VERSION "ZCU_CANFD1"

NS_ :

BS_ :

BU_ :  ASDM BBM ETC IHU ZCUD ZCUP

BO_ 1384 BcmZCUCANFD1VFCVectFr : 8 BBM
 SG_ VFCVectorBCMBlockID : 1|2@0+ (1.0,0.0) [0.0|3.0] "Unitless" IHU
 SG_ VFCVectorBCMVFCid0 : 2|1@0+ (1,0) [0|1] "" IHU
 SG_ VFCVectorBCMVFCid1 : 3|1@0+ (1,0) [0|1] "" IHU
 SG_ VFCVectorBCMVFCid10 : 12|1@0+ (1,0) [0|1] "" IHU
 SG_ VFCVectorBCMVFCid11 : 13|1@0+ (1,0) [0|1] "" IHU
 SG_ VFCVectorBCMVFCid12 : 14|1@0+ (1,0) [0|1] "" IHU
 SG_ VFCVectorBCMVFCid13 : 15|1@0+ (1,0) [0|1] "" IHU
 SG_ VFCVectorBCMVFCid14 : 16|1@0+ (1,0) [0|1] "" IHU
 SG_ VFCVectorBCMVFCid15 : 17|1@0+ (1,0) [0|1] "" IHU
 SG_ VFCVectorBCMVFCid16 : 18|1@0+ (1,0) [0|1] "" IHU
 SG_ VFCVectorBCMVFCid17 : 19|1@0+ (1,0) [0|1] "" IHU
 SG_ VFCVectorBCMVFCid18 : 20|1@0+ (1,0) [0|1] "" IHU
 SG_ VFCVectorBCMVFCid19 : 21|1@0+ (1,0) [0|1] "" IHU
 SG_ VFCVectorBCMVFCid2 : 4|1@0+ (1,0) [0|1] "" IHU
 SG_ VFCVectorBCMVFCid20 : 22|1@0+ (1,0) [0|1] "" IHU
 SG_ VFCVectorBCMVFCid21 : 23|1@0+ (1,0) [0|1] "" IHU
 SG_ VFCVectorBCMVFCid22 : 24|1@0+ (1,0) [0|1] "" IHU
 SG_ VFCVectorBCMVFCid23 : 25|1@0+ (1,0) [0|1] "" IHU
 SG_ VFCVectorBCMVFCid24 : 26|1@0+ (1,0) [0|1] "" IHU
 SG_ VFCVectorBCMVFCid25 : 27|1@0+ (1,0) [0|1] "" IHU
 SG_ VFCVectorBCMVFCid26 : 28|1@0+ (1,0) [0|1] "" IHU
 SG_ VFCVectorBCMVFCid27 : 29|1@0+ (1,0) [0|1] "" IHU
 SG_ VFCVectorBCMVFCid28 : 30|1@0+ (1,0) [0|1] "" IHU
 SG_ VFCVectorBCMVFCid29 : 31|1@0+ (1,0) [0|1] "" IHU
 SG_ VFCVectorBCMVFCid3 : 5|1@0+ (1,0) [0|1] "" IHU
 SG_ VFCVectorBCMVFCid30 : 32|1@0+ (1,0) [0|1] "" IHU
 SG_ VFCVectorBCMVFCid31 : 33|1@0+ (1,0) [0|1] "" IHU
 SG_ VFCVectorBCMVFCid32 : 34|1@0+ (1,0) [0|1] "" IHU
 SG_ VFCVectorBCMVFCid33 : 35|1@0+ (1,0) [0|1] "" IHU
 SG_ VFCVectorBCMVFCid34 : 36|1@0+ (1,0) [0|1] "" IHU
 SG_ VFCVectorBCMVFCid35 : 37|1@0+ (1,0) [0|1] "" IHU
 SG_ VFCVectorBCMVFCid36 : 38|1@0+ (1,0) [0|1] "" IHU
 SG_ VFCVectorBCMVFCid37 : 39|1@0+ (1,0) [0|1] "" IHU
 SG_ VFCVectorBCMVFCid38 : 40|1@0+ (1,0) [0|1] "" IHU
 SG_ VFCVectorBCMVFCid39 : 41|1@0+ (1,0) [0|1] "" IHU
 SG_ VFCVectorBCMVFCid4 : 6|1@0+ (1,0) [0|1] "" IHU
 SG_ VFCVectorBCMVFCid40 : 42|1@0+ (1,0) [0|1] "" IHU
 SG_ VFCVectorBCMVFCid41 : 43|1@0+ (1,0) [0|1] "" IHU
 SG_ VFCVectorBCMVFCid42 : 44|1@0+ (1,0) [0|1] "" IHU
 SG_ VFCVectorBCMVFCid43 : 45|1@0+ (1,0) [0|1] "" IHU
 SG_ VFCVectorBCMVFCid44 : 46|1@0+ (1,0) [0|1] "" IHU
 SG_ VFCVectorBCMVFCid45 : 47|1@0+ (1,0) [0|1] "" IHU
 SG_ VFCVectorBCMVFCid46 : 48|1@0+ (1,0) [0|1] "" IHU
 SG_ VFCVectorBCMVFCid47 : 49|1@0+ (1,0) [0|1] "" IHU
 SG_ VFCVectorBCMVFCid48 : 50|1@0+ (1,0) [0|1] "" IHU
 SG_ VFCVectorBCMVFCid49 : 51|1@0+ (1,0) [0|1] "" IHU
 SG_ VFCVectorBCMVFCid5 : 7|1@0+ (1,0) [0|1] "" IHU
 SG_ VFCVectorBCMVFCid50 : 52|1@0+ (1,0) [0|1] "" IHU
 SG_ VFCVectorBCMVFCid51 : 53|1@0+ (1,0) [0|1] "" IHU
 SG_ VFCVectorBCMVFCid52 : 54|1@0+ (1,0) [0|1] "" IHU
 SG_ VFCVectorBCMVFCid53 : 55|1@0+ (1,0) [0|1] "" IHU
 SG_ VFCVectorBCMVFCid54 : 56|1@0+ (1,0) [0|1] "" IHU
 SG_ VFCVectorBCMVFCid55 : 57|1@0+ (1,0) [0|1] "" IHU
 SG_ VFCVectorBCMVFCid56 : 58|1@0+ (1,0) [0|1] "" IHU
 SG_ VFCVectorBCMVFCid57 : 59|1@0+ (1,0) [0|1] "" IHU
 SG_ VFCVectorBCMVFCid58 : 60|1@0+ (1,0) [0|1] "" IHU
 SG_ VFCVectorBCMVFCid59 : 61|1@0+ (1,0) [0|1] "" IHU
 SG_ VFCVectorBCMVFCid6 : 8|1@0+ (1,0) [0|1] "" IHU
 SG_ VFCVectorBCMVFCid60 : 62|1@0+ (1,0) [0|1] "" IHU
 SG_ VFCVectorBCMVFCid61 : 63|1@0+ (1,0) [0|1] "" IHU
 SG_ VFCVectorBCMVFCid7 : 9|1@0+ (1,0) [0|1] "" IHU
 SG_ VFCVectorBCMVFCid8 : 10|1@0+ (1,0) [0|1] "" IHU
 SG_ VFCVectorBCMVFCid9 : 11|1@0+ (1,0) [0|1] "" IHU

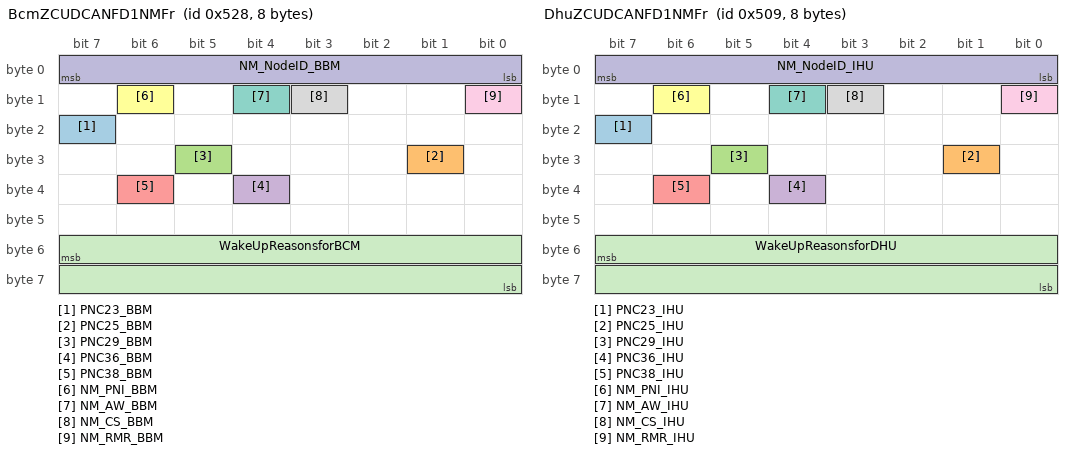
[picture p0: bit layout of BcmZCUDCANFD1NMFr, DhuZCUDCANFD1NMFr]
BO_ 1320 BcmZCUDCANFD1NMFr : 8 BBM
 SG_ PNC23_BBM : 23|1@0+ (1,0) [0|0] "" Vector__XXX
 SG_ PNC25_BBM : 25|1@0+ (1,0) [0|0] "" Vector__XXX
 SG_ PNC29_BBM : 29|1@0+ (1,0) [0|0] "" Vector__XXX
 SG_ PNC36_BBM : 36|1@0+ (1,0) [0|0] "" Vector__XXX
 SG_ PNC38_BBM : 38|1@0+ (1,0) [0|0] "" Vector__XXX
 SG_ NM_PNI_BBM : 14|1@0+ (1,0) [0|0] "" Vector__XXX
 SG_ NM_AW_BBM : 12|1@0+ (1,0) [0|0] "" Vector__XXX
 SG_ NM_CS_BBM : 11|1@0+ (1,0) [0|0] "" Vector__XXX
 SG_ NM_RMR_BBM : 8|1@0+ (1,0) [0|0] "" Vector__XXX
 SG_ NM_NodeID_BBM : 7|8@0+ (1,0) [0|0] "" Vector__XXX

 SG_ WakeUpReasonsforBCM : 55|16@0+ (1,0) [0|65535] "" Vector__XXX

BO_ 87 DhuToAdcuSecOCFr01 : 64 IHU
 SG_ DrvrACCrsSetSpdReq_UB : 28|1@0+ (1,0) [0|1] "" ASDM
 SG_ DrvrACCrsSetSpdReqDrvrACCrsCtrlSetInSpdReq : 7|12@0+ (0.03125,0.0) [0.0|125.0] "m/s" ASDM
 SG_ DrvrACCrsSetSpdReqDrvrCrsSetSpdReq : 31|3@0+ (1,0) [0|7] "" ASDM
 SG_ DrvrACCrsSetSpdReqSetSpdForCrsCtrlFctActive : 11|12@0+ (0.03125,0.0) [0.0|125.0] "m/s" ASDM

BO_ 2015 DhuToAllFuncJ1979OBDZCUCanFD1ReqFr : 8 IHU

BO_ 2047 DhuToAllFuncZCUCANFD1DiagReqFr : 8 IHU

BO_ 1860 DhuToAsdmFlrZCUCANFD1DiagReqFr : 64 IHU

BO_ 1841 DhuToAsdmFsrlZCUCANFD1DiagReqFr : 64 IHU

BO_ 1840 DhuToAsdmFsrrZCUCANFD1DiagReqFr : 64 IHU

BO_ 1872 DhuToAsdmSodlZCUCANFD1DiagReqFr : 64 IHU

BO_ 1873 DhuToAsdmSodrZCUCANFD1DiagReqFr : 64 IHU

BO_ 1793 DhuToAsdmZCUCANFD1DiagReqFr : 64 IHU

BO_ 2023 DhuToBcmJ1979OBDZCUCanFD1ReqFr : 8 IHU

BO_ 1921 DhuToBcmZCUCANFD1DiagReqFr : 64 IHU

BO_ 1925 DhuToPasZCUCANFD1DiagReqFr : 64 IHU

BO_ 1889 DhuToZcudBmsZCUCANFD1DiagReqFr : 64 IHU

BO_ 1808 DhuToZcudEcmZCUCANFD1DiagReqFr : 64 IHU

BO_ 1891 DhuToZcudGcmZCUCANFD1DiagReqFr : 64 IHU

BO_ 1904 DhuToZcudPscmZCUCANFD1DiagReqFr : 64 IHU

BO_ 1811 DhuToZcudRbcmZCUCANFD1DiagReqFr : 64 IHU

BO_ 1906 DhuToZcudSasZCUCANFD1DiagReqFr : 64 IHU

BO_ 1813 DhuToZcudSclZCUCANFD1DiagReqFr : 64 IHU

BO_ 1812 DhuToZcudSumZCUCANFD1DiagReqFr : 64 IHU

BO_ 1826 DhuToZcudWpcZCUCANFD1DiagReqFr : 64 IHU

BO_ 1810 DhuToZcudXcuZCUCANFD1DiagReqFr : 64 IHU

BO_ 488 DhuZCUCANFD1Fr01 : 64 IHU
 SG_ AsyEmgyManoeuvreAidActvSts : 491|1@0+ (1,0) [0|1] "" ASDM
 SG_ AsyEmgyManoeuvreAidActvSts_UB : 490|1@0+ (1,0) [0|1] "" ASDM
 SG_ AsyNoaUpgradeswitch : 489|1@0+ (1,0) [0|1] "" ASDM
 SG_ AsyNoaUpgradeswitch_UB : 488|1@0+ (1,0) [0|1] "" ASDM
 SG_ BSDSwOnOffandWarnType : 35|2@0+ (1,0) [0|3] "" ASDM
 SG_ BSDSwOnOffandWarnType_UB : 24|1@0+ (1,0) [0|1] "" ASDM
 SG_ CamFltsStsFromDHU : 487|2@0+ (1,0) [0|3] "" ASDM
 SG_ CamFltsStsFromDHU_UB : 485|1@0+ (1,0) [0|1] "" ASDM
 SG_ CllsnAidSnvtySeldSts : 482|3@0+ (1,0) [0|7] "" ASDM
 SG_ CllsnAidSnvtySeldSts_UB : 483|1@0+ (1,0) [0|1] "" ASDM
 SG_ CllsnMtgtnActvSeldSts : 495|1@0+ (1,0) [0|1] "" ASDM
 SG_ CllsnMtgtnActvSeldSts_UB : 484|1@0+ (1,0) [0|1] "" ASDM
 SG_ CmftBrkStopSwtSts : 494|1@0+ (1,0) [0|1] "" BBM
 SG_ CmftBrkStopSwtSts_UB : 312|1@0+ (1,0) [0|1] "" BBM
 SG_ CrsCtrlTiGapAdjReq : 499|3@0+ (1,0) [0|7] "" ASDM
 SG_ CrsCtrlTiGapAdjReq_UB : 496|1@0+ (1,0) [0|1] "" ASDM
 SG_ CurrentRoadLvl : 39|4@0+ (1,0) [0|15] "" ASDM,ZCUD
 SG_ CurrentRoadLvl_UB : 25|1@0+ (1,0) [0|1] "" ASDM,ZCUD
 SG_ DrvOffReq : 27|1@0+ (1,0) [0|1] "" ASDM
 SG_ DrvOffReq_UB : 26|1@0+ (1,0) [0|1] "" ASDM
 SG_ DrvrCrsCtrlFctActvReq : 493|2@0+ (1,0) [0|3] "" ASDM
 SG_ DrvrCrsCtrlFctActvReq_UB : 508|1@0+ (1,0) [0|1] "" ASDM
 SG_ DrvrDecStsFromDHU : 511|3@0+ (1,0) [0|7] "" ASDM
 SG_ DrvrDecStsFromDHU_UB : 507|1@0+ (1,0) [0|1] "" ASDM
 SG_ DrvrPfmncAlrmReqFromDHU : 59|3@0+ (1,0) [0|7] "" ASDM,ZCUD,ZCUP
 SG_ DrvrPfmncAlrmReqFromDHU_UB : 506|1@0+ (1,0) [0|1] "" ASDM,ZCUD,ZCUP
 SG_ DrvrPfmncSwitchStsFromDHU : 71|3@0+ (1,0) [0|7] "" ASDM
 SG_ DrvrPfmncSwitchStsFromDHU_UB : 505|1@0+ (1,0) [0|1] "" ASDM
 SG_ EmgyLaneKeepAidActvSts : 56|1@0+ (1,0) [0|1] "" ASDM
 SG_ EmgyLaneKeepAidActvSts_UB : 504|1@0+ (1,0) [0|1] "" ASDM
 SG_ EyeGazeDirVecFromDHU_UB : 68|1@0+ (1,0) [0|1] "" ASDM
 SG_ EyeGazeDirVecFromDHUX : 79|16@0+ (1.0,-32767.0) [-32767.0|32768.0] "Unitless" ASDM
 SG_ EyeGazeDirVecFromDHUY : 95|16@0+ (1.0,-32767.0) [-32767.0|32768.0] "Unitless" ASDM
 SG_ EyeGazeDirVecFromDHUZ : 111|16@0+ (1.0,-32767.0) [-32767.0|32768.0] "Unitless" ASDM
 SG_ EyeGazeFromDHU_UB : 67|1@0+ (1,0) [0|1] "" ASDM
 SG_ EyeGazeFromDHUEyeGazeZone : 143|5@0+ (1,0) [0|31] "" ASDM
 SG_ EyeGazeFromDHUEyeGazeZoneTime : 127|16@0+ (1.0,0.0) [0.0|65535.0] "Milliseconds" ASDM
 SG_ EyeGzaeDirOriFromDHU_UB : 66|1@0+ (1,0) [0|1] "" ASDM
 SG_ EyeGzaeDirOriFromDHUX : 151|16@0+ (1.0,-32767.0) [-32767.0|32768.0] "mm" ASDM
 SG_ EyeGzaeDirOriFromDHUY : 167|16@0+ (1.0,-32767.0) [-32767.0|32768.0] "mm" ASDM
 SG_ EyeGzaeDirOriFromDHUZ : 183|16@0+ (1.0,-32767.0) [-32767.0|32768.0] "mm" ASDM
 SG_ EyeOnRoadFromDHU_UB : 65|1@0+ (1,0) [0|1] "" ASDM
 SG_ EyeOnRoadFromDHUChks : 199|8@0+ (1.0,0.0) [0.0|255.0] "Unitless" ASDM
 SG_ EyeOnRoadFromDHUCntr : 207|4@0+ (1.0,0.0) [0.0|15.0] "Unitless" ASDM
 SG_ EyeOnRoadFromDHUEyesOnRoad : 203|2@0+ (1,0) [0|3] "" ASDM
 SG_ EyeOpenFromDHU_UB : 64|1@0+ (1,0) [0|1] "" ASDM
 SG_ EyeOpenFromDHUEyeOpenDegLe : 215|8@0+ (0.1,0.0) [0.0|25.5] "mm" ASDM
 SG_ EyeOpenFromDHUEyeOpenDegRi : 223|8@0+ (0.1,0.0) [0.0|25.5] "mm" ASDM
 SG_ EyeOpenFromDHUEyeOpenLe : 231|1@0+ (1,0) [0|1] "" ASDM
 SG_ EyeOpenFromDHUEyeOpenRi : 230|1@0+ (1,0) [0|1] "" ASDM
 SG_ EyeOpenFromDHUEyeVisibleLe : 229|1@0+ (1,0) [0|1] "" ASDM
 SG_ EyeOpenFromDHUEyeVisibleRi : 228|1@0+ (1,0) [0|1] "" ASDM
 SG_ EyeOpenFromDHUFaceVisible : 227|1@0+ (1,0) [0|1] "" ASDM
 SG_ HdPosnValidSigFromDHU_UB : 201|1@0+ (1,0) [0|1] "" ASDM
 SG_ HdPosnValidSigFromDHUX : 239|16@0+ (1.0,-32767.0) [-32767.0|32768.0] "mm" ASDM
 SG_ HdPosnValidSigFromDHUY : 255|16@0+ (1.0,-32767.0) [-32767.0|32768.0] "mm" ASDM
 SG_ HdPosnValidSigFromDHUZ : 271|16@0+ (1.0,-32767.0) [-32767.0|32768.0] "mm" ASDM
 SG_ HdRotateAgFromDHU_UB : 200|1@0+ (1,0) [0|1] "" ASDM
 SG_ HdRotateAgFromDHUHdPitchAg : 287|11@0+ (0.1,-90.0) [-90.0|90.0] "Deg" ASDM
 SG_ HdRotateAgFromDHUHdRollAg : 292|11@0+ (0.1,-90.0) [-90.0|90.0] "Deg" ASDM
 SG_ HdRotateAgFromDHUHdYawAg : 311|11@0+ (0.1,-90.0) [-90.0|90.0] "Deg" ASDM
 SG_ HeadGazeDirOriFromDHU_UB : 138|1@0+ (1,0) [0|1] "" ASDM
 SG_ HeadGazeDirOriFromDHUX : 327|16@0+ (1.0,-32767.0) [-32767.0|32768.0] "mm" ASDM
 SG_ HeadGazeDirOriFromDHUY : 343|16@0+ (1.0,-32767.0) [-32767.0|32768.0] "mm" ASDM
 SG_ HeadGazeDirOriFromDHUZ : 359|16@0+ (1.0,-32767.0) [-32767.0|32768.0] "mm" ASDM
 SG_ HeadGazeDirVecFromDHU_UB : 137|1@0+ (1,0) [0|1] "" ASDM
 SG_ HeadGazeDirVecFromDHUX : 375|16@0+ (1.0,-32767.0) [-32767.0|32768.0] "Unitless" ASDM
 SG_ HeadGazeDirVecFromDHUY : 391|16@0+ (1.0,-32767.0) [-32767.0|32768.0] "Unitless" ASDM
 SG_ HeadGazeDirVecFromDHUZ : 407|16@0+ (1.0,-32767.0) [-32767.0|32768.0] "Unitless" ASDM
 SG_ HmiDrvrSodReqPilot : 316|1@0+ (1,0) [0|1] "" ASDM
 SG_ HmiDrvrSodReqPilot_UB : 315|1@0+ (1,0) [0|1] "" ASDM
 SG_ HznPosn_UB : 136|1@0+ (1,0) [0|1] "" ASDM
 SG_ HznPosnCurrentLane : 423|3@0+ (1.0,0.0) [0.0|7.0] "Unitless" ASDM
 SG_ HznPosnCyclicCounter : 420|2@0+ (1.0,0.0) [0.0|3.0] "Unitless" ASDM
 SG_ HznPosnMessageType : 418|3@0+ (1,0) [0|7] "" ASDM
 SG_ HznPosnOffset : 431|13@0+ (1.0,0.0) [0.0|8191.0] "m" ASDM
 SG_ HznPosnPathIndex : 447|6@0+ (1.0,0.0) [0.0|63.0] "Unitless" ASDM
 SG_ HznPosnPositionAge : 455|9@0+ (1.0,0.0) [0.0|511.0] "Milliseconds" ASDM
 SG_ HznPosnPositionConfidence : 434|3@0+ (1.0,0.0) [0.0|7.0] "Unitless" ASDM
 SG_ HznPosnPositionIndex : 441|2@0+ (1.0,0.0) [0.0|3.0] "Unitless" ASDM
 SG_ HznPosnPositionProbability : 462|5@0+ (1.0,0.0) [0.0|31.0] "%" ASDM
 SG_ HznPosnRelativeHeading : 479|8@0+ (1.0,0.0) [0.0|255.0] "Unitless" ASDM
 SG_ HznPosnSpeed : 456|9@0+ (1.0,0.0) [0.0|511.0] "m/s" ASDM
 SG_ NavForDrvrPfmncStsFromDHU : 226|3@0+ (1,0) [0|7] "" ASDM
 SG_ NavForDrvrPfmncStsFromDHU_UB : 500|1@0+ (1,0) [0|1] "" ASDM
 SG_ RemCtrlVehSts : 54|4@0+ (1,0) [0|15] "" ASDM,ZCUD
 SG_ RemCtrlVehSts_UB : 50|1@0+ (1,0) [0|1] "" ASDM,ZCUD

BO_ 775 DhuZCUCANFD1Fr02 : 64 IHU
 SG_ FogSetReReq : 2|2@0+ (1,0) [0|3] "" ASDM,ZCUD
 SG_ FogSetReReq_UB : 3|1@0+ (1,0) [0|1] "" ASDM,ZCUD
 SG_ GNSSSolution_UB : 168|1@0+ (1,0) [0|1] "" ASDM,BBM
 SG_ GNSSSolution1_UB : 274|1@0+ (1,0) [0|1] "" ASDM
 SG_ GNSSSolution1Cntr : 287|3@0+ (1.0,0.0) [0.0|7.0] "Unitless" ASDM
 SG_ GNSSSolution1NoOfSatItForSysNo1 : 284|5@0+ (1.0,0.0) [0.0|31.0] "Unitless" ASDM
 SG_ GNSSSolution1NoOfSatItForSysNo2 : 295|5@0+ (1.0,0.0) [0.0|31.0] "Unitless" ASDM
 SG_ GNSSSolution1NoOfSatItForSysNo3 : 303|5@0+ (1.0,0.0) [0.0|31.0] "Unitless" ASDM
 SG_ GNSSSolution1NoOfSatItForSysNo4 : 311|5@0+ (1.0,0.0) [0.0|31.0] "Unitless" ASDM
 SG_ GNSSSolution1NoOfSatItForSysNo5 : 319|5@0+ (1.0,0.0) [0.0|31.0] "Unitless" ASDM
 SG_ GNSSSolution1NoOfSatItForSysNo6 : 327|5@0+ (1.0,0.0) [0.0|31.0] "Unitless" ASDM
 SG_ GNSSSolution1NoOfSatItForSysNo7 : 335|5@0+ (1.0,0.0) [0.0|31.0] "Unitless" ASDM
 SG_ GNSSSolution1SatItSysNo1InUse : 290|1@0+ (1,0) [0|1] "" ASDM
 SG_ GNSSSolution1SatItSysNo2InUse : 289|1@0+ (1,0) [0|1] "" ASDM
 SG_ GNSSSolution1SatItSysNo3InUse : 288|1@0+ (1,0) [0|1] "" ASDM
 SG_ GNSSSolution1SatItSysNo4InUse : 298|1@0+ (1,0) [0|1] "" ASDM
 SG_ GNSSSolution1SatItSysNo5InUse : 297|1@0+ (1,0) [0|1] "" ASDM
 SG_ GNSSSolution1SatItSysNo6InUse : 296|1@0+ (1,0) [0|1] "" ASDM
 SG_ GNSSSolution1SatItSysNo7InUse : 306|1@0+ (1,0) [0|1] "" ASDM
 SG_ GNSSSolution1SatltPosnStsPrm1 : 305|2@0+ (1,0) [0|3] "" ASDM
 SG_ GNSSSolution1SatltPosnStsPrm2 : 314|1@0+ (1,0) [0|1] "" ASDM
 SG_ GNSSSolution2_UB : 273|1@0+ (1,0) [0|1] "" ASDM
 SG_ GNSSSolution2Cntr : 330|3@0+ (1.0,0.0) [0.0|7.0] "Unitless" ASDM
 SG_ GNSSSolution2PreHozlDil : 343|8@0+ (0.1,0.0) [0.0|25.5] "Unitless" ASDM
 SG_ GNSSSolution2PrePosnDil : 351|8@0+ (0.1,0.0) [0.0|25.5] "Unitless" ASDM
 SG_ GNSSSolution2PreVertDil : 359|8@0+ (0.1,0.0) [0.0|25.5] "Unitless" ASDM
 SG_ GNSSSolutionCntr : 183|3@0+ (1.0,0.0) [0.0|7.0] "Unitless" ASDM,BBM
 SG_ GNSSSolutionNoOfSatltForSysNo1 : 180|5@0+ (1.0,0.0) [0.0|31.0] "Unitless" ASDM,BBM
 SG_ GNSSSolutionNoOfSatltForSysNo2 : 191|5@0+ (1.0,0.0) [0.0|31.0] "Unitless" ASDM,BBM
 SG_ GNSSSolutionNoOfSatltForSysNo3 : 199|5@0+ (1.0,0.0) [0.0|31.0] "Unitless" ASDM,BBM
 SG_ GNSSSolutionNoOfSatltForSysNo4 : 207|5@0+ (1.0,0.0) [0.0|31.0] "Unitless" ASDM,BBM
 SG_ GNSSSolutionNoOfSatltForSysNo5 : 215|5@0+ (1.0,0.0) [0.0|31.0] "Unitless" ASDM,BBM
 SG_ GNSSSolutionNoOfSatltForSysNo6 : 271|5@0+ (1.0,0.0) [0.0|31.0] "Unitless" ASDM,BBM
 SG_ GNSSSolutionNoOfSatltForSysNo7 : 279|5@0+ (1.0,0.0) [0.0|31.0] "Unitless" ASDM,BBM
 SG_ GNSSSolutionPreHozlDil : 231|8@0+ (0.1,0.0) [0.0|25.5] "Unitless" ASDM,BBM
 SG_ GNSSSolutionPrePosnDil : 239|8@0+ (0.1,0.0) [0.0|25.5] "Unitless" ASDM,BBM
 SG_ GNSSSolutionPreVertDil : 247|8@0+ (0.1,0.0) [0.0|25.5] "Unitless" ASDM,BBM
 SG_ GNSSSolutionSatltPosnStsPrm1 : 186|2@0+ (1,0) [0|3] "" ASDM,BBM
 SG_ GNSSSolutionSatltPosnStsPrm2 : 184|1@0+ (1,0) [0|1] "" ASDM,BBM
 SG_ GNSSSolutionSatltSysNo1InUse : 194|1@0+ (1,0) [0|1] "" ASDM,BBM
 SG_ GNSSSolutionSatltSysNo2InUse : 193|1@0+ (1,0) [0|1] "" ASDM,BBM
 SG_ GNSSSolutionSatltSysNo3InUse : 192|1@0+ (1,0) [0|1] "" ASDM,BBM
 SG_ GNSSSolutionSatltSysNo4InUse : 202|1@0+ (1,0) [0|1] "" ASDM,BBM
 SG_ GNSSSolutionSatltSysNo5InUse : 201|1@0+ (1,0) [0|1] "" ASDM,BBM
 SG_ GNSSSolutionSatltSysNo6InUse : 200|1@0+ (1,0) [0|1] "" ASDM,BBM
 SG_ GNSSSolutionSatltSysNo7InUse : 210|1@0+ (1,0) [0|1] "" ASDM,BBM
 SG_ GNSSSolutionTiForMins : 255|6@0+ (1.0,0.0) [0.0|59.0] "Mins" ASDM,BBM
 SG_ GNSSSolutionTiForMsec : 209|10@0+ (1.0,0.0) [0.0|1023.0] "Unitless" ASDM,BBM
 SG_ GNSSSolutionTiForSec : 263|6@0+ (1.0,0.0) [0.0|59.0] "s" ASDM,BBM
 SG_ PosnFromSatlt1_UB : 484|1@0+ (1,0) [0|1] "" ASDM
 SG_ PosnFromSatlt1Cntr : 487|3@0+ (1.0,0.0) [0.0|7.0] "Unitless" ASDM
 SG_ PosnFromSatlt1PosnLat : 455|30@0- (0.000000277778,0.0) [-90.000072|90.000072] "Deg" ASDM
 SG_ PosnFromSatlt1PosnLgt : 422|31@0- (0.000000277778,0.0) [-180.000144|180.000144] "Deg" ASDM
 SG_ ScenarioMod : 59|4@0+ (1,0) [0|15] "" ZCUD
 SG_ ScenarioMod_UB : 60|1@0+ (1,0) [0|1] "" ZCUD
 SG_ SpplTrfcSgnInfoFromNavMap : 399|5@0+ (1,0) [0|31] "" ASDM
 SG_ SpplTrfcSgnInfoFromNavMap_UB : 386|1@0+ (1,0) [0|1] "" ASDM
 SG_ VstdModeSts : 74|3@0+ (1,0) [0|7] "" ZCUD
 SG_ VstdModeSts_UB : 8|1@0+ (1,0) [0|1] "" ZCUD

BO_ 86 DhuZCUCANFD1Fr03 : 64 IHU
 SG_ AsyAutDrvCtrlTypDIMReq : 7|3@0+ (1,0) [0|7] "" ASDM
 SG_ AsyAutDrvCtrlTypDIMReq_UB : 4|1@0+ (1,0) [0|1] "" ASDM
 SG_ BiasedPosnFromSatlt_UB : 62|1@0+ (1,0) [0|1] "" ASDM
 SG_ BiasedPosnFromSatltCntr : 191|3@0+ (1.0,0.0) [0.0|7.0] "Unitless" ASDM
 SG_ BiasedPosnFromSatltPosnLat : 103|30@0- (0.000000277778,0.0) [-90.000072|90.000072] "Deg" ASDM
 SG_ BiasedPosnFromSatltPosnLgt : 143|31@0- (0.000000277778,0.0) [-180.000144|180.000144] "Deg" ASDM
 SG_ BiasedPosnFromSatltTiForMins : 175|6@0+ (1.0,0.0) [0.0|59.0] "Mins" ASDM
 SG_ BiasedPosnFromSatltTiForMsec : 121|10@0+ (1.0,0.0) [0.0|1023.0] "Unitless" ASDM
 SG_ BiasedPosnFromSatltTiForSec : 183|6@0+ (1.0,0.0) [0.0|59.0] "s" ASDM
 SG_ DrvModReq : 3|4@0+ (1,0) [0|15] "" ASDM,BBM,ZCUD,ZCUP
 SG_ DrvModReq_UB : 15|1@0+ (1,0) [0|1] "" ASDM,BBM,ZCUD,ZCUP
 SG_ EpbSoftSwtCtrlSt : 47|3@0+ (1,0) [0|7] "" ZCUD
 SG_ EpbSoftSwtCtrlSt_UB : 12|1@0+ (1,0) [0|1] "" ZCUD
 SG_ FuLvlIndcd_UB : 188|1@0+ (1,0) [0|1] "" BBM,ZCUD
 SG_ FuLvlIndcdFuLvlValFromFuTbl : 185|10@0+ (0.2,0.0) [0.0|204.60000000000002] "Litre" BBM,ZCUD
 SG_ FuLvlIndcdGenQF : 187|2@0+ (1,0) [0|3] "" BBM,ZCUD
 SG_ GpsStatus : 14|1@0+ (1,0) [0|1] "" ZCUP
 SG_ GpsStatus_UB : 13|1@0+ (1,0) [0|1] "" ZCUP
 SG_ IntvAndWarnModForLaneKeepAidSts : 207|2@0+ (1,0) [0|3] "" ASDM
 SG_ IntvAndWarnModForLaneKeepAidSts_UB : 205|1@0+ (1,0) [0|1] "" ASDM
 SG_ SetLimReq : 204|2@0+ (1,0) [0|3] "" BBM,ZCUD
 SG_ SetLimReq_UB : 202|1@0+ (1,0) [0|1] "" BBM,ZCUD
 SG_ SpdLimdSts : 201|1@0+ (1,0) [0|1] "" BBM
 SG_ SpdLimdSts_UB : 200|1@0+ (1,0) [0|1] "" BBM
 SG_ VBFsetg : 215|2@0+ (1,0) [0|3] "" BBM
 SG_ VBFsetg_UB : 213|1@0+ (1,0) [0|1] "" BBM

BO_ 373 DhuZCUCANFD1Fr04 : 64 IHU
 SG_ AutoHldSoftSwtCtrlSt : 7|1@0+ (1,0) [0|1] "" BBM
 SG_ AutoHldSoftSwtCtrlSt_UB : 6|1@0+ (1,0) [0|1] "" BBM
 SG_ CrossInfo_UB : 91|1@0+ (1,0) [0|1] "" ASDM
 SG_ CrossInfoDirOfNavRut : 359|4@0+ (1,0) [0|15] "" ASDM
 SG_ CrossInfoDstToCros : 336|9@0+ (1.0,0.0) [0.0|511.0] "m" ASDM
 SG_ CrossInfoTrfcLi : 355|1@0+ (1,0) [0|1] "" ASDM
 SG_ CtraSwOnOff : 88|1@0+ (1,0) [0|1] "" ASDM
 SG_ CtraSwOnOff_UB : 90|1@0+ (1,0) [0|1] "" ASDM
 SG_ DIMStsDistbn : 103|3@0+ (1,0) [0|7] "" ASDM
 SG_ DIMStsDistbn_UB : 89|1@0+ (1,0) [0|1] "" ASDM
 SG_ DOWSwOnOff : 100|1@0+ (1,0) [0|1] "" ASDM
 SG_ DOWSwOnOff_UB : 99|1@0+ (1,0) [0|1] "" ASDM
 SG_ DrvrACCFctDeactvnReq_UB : 98|1@0+ (1,0) [0|1] "" ASDM
 SG_ DrvrACCFctDeactvnReqChks : 111|8@0+ (1.0,0.0) [0.0|255.0] "Unitless" ASDM
 SG_ DrvrACCFctDeactvnReqCntr : 119|4@0+ (1.0,0.0) [0.0|15.0] "Unitless" ASDM
 SG_ DrvrACCFctDeactvnReqSts : 96|1@0+ (1,0) [0|1] "" ASDM
 SG_ DrvrLaneChgAutActvSts : 115|1@0+ (1,0) [0|1] "" ASDM
 SG_ DrvrLaneChgAutActvSts_UB : 114|1@0+ (1,0) [0|1] "" ASDM
 SG_ HmiDrvrSodReqChg : 133|2@0+ (1,0) [0|3] "" ASDM
 SG_ HmiDrvrSodReqChg_UB : 131|1@0+ (1,0) [0|1] "" ASDM
 SG_ HmiSodLanChgSwitch : 130|1@0+ (1,0) [0|1] "" ASDM
 SG_ HmiSodLanChgSwitch_UB : 129|1@0+ (1,0) [0|1] "" ASDM
 SG_ HmiStrangerModMenuSet_UB : 128|1@0+ (1,0) [0|1] "" BBM
 SG_ HmiStrangerModMenuSetActvInActv : 151|1@0+ (1,0) [0|1] "" BBM
 SG_ HmiStrangerModMenuSetPasswordSt : 150|1@0+ (1,0) [0|1] "" BBM
 SG_ HmiStrangerModMenuSetPrivateLockSt : 149|1@0+ (1,0) [0|1] "" BBM
 SG_ HmiStrangerModMenuSetSpdLim : 143|8@0+ (1.0,0.0) [0.0|255.0] "Unitless" BBM
 SG_ MobDevRPAReq1_UB : 144|1@0+ (1,0) [0|1] "" ZCUD
 SG_ MobDevRPAReq1Chks : 191|8@0+ (1.0,0.0) [0.0|255.0] "Unitless" ZCUD
 SG_ MobDevRPAReq1Cntr : 199|4@0+ (1.0,0.0) [0.0|15.0] "Unitless" ZCUD
 SG_ MobDevRPAReq1MobDevSts : 207|8@0+ (1.0,0.0) [0.0|255.0] "Unitless" ZCUD
 SG_ MobDevRPAReq1RPAOutModeSubT : 195|4@0+ (1,0) [0|15] "" ZCUD
 SG_ MobDevRPAReq1RPAReq : 215|4@0+ (1,0) [0|15] "" ZCUD
 SG_ MobDevRPAReq1RSPACtrl : 211|3@0+ (1,0) [0|7] "" ZCUD
 SG_ PlannedPahDe : 339|2@0+ (1,0) [0|3] "" ASDM,ZCUD
 SG_ PlannedPahDe_UB : 337|1@0+ (1,0) [0|1] "" ASDM,ZCUD
 SG_ SetSpdForCrsCtrlFct : 335|12@0+ (0.03125,0.0) [0.0|125.0] "m/s" BBM,ZCUD
 SG_ SetSpdForCrsCtrlFct_UB : 354|1@0+ (1,0) [0|1] "" BBM,ZCUD
 SG_ SpdCamFromNavMap : 327|8@0+ (1.0,-1.0) [-1.0|254.0] "Km/h" ASDM
 SG_ SpdCamFromNavMap_UB : 353|1@0+ (1,0) [0|1] "" ASDM
 SG_ SpdLimOfRoad : 319|8@0+ (1.0,-1.0) [-1.0|254.0] "Km/h" ASDM,ZCUD
 SG_ SpdLimOfRoad_UB : 352|1@0+ (1,0) [0|1] "" ASDM,ZCUD
 SG_ VehCfgPrm_UB : 244|1@0+ (1,0) [0|1] "" ASDM,BBM,ZCUD,ZCUP
 SG_ VehCfgPrmBlkIDBytePosn1 : 255|8@0+ (1.0,0.0) [0.0|255.0] "Unitless" ASDM,BBM,ZCUD,ZCUP
 SG_ VehCfgPrmCCPBytePosn2 : 263|8@0+ (1.0,0.0) [0.0|255.0] "Unitless" ASDM,BBM,ZCUD,ZCUP
 SG_ VehCfgPrmCCPBytePosn3 : 271|8@0+ (1.0,0.0) [0.0|255.0] "Unitless" ASDM,BBM,ZCUD,ZCUP
 SG_ VehCfgPrmCCPBytePosn4 : 279|8@0+ (1.0,0.0) [0.0|255.0] "Unitless" ASDM,BBM,ZCUD,ZCUP
 SG_ VehCfgPrmCCPBytePosn5 : 287|8@0+ (1.0,0.0) [0.0|255.0] "Unitless" ASDM,BBM,ZCUD,ZCUP
 SG_ VehCfgPrmCCPBytePosn6 : 295|8@0+ (1.0,0.0) [0.0|255.0] "Unitless" ASDM,BBM,ZCUD,ZCUP
 SG_ VehCfgPrmCCPBytePosn7 : 303|8@0+ (1.0,0.0) [0.0|255.0] "Unitless" ASDM,BBM,ZCUD,ZCUP
 SG_ VehCfgPrmCCPBytePosn8 : 311|8@0+ (1.0,0.0) [0.0|255.0] "Unitless" ASDM,BBM,ZCUD,ZCUP
 SG_ VoiceBrstMod : 243|3@0+ (1,0) [0|7] "" ASDM
 SG_ VoiceBrstMod_UB : 240|1@0+ (1,0) [0|1] "" ASDM
 SG_ WhlCircum : 223|12@0+ (1.0,0.0) [0.0|4095.0] "Unitless" BBM,ZCUD
 SG_ WhlCircum_UB : 227|1@0+ (1,0) [0|1] "" BBM,ZCUD

BO_ 832 DhuZCUCANFD1Fr06 : 64 IHU
 SG_ BiasedPosnFromSatlt1_UB : 76|1@0+ (1,0) [0|1] "" ASDM
 SG_ BiasedPosnFromSatlt1Cntr : 79|3@0+ (1.0,0.0) [0.0|7.0] "Unitless" ASDM
 SG_ BiasedPosnFromSatlt1PosnLat : 47|30@0- (0.000000277778,0.0) [-90.000072|90.000072] "Deg" ASDM
 SG_ BiasedPosnFromSatlt1PosnLgt : 15|31@0- (0.000000277778,0.0) [-180.000144|180.000144] "Deg" ASDM
 SG_ NetDHUActvt : 359|8@0+ (1.0,0.0) [0.0|255.0] "Unitless" Vector__XXX
 SG_ NetDHUActvt_UB : 347|1@0+ (1,0) [0|1] "" Vector__XXX
 SG_ PosnFromSatlt2_UB : 85|1@0+ (1,0) [0|1] "" ASDM
 SG_ PosnFromSatlt2Cntr : 84|3@0+ (1.0,0.0) [0.0|7.0] "Unitless" ASDM
 SG_ PosnFromSatlt2PosnSpdosn : 81|17@0+ (0.001,0.0) [0.0|100.0] "m/s" ASDM
 SG_ PosnFromSatlt3_UB : 96|1@0+ (1,0) [0|1] "" ASDM
 SG_ PosnFromSatlt3Cntr : 167|3@0+ (1.0,0.0) [0.0|7.0] "Unitless" ASDM
 SG_ PosnFromSatlt3PosnAlti : 111|16@0+ (0.1,-100.0) [-100.0|6000.0] "m" ASDM
 SG_ PosnFromSatlt3PosnDir : 127|16@0+ (0.01,0.0) [0.0|359.99] "Deg" ASDM
 SG_ PosnFromSatlt3TiForMins : 149|6@0+ (1.0,0.0) [0.0|59.0] "Mins" ASDM
 SG_ PosnFromSatlt3TiForMsec : 143|10@0+ (1.0,0.0) [0.0|1023.0] "Unitless" ASDM
 SG_ PosnFromSatlt3TiForSec : 159|6@0+ (1.0,0.0) [0.0|59.0] "s" ASDM

BO_ 889 DhuZCUCANFD1Fr07 : 64 IHU
 SG_ DrvrFatiLvlFromDHU : 4|3@0+ (1,0) [0|7] "" ASDM
 SG_ DrvrFatiLvlFromDHU_UB : 5|1@0+ (1,0) [0|1] "" ASDM
 SG_ EscSptModReqdByDrvr : 12|1@0+ (1,0) [0|1] "" BBM
 SG_ EscSptModReqdByDrvr_UB : 11|1@0+ (1,0) [0|1] "" BBM
 SG_ ListOfNodAv_UB : 15|1@0+ (1,0) [0|1] "" BBM,ZCUD,ZCUP
 SG_ ListOfNodAv1 : 23|32@0+ (1.0,0.0) [0.0|4294967295.0] "Unitless" BBM,ZCUD,ZCUP
 SG_ ListOfNodAv2 : 55|32@0+ (1.0,0.0) [0.0|4294967295.0] "Unitless" BBM,ZCUD,ZCUP
 SG_ ListOfNodAv3 : 87|32@0+ (1.0,0.0) [0.0|4294967295.0] "Unitless" BBM,ZCUD,ZCUP
 SG_ ListOfNodAv4 : 119|32@0+ (1.0,0.0) [0.0|4294967295.0] "Unitless" BBM,ZCUD,ZCUP
 SG_ ListOfNodAv5 : 151|32@0+ (1.0,0.0) [0.0|4294967295.0] "Unitless" BBM,ZCUD,ZCUP
 SG_ ListOfNodAv6 : 183|32@0+ (1.0,0.0) [0.0|4294967295.0] "Unitless" BBM,ZCUD,ZCUP
 SG_ ListOfNodAv7 : 215|32@0+ (1.0,0.0) [0.0|4294967295.0] "Unitless" BBM,ZCUD,ZCUP
 SG_ ListOfNodAv8 : 247|32@0+ (1.0,0.0) [0.0|4294967295.0] "Unitless" BBM,ZCUD,ZCUP

BO_ 751 DhuZCUCANFD1Fr08 : 64 IHU
 SG_ CpmswOnOff : 15|1@0+ (1,0) [0|1] "" ASDM
 SG_ CpmswOnOff_UB : 0|1@0+ (1,0) [0|1] "" ASDM
 SG_ CtryCodInfo : 9|10@0+ (1.0,0.0) [0.0|1023.0] "Unitless" ASDM
 SG_ CtryCodInfo_UB : 14|1@0+ (1,0) [0|1] "" ASDM
 SG_ HillDwnCtrlSt : 91|1@0+ (1,0) [0|1] "" BBM
 SG_ HillDwnCtrlSt_UB : 90|1@0+ (1,0) [0|1] "" BBM
 SG_ HMIAutoShowModSet : 89|1@0+ (1,0) [0|1] "" BBM,ZCUD
 SG_ HMIAutoShowModSet_UB : 88|1@0+ (1,0) [0|1] "" BBM,ZCUD
 SG_ HznData_UB : 13|1@0+ (1,0) [0|1] "" ASDM
 SG_ HznDataCountryCode : 31|10@0+ (1.0,0.0) [0.0|1023.0] "Unitless" ASDM
 SG_ HznDataCyclicCounter : 37|2@0+ (1.0,0.0) [0.0|3.0] "Unitless" ASDM
 SG_ HznDataDrivingSide : 35|1@0+ (1,0) [0|1] "" ASDM
 SG_ HznDataHardwareVersion : 47|9@0+ (1.0,0.0) [0.0|511.0] "Unitless" ASDM
 SG_ HznDataMajorProtocolVersion : 34|2@0+ (1.0,0.0) [0.0|3.0] "Unitless" ASDM
 SG_ HznDataMapProvider : 54|3@0+ (1,0) [0|7] "" ASDM
 SG_ HznDataMapVersionYear : 63|6@0+ (1.0,0.0) [0.0|63.0] "Unitless" ASDM
 SG_ HznDataMapVersionYearQuarter : 57|2@0+ (1.0,0.0) [0.0|3.0] "Unitless" ASDM
 SG_ HznDataMessageType : 71|3@0+ (1,0) [0|7] "" ASDM
 SG_ HznDataMinorProtocolSubVersion : 68|3@0+ (1.0,0.0) [0.0|7.0] "Unitless" ASDM
 SG_ HznDataMinorProtocolVersion : 51|4@0+ (1.0,0.0) [0.0|15.0] "Unitless" ASDM
 SG_ HznDataRegionCode : 79|15@0+ (1.0,0.0) [0.0|32767.0] "Unitless" ASDM
 SG_ HznDataSpeedUnits : 32|1@0+ (1,0) [0|1] "" ASDM
 SG_ IndcnUnit_UB : 80|1@0+ (1,0) [0|1] "" Vector__XXX
 SG_ IndcnUnitClkFmt : 105|2@0+ (1,0) [0|3] "" Vector__XXX
 SG_ IndcnUnitDateFmt : 119|2@0+ (1,0) [0|3] "" Vector__XXX
 SG_ IndcnUnitDstLong : 117|2@0+ (1,0) [0|3] "" Vector__XXX
 SG_ IndcnUnitDstSho : 115|2@0+ (1,0) [0|3] "" Vector__XXX
 SG_ IndcnUnitFuCnsUnit : 111|3@0+ (1,0) [0|7] "" Vector__XXX
 SG_ IndcnUnitPUnit : 108|3@0+ (1,0) [0|7] "" Vector__XXX
 SG_ IndcnUnitSpdUnit : 113|2@0+ (1,0) [0|3] "" Vector__XXX
 SG_ IndcnUnitTUnit : 127|2@0+ (1,0) [0|3] "" Vector__XXX
 SG_ IndcnUnitVolUnit : 125|2@0+ (1,0) [0|3] "" Vector__XXX
 SG_ MiscTrfcSgnInfoFromNavMap : 95|4@0+ (1,0) [0|15] "" ASDM
 SG_ MiscTrfcSgnInfoFromNavMap_UB : 12|1@0+ (1,0) [0|1] "" ASDM

BO_ 824 DhuZCUCANFD1Fr10 : 64 IHU
 SG_ HznEdge_UB : 66|1@0+ (1,0) [0|1] "" ASDM,ZCUD
 SG_ HznEdgeComplexIntersection : 7|2@0+ (1,0) [0|3] "" ASDM,ZCUD
 SG_ HznEdgeCyclicCounter : 5|2@0+ (1.0,0.0) [0.0|3.0] "Unitless" ASDM,ZCUD
 SG_ HznEdgeFormOfWay : 3|4@0+ (1.0,0.0) [0.0|15.0] "Unitless" ASDM,ZCUD
 SG_ HznEdgeFunctionalRoadClass : 15|3@0+ (1.0,0.0) [0.0|7.0] "Unitless" ASDM,ZCUD
 SG_ HznEdgeLastStubAtOffset : 12|1@0+ (1,0) [0|1] "" ASDM,ZCUD
 SG_ HznEdgeMessageType : 11|3@0+ (1,0) [0|7] "" ASDM,ZCUD
 SG_ HznEdgeNumberOfLanesInDrivingDirection : 23|3@0+ (1.0,0.0) [0.0|7.0] "Unitless" ASDM,ZCUD
 SG_ HznEdgeNumberOfLanesInOppositeDirection : 39|2@0+ (1.0,0.0) [0.0|3.0] "Unitless" ASDM,ZCUD
 SG_ HznEdgeOffset : 20|13@0+ (1.0,0.0) [0.0|8191.0] "m" ASDM,ZCUD
 SG_ HznEdgePartOfCalculatedRoute : 37|2@0+ (1,0) [0|3] "" ASDM,ZCUD
 SG_ HznEdgePathIndex : 47|6@0+ (1.0,0.0) [0.0|63.0] "Unitless" ASDM,ZCUD
 SG_ HznEdgeRelativeProbability : 71|5@0+ (1.0,0.0) [0.0|31.0] "%" ASDM,ZCUD
 SG_ HznEdgeRetransmission : 8|1@0+ (1,0) [0|1] "" ASDM,ZCUD
 SG_ HznEdgeRightofWay : 35|2@0+ (1,0) [0|3] "" ASDM,ZCUD
 SG_ HznEdgeSubPathIndex : 63|6@0+ (1.0,0.0) [5.0|63.0] "Unitless" ASDM,ZCUD
 SG_ HznEdgeTurnAngle : 55|8@0+ (1.0,0.0) [0.0|255.0] "Unitless" ASDM,ZCUD
 SG_ HznEdgeUpdate : 33|1@0+ (1,0) [0|1] "" ASDM,ZCUD
 SG_ HznProfLong_UB : 65|1@0+ (1,0) [0|1] "" ASDM
 SG_ HznProfLongControlPoint : 64|1@0+ (1,0) [0|1] "" ASDM
 SG_ HznProfLongCyclicCounter : 121|2@0+ (1.0,0.0) [0.0|3.0] "Unitless" ASDM
 SG_ HznProfLongMessageType : 82|3@0+ (1,0) [0|7] "" ASDM
 SG_ HznProfLongOffset : 79|13@0+ (1.0,0.0) [0.0|8191.0] "m" ASDM
 SG_ HznProfLongPathIndex : 127|6@0+ (1.0,0.0) [0.0|63.0] "Unitless" ASDM
 SG_ HznProfLongProfileType : 135|5@0+ (1.0,0.0) [0.0|31.0] "Unitless" ASDM
 SG_ HznProfLongRetransmission : 130|1@0+ (1,0) [0|1] "" ASDM
 SG_ HznProfLongUpdate : 129|1@0+ (1,0) [0|1] "" ASDM
 SG_ HznProfLongValue : 95|32@0+ (1.0,0.0) [0.0|4294967295.0] "Unitless" ASDM
 SG_ HznProfSho_UB : 128|1@0+ (1,0) [0|1] "" ASDM,ZCUD
 SG_ HznProfShoAccuracy : 143|2@0+ (1,0) [0|3] "" ASDM,ZCUD
 SG_ HznProfShoControlPoint : 141|1@0+ (1,0) [0|1] "" ASDM,ZCUD
 SG_ HznProfShoCyclicCounter : 140|2@0+ (1.0,0.0) [0.0|3.0] "Unitless" ASDM,ZCUD
 SG_ HznProfShoDistance1 : 137|10@0+ (1.0,0.0) [0.0|1023.0] "m" ASDM,ZCUD
 SG_ HznProfShoMessageType : 159|3@0+ (1,0) [0|7] "" ASDM,ZCUD
 SG_ HznProfShoOffset : 156|13@0+ (1.0,0.0) [0.0|8191.0] "m" ASDM,ZCUD
 SG_ HznProfShoPathIndex : 175|6@0+ (1.0,0.0) [0.0|63.0] "Unitless" ASDM,ZCUD
 SG_ HznProfShoProfileType : 191|5@0+ (1.0,0.0) [0.0|31.0] "Unitless" ASDM,ZCUD
 SG_ HznProfShoRetransmission : 138|1@0+ (1,0) [0|1] "" ASDM,ZCUD
 SG_ HznProfShoUpdate : 186|1@0+ (1,0) [0|1] "" ASDM,ZCUD
 SG_ HznProfShoValue0 : 169|10@0+ (1.0,0.0) [0.0|1023.0] "Unitless" ASDM,ZCUD
 SG_ HznProfShoValue1 : 185|10@0+ (1.0,0.0) [0.0|1023.0] "Unitless" ASDM,ZCUD
 SG_ HznSeg_UB : 256|1@0+ (1,0) [0|1] "" ASDM
 SG_ HznSegBridge : 207|2@0+ (1,0) [0|3] "" ASDM
 SG_ HznSegBuiltupArea : 205|2@0+ (1,0) [0|3] "" ASDM
 SG_ HznSegComplexIntersection : 203|2@0+ (1,0) [0|3] "" ASDM
 SG_ HznSegCyclicCounter : 201|2@0+ (1.0,0.0) [0.0|3.0] "Unitless" ASDM
 SG_ HznSegDividedRoad : 223|2@0+ (1,0) [0|3] "" ASDM
 SG_ HznSegEffectiveSpdLimit : 215|5@0+ (1.0,0.0) [0.0|31.0] "Km/h" ASDM
 SG_ HznSegEffectiveSpeedLimitType : 210|3@0+ (1.0,0.0) [0.0|7.0] "Unitless" ASDM
 SG_ HznSegFormofWay : 221|4@0+ (1.0,0.0) [0.0|15.0] "Unitless" ASDM
 SG_ HznSegFunctionalRoadClass : 231|3@0+ (1.0,0.0) [0.0|7.0] "Unitless" ASDM
 SG_ HznSegMessageType : 228|3@0+ (1,0) [0|7] "" ASDM
 SG_ HznSegNumberoflanesindrivingdirection : 239|3@0+ (1.0,0.0) [0.0|7.0] "Unitless" ASDM
 SG_ HznSegNumberoflanesinoppositedirection : 217|2@0+ (1.0,0.0) [0.0|3.0] "Unitless" ASDM
 SG_ HznSegOffset : 247|13@0+ (1.0,0.0) [0.0|8191.0] "m" ASDM
 SG_ HznSegPartOfCalculatedRoute : 225|2@0+ (1,0) [0|3] "" ASDM
 SG_ HznSegPathIndex : 263|6@0+ (1.0,0.0) [0.0|63.0] "Unitless" ASDM
 SG_ HznSegRelativeProbability : 236|5@0+ (1.0,0.0) [0.0|31.0] "%" ASDM
 SG_ HznSegRetransmission : 250|1@0+ (1,0) [0|1] "" ASDM
 SG_ HznSegTunnel : 249|2@0+ (1,0) [0|3] "" ASDM
 SG_ HznSegUpdate : 257|1@0+ (1,0) [0|1] "" ASDM

BO_ 501 DhuZCUCANFD1Fr12 : 64 IHU
 SG_ VehCfgPrmExt_UB : 71|1@0+ (1,0) [0|1] "" ASDM,BBM,ZCUD,ZCUP
 SG_ VehCfgPrmExtBlkIDBytePosn1 : 7|8@0+ (1.0,0.0) [0.0|255.0] "Unitless" ASDM,BBM,ZCUD,ZCUP
 SG_ VehCfgPrmExtCCPBytePosn2 : 15|8@0+ (1.0,0.0) [0.0|255.0] "Unitless" ASDM,BBM,ZCUD,ZCUP
 SG_ VehCfgPrmExtCCPBytePosn3 : 23|8@0+ (1.0,0.0) [0.0|255.0] "Unitless" ASDM,BBM,ZCUD,ZCUP
 SG_ VehCfgPrmExtCCPBytePosn4 : 31|8@0+ (1.0,0.0) [0.0|255.0] "Unitless" ASDM,BBM,ZCUD,ZCUP
 SG_ VehCfgPrmExtCCPBytePosn5 : 39|8@0+ (1.0,0.0) [0.0|255.0] "Unitless" ASDM,BBM,ZCUD,ZCUP
 SG_ VehCfgPrmExtCCPBytePosn6 : 47|8@0+ (1.0,0.0) [0.0|255.0] "Unitless" ASDM,BBM,ZCUD,ZCUP
 SG_ VehCfgPrmExtCCPBytePosn7 : 55|8@0+ (1.0,0.0) [0.0|255.0] "Unitless" ASDM,BBM,ZCUD,ZCUP
 SG_ VehCfgPrmExtCCPBytePosn8 : 63|8@0+ (1.0,0.0) [0.0|255.0] "Unitless" ASDM,BBM,ZCUD,ZCUP
 SG_ Vin_UB : 70|1@0+ (1,0) [0|1] "" ASDM,BBM,ZCUD,ZCUP
 SG_ VinBlockNr : 79|8@0+ (1.0,0.0) [0.0|255.0] "Unitless" ASDM,BBM,ZCUD,ZCUP
 SG_ VinVINSignalPos1 : 87|8@0+ (1.0,0.0) [0.0|255.0] "Unitless" ASDM,BBM,ZCUD,ZCUP
 SG_ VinVINSignalPos2 : 95|8@0+ (1.0,0.0) [0.0|255.0] "Unitless" ASDM,BBM,ZCUD,ZCUP
 SG_ VinVINSignalPos3 : 103|8@0+ (1.0,0.0) [0.0|255.0] "Unitless" ASDM,BBM,ZCUD,ZCUP
 SG_ VinVINSignalPos4 : 111|8@0+ (1.0,0.0) [0.0|255.0] "Unitless" ASDM,BBM,ZCUD,ZCUP
 SG_ VinVINSignalPos5 : 119|8@0+ (1.0,0.0) [0.0|255.0] "Unitless" ASDM,BBM,ZCUD,ZCUP
 SG_ VinVINSignalPos6 : 127|8@0+ (1.0,0.0) [0.0|255.0] "Unitless" ASDM,BBM,ZCUD,ZCUP
 SG_ VinVINSignalPos7 : 135|8@0+ (1.0,0.0) [0.0|255.0] "Unitless" ASDM,BBM,ZCUD,ZCUP

BO_ 504 DhuZCUCANFD1Fr14 : 64 IHU
 SG_ ProfPenSts1 : 55|4@0+ (1,0) [0|15] "" ASDM,BBM,ZCUD
 SG_ ProfPenSts1_UB : 36|1@0+ (1,0) [0|1] "" ASDM,BBM,ZCUD
 SG_ PtDrvrSetg : 51|4@0+ (1,0) [0|15] "" ASDM,ZCUD
 SG_ PtDrvrSetg_UB : 33|1@0+ (1,0) [0|1] "" ASDM,ZCUD
 SG_ SftySigGroupFromHmiSafe1_UB : 77|1@0+ (1,0) [0|1] "" ASDM
 SG_ SftySigGroupFromHmiSafe1SftyHmiDend : 63|2@0+ (1,0) [0|3] "" ASDM
 SG_ SftySigGroupFromHmiSafe1SftyHmiEna : 61|2@0+ (1,0) [0|3] "" ASDM
 SG_ SftySigGroupFromHmiSafe1SftySigFaildDetdByHmi : 79|2@0+ (1,0) [0|3] "" ASDM
 SG_ SftySigGroupFromHmiSafe1SftySigGroupFromHmiSafeChks : 71|8@0+ (1.0,0.0) [0.0|255.0] "Unitless" ASDM
 SG_ SftySigGroupFromHmiSafe1SftySigGroupFromHmiSafeCntr : 59|4@0+ (1.0,0.0) [0.0|15.0] "Unitless" ASDM
 SG_ SnsrDrvrPfmncStsFromDHU : 12|3@0+ (1,0) [0|7] "" ASDM
 SG_ SnsrDrvrPfmncStsFromDHU_UB : 9|1@0+ (1,0) [0|1] "" ASDM
 SG_ VehDecelCtrlSetg : 35|1@0+ (1,0) [0|1] "" BBM
 SG_ VehDecelCtrlSetg_UB : 34|1@0+ (1,0) [0|1] "" BBM

BO_ 352 DhuZCUCANFD1Fr16 : 64 IHU
 SG_ AccFusnTrfcReq : 233|1@0+ (1,0) [0|1] "" ASDM
 SG_ AccFusnTrfcReq_UB : 232|1@0+ (1,0) [0|1] "" ASDM
 SG_ BkpOfDstTrvld : 223|21@0+ (1.0,0.0) [0.0|2000000.0] "km" ASDM,BBM,ZCUD,ZCUP
 SG_ BkpOfDstTrvld_UB : 234|1@0+ (1,0) [0|1] "" ASDM,BBM,ZCUD,ZCUP
 SG_ BSDaudioOnOff : 253|1@0+ (1,0) [0|1] "" ASDM
 SG_ BSDaudioOnOff_UB : 252|1@0+ (1,0) [0|1] "" ASDM
 SG_ BSDSwOnOff : 251|1@0+ (1,0) [0|1] "" ASDM
 SG_ BSDSwOnOff_UB : 250|1@0+ (1,0) [0|1] "" ASDM
 SG_ EpbApplyAutSetg : 319|1@0+ (1,0) [0|1] "" ZCUD
 SG_ EpbApplyAutSetg_UB : 318|1@0+ (1,0) [0|1] "" ZCUD
 SG_ HznSplyElectcSts : 210|2@0+ (1,0) [0|3] "" ASDM
 SG_ HznSplyElectcSts_UB : 208|1@0+ (1,0) [0|1] "" ASDM
 SG_ LaneKeepAidActvSts : 249|1@0+ (1,0) [0|1] "" ASDM
 SG_ LaneKeepAidActvSts_UB : 248|1@0+ (1,0) [0|1] "" ASDM
 SG_ NavInfoSts : 263|1@0+ (1,0) [0|1] "" ASDM
 SG_ NavInfoSts_UB : 269|1@0+ (1,0) [0|1] "" ASDM
 SG_ OffsForSpdWarnSetgReq : 262|3@0+ (1,0) [0|7] "" ASDM
 SG_ OffsForSpdWarnSetgReq_UB : 268|1@0+ (1,0) [0|1] "" ASDM
 SG_ OffsForSpdWarnSetgReqSts : 259|4@0+ (1,0) [0|15] "" ASDM
 SG_ OffsForSpdWarnSetgReqSts_UB : 267|1@0+ (1,0) [0|1] "" ASDM
 SG_ PosnFromSatlt_UB : 211|1@0+ (1,0) [0|1] "" ASDM,BBM
 SG_ PosnFromSatltCntr : 170|3@0+ (1.0,0.0) [0.0|7.0] "Unitless" ASDM,BBM
 SG_ PosnFromSatltPosnAlti : 7|16@0+ (0.1,-100.0) [-100.0|6000.0] "m" ASDM,BBM
 SG_ PosnFromSatltPosnDir : 23|16@0+ (0.01,0.0) [0.0|359.99] "Deg" ASDM,BBM
 SG_ PosnFromSatltPosnLat : 39|30@0- (0.000000277778,0.0) [-90.000072|90.000072] "Deg" ASDM,BBM
 SG_ PosnFromSatltPosnLgt : 71|31@0- (0.000000277778,0.0) [-180.000144|180.000144] "Deg" ASDM,BBM
 SG_ PosnFromSatltPosnSpd : 88|17@0+ (0.001,0.0) [0.0|100.0] "m/s" ASDM,BBM
 SG_ PosnFromSatltPosnVHozl : 119|17@0+ (0.001,0.0) [0.0|100.0] "m/s" ASDM,BBM
 SG_ PosnFromSatltPosnVVert : 134|18@0- (0.001,0.0) [-100.0|100.0] "m/s" ASDM,BBM
 SG_ PosnFromSatltTiForMins : 165|6@0+ (1.0,0.0) [0.0|59.0] "Mins" ASDM,BBM
 SG_ PosnFromSatltTiForMsec : 159|10@0+ (1.0,0.0) [0.0|1023.0] "Unitless" ASDM,BBM
 SG_ PosnFromSatltTiForSec : 191|6@0+ (1.0,0.0) [0.0|59.0] "s" ASDM,BBM
 SG_ PosnFromSatltUTCForDay : 148|5@0+ (1.0,0.0) [1.0|31.0] "Days" ASDM,BBM
 SG_ PosnFromSatltUTCForHr : 175|5@0+ (1.0,0.0) [0.0|23.0] "hours" ASDM,BBM
 SG_ PosnFromSatltUTCForMins : 199|6@0+ (1.0,0.0) [0.0|59.0] "Mins" ASDM,BBM
 SG_ PosnFromSatltUTCForMth : 215|4@0+ (1.0,0.0) [1.0|12.0] "Month" ASDM,BBM
 SG_ PosnFromSatltUTCForSec : 207|6@0+ (1.0,0.0) [0.0|59.0] "s" ASDM,BBM
 SG_ PosnFromSatltUTCForYr : 183|7@0+ (1.0,0.0) [0.0|99.0] "Year" ASDM,BBM
 SG_ RampInfo_UB : 264|1@0+ (1,0) [0|1] "" ASDM
 SG_ RampInfoDstToRamp : 279|10@0+ (1.0,0.0) [0.0|1000.0] "m" ASDM
 SG_ RampInfoEnterRamp : 285|1@0+ (1,0) [0|1] "" ASDM
 SG_ RCWSwOnOff : 284|1@0+ (1,0) [0|1] "" ASDM
 SG_ RCWSwOnOff_UB : 311|1@0+ (1,0) [0|1] "" ASDM
 SG_ RoadMiscSgnInfoForRoadSgnInfoSts : 283|1@0+ (1,0) [0|1] "" ASDM
 SG_ RoadMiscSgnInfoForRoadSgnInfoSts_UB : 310|1@0+ (1,0) [0|1] "" ASDM
 SG_ RoadSgnInfoActvSts : 282|1@0+ (1,0) [0|1] "" ASDM
 SG_ RoadSgnInfoActvSts_UB : 309|1@0+ (1,0) [0|1] "" ASDM
 SG_ SmtSteerAssidSwtReq : 281|1@0+ (1,0) [0|1] "" BBM
 SG_ SmtSteerAssidSwtReq_UB : 308|1@0+ (1,0) [0|1] "" BBM
 SG_ SpdAlrmActvForRoadSgnInfoSts : 280|2@0+ (1,0) [0|3] "" ASDM
 SG_ SpdAlrmActvForRoadSgnInfoSts_UB : 307|1@0+ (1,0) [0|1] "" ASDM
 SG_ TrlrModSwtReq : 317|1@0+ (1,0) [0|1] "" BBM,ZCUD
 SG_ TrlrModSwtReq_UB : 316|1@0+ (1,0) [0|1] "" BBM,ZCUD
 SG_ VehSpdIndcd_UB : 306|1@0+ (1,0) [0|1] "" ASDM,BBM,ZCUD
 SG_ VehSpdIndcdQly : 294|2@0+ (1,0) [0|3] "" ASDM
 SG_ VehSpdIndcdQly_UB : 305|1@0+ (1,0) [0|1] "" ASDM
 SG_ VehSpdIndcdVehSpdIndcd : 288|9@0+ (1.0,0.0) [0.0|511.0] "Unitless" ASDM,BBM,ZCUD
 SG_ VehSpdIndcdVeSpdIndcdUnit : 290|2@0+ (1,0) [0|3] "" ASDM,BBM,ZCUD
 SG_ WarnTypForLaneKeepAidSts : 292|2@0+ (1,0) [0|3] "" ASDM
 SG_ WarnTypForLaneKeepAidSts_UB : 304|1@0+ (1,0) [0|1] "" ASDM

BO_ 1289 DhuZCUDCANFD1NMFr : 8 IHU
 SG_ PNC23_IHU : 23|1@0+ (1,0) [0|0] "" Vector__XXX
 SG_ PNC25_IHU : 25|1@0+ (1,0) [0|0] "" Vector__XXX
 SG_ PNC29_IHU : 29|1@0+ (1,0) [0|0] "" Vector__XXX
 SG_ PNC36_IHU : 36|1@0+ (1,0) [0|0] "" Vector__XXX
 SG_ PNC38_IHU : 38|1@0+ (1,0) [0|0] "" Vector__XXX
 SG_ NM_PNI_IHU : 14|1@0+ (1,0) [0|0] "" Vector__XXX
 SG_ NM_AW_IHU : 12|1@0+ (1,0) [0|0] "" Vector__XXX
 SG_ NM_CS_IHU : 11|1@0+ (1,0) [0|0] "" Vector__XXX
 SG_ NM_RMR_IHU : 8|1@0+ (1,0) [0|0] "" Vector__XXX
 SG_ NM_NodeID_IHU : 7|8@0+ (1,0) [0|0] "" Vector__XXX

 SG_ WakeUpReasonsforDHU : 55|16@0+ (1,0) [0|65535] "" Vector__XXX

BO_ 337 DHUZCUDCANFD1SecOCSyncFr : 64 IHU
 SG_ TripResetSyncMsgAuthenticator : 47|88@0+ (1.0,0.0) [0.0|309485009821345070000000000.0] "Unitless" ASDM
 SG_ TripResetSyncMsgResetcounter : 31|16@0+ (1.0,0.0) [0.0|65535.0] "Unitless" ASDM
 SG_ TripResetSyncMsgTripcounter : 7|24@0+ (1.0,0.0) [0.0|16777215.0] "Unitless" ASDM

BO_ 821 PASZCUCANFD1Fr05 : 64 IHU
 SG_ MirrOpenClsReq : 17|2@0+ (1,0) [0|3] "" ZCUD
 SG_ MirrOpenClsReq_UB : 18|1@0+ (1,0) [0|1] "" ZCUD

BO_ 528 PASZCUCANFD1Fr06 : 64 IHU
 SG_ PrkgStsToEDR_UB : 24|1@0+ (1,0) [0|1] "" ZCUD
 SG_ PrkgStsToEDRAPATo : 111|3@0+ (1,0) [0|7] "" ZCUD
 SG_ PrkgStsToEDRHPATo : 108|3@0+ (1,0) [0|7] "" ZCUD
 SG_ PrkgStsToEDRLSDAandTBATo : 119|3@0+ (1,0) [0|7] "" ZCUD
 SG_ PrkgStsToEDRreserved1 : 116|3@0+ (1,0) [0|7] "" ZCUD
 SG_ PrkgStsToEDRreserved2 : 127|3@0+ (1,0) [0|7] "" ZCUD
 SG_ PrkgStsToEDRreserved3 : 124|3@0+ (1,0) [0|7] "" ZCUD
 SG_ PrkgStsToEDRRPATo : 135|3@0+ (1,0) [0|7] "" ZCUD
 SG_ VehPrkgLockTheftReq : 191|2@0+ (1,0) [0|3] "" ZCUD
 SG_ VehPrkgLockTheftReq_UB : 189|1@0+ (1,0) [0|1] "" ZCUD
 SG_ VehWinSunRoofClsReq : 188|2@0+ (1,0) [0|3] "" ZCUD,ZCUP
 SG_ VehWinSunRoofClsReq_UB : 186|1@0+ (1,0) [0|1] "" ZCUD,ZCUP

BO_ 96 PASZCUCANFD1Fr07 : 64 IHU
 SG_ GearPrkgAssiReqGroup_UB : 25|1@0+ (1,0) [0|1] "" ZCUD
 SG_ GearPrkgAssiReqGroupChks : 23|8@0+ (1.0,0.0) [0.0|255.0] "Unitless" ZCUD
 SG_ GearPrkgAssiReqGroupCntr : 31|4@0+ (1.0,0.0) [0.0|15.0] "Unitless" ZCUD
 SG_ GearPrkgAssiReqGroupGearPrkgAssiReq1 : 27|2@0+ (1,0) [0|3] "" ZCUD
 SG_ PrkgAsscSysEcuTyp : 103|2@0+ (1,0) [0|3] "" ASDM
 SG_ PrkgAsscSysEcuTyp_UB : 101|1@0+ (1,0) [0|1] "" ASDM
 SG_ PrkgAssiElectcStabyProgCtrlModReqGroup_UB : 47|1@0+ (1,0) [0|1] "" ASDM,BBM
 SG_ PrkgAssiElectcStabyProgCtrlModReqGroupChks : 55|8@0+ (1.0,0.0) [0.0|255.0] "Unitless" ASDM,BBM
 SG_ PrkgAssiElectcStabyProgCtrlModReqGroupCntr : 43|4@0+ (1.0,0.0) [0.0|15.0] "Unitless" ASDM,BBM
 SG_ PrkgAssiElectcStabyProgCtrlModReqGroupPASElectcStabyProgCtrlModReq : 46|3@0+ (1,0) [0|7] "" ASDM,BBM
 SG_ PrkgAssiSysRemPrkgSts : 227|4@0+ (1,0) [0|15] "" ASDM,ZCUD
 SG_ PrkgAssiSysRemPrkgSts_UB : 96|1@0+ (1,0) [0|1] "" ASDM,ZCUD
 SG_ PrkgEmgyBrkEmgyBrkReq : 32|1@0+ (1,0) [0|1] "" ASDM
 SG_ PrkgEmgyBrkEmgyBrkReq_UB : 33|1@0+ (1,0) [0|1] "" ASDM
 SG_ PrkgEmgyBrkEpbApplyReq : 162|1@0+ (1,0) [0|1] "" BBM
 SG_ PrkgEmgyBrkEpbApplyReq_UB : 163|1@0+ (1,0) [0|1] "" BBM
 SG_ PrkgEmgyBrkStandStillReq : 98|1@0+ (1,0) [0|1] "" BBM
 SG_ PrkgEmgyBrkStandStillReq_UB : 97|1@0+ (1,0) [0|1] "" BBM
 SG_ PrkgSpdCtrlSafeGroup_UB : 152|1@0+ (1,0) [0|1] "" BBM
 SG_ PrkgSpdCtrlSafeGroupChks : 111|8@0+ (1.0,0.0) [0.0|255.0] "Unitless" BBM
 SG_ PrkgSpdCtrlSafeGroupCntr : 119|4@0+ (1.0,0.0) [0.0|15.0] "Unitless" BBM
 SG_ PrkgSpdCtrlSafeGroupDrvrAsscSysBrkFctMod : 115|2@0+ (1,0) [0|3] "" BBM
 SG_ PrkgSpdCtrlSafeGroupPrkgAssiALowrLim : 127|8@0+ (0.01,-1.28) [-1.28|1.2700000000000002] "m/s^2" BBM
 SG_ PrkgSpdCtrlSafeGroupPrkgAssiALowrSlop : 151|7@0+ (0.1,-12.7) [-12.7|0.000000000000001776] "m/s^3" BBM
 SG_ PrkgSpdCtrlSafeGroupPrkgAssiAReq1 : 135|8@0+ (0.01,-1.28) [-1.28|1.2700000000000002] "m/s^2" BBM
 SG_ PrkgSpdCtrlSafeGroupPrkgAssiAUpprLim : 143|8@0+ (0.01,-1.28) [-1.28|1.2700000000000002] "m/s^2" BBM
 SG_ PrkgSpdCtrlSafeGroupPrkgAssiAUpprSlop : 159|7@0+ (0.1,0.0) [0.0|12.700000000000001] "m/s^3" BBM
 SG_ PrkgUsgDrvModTranReq : 80|1@0+ (1,0) [0|1] "" ZCUD
 SG_ PrkgUsgDrvModTranReq_UB : 81|1@0+ (1,0) [0|1] "" ZCUD
 SG_ VehBeamLoModReq : 95|2@0+ (1,0) [0|3] "" ZCUD
 SG_ VehBeamLoModReq_UB : 93|1@0+ (1,0) [0|1] "" ZCUD
 SG_ VehPrkgToHorn : 246|1@0+ (1,0) [0|1] "" ZCUD
 SG_ VehPrkgToHorn_UB : 245|1@0+ (1,0) [0|1] "" ZCUD

BO_ 587 PASZCUCANFD1Fr15 : 64 IHU
 SG_ PrkgImgDispReq : 7|5@0+ (1.0,0.0) [0.0|31.0] "Unitless" ASDM
 SG_ PrkgImgDispReq_UB : 2|1@0+ (1,0) [0|1] "" ASDM

BO_ 784 PASZCUCANFD1Fr18 : 64 IHU
 SG_ PrkgFctVMMModReq : 4|1@0+ (1,0) [0|1] "" ZCUD
 SG_ PrkgFctVMMModReq_UB : 0|1@0+ (1,0) [0|1] "" ZCUD

BO_ 274 PASZCUCANFD1Fr20 : 64 IHU
 SG_ DrvrAsscSysIndcrReq : 231|2@0+ (1,0) [0|3] "" ZCUD
 SG_ DrvrAsscSysIndcrReq_UB : 229|1@0+ (1,0) [0|1] "" ZCUD
 SG_ DrvrAsscSysIndcrReq1 : 259|3@0+ (1,0) [0|7] "" ZCUD
 SG_ DrvrAsscSysIndcrReq1_UB : 256|1@0+ (1,0) [0|1] "" ZCUD
 SG_ DrvrAsscSysSts : 223|4@0+ (1,0) [0|15] "" ASDM
 SG_ DrvrAsscSysSts_UB : 217|1@0+ (1,0) [0|1] "" ASDM
 SG_ PrkgAccrOvrdnCtrlReqgrp_UB : 330|1@0+ (1,0) [0|1] "" BBM
 SG_ PrkgAccrOvrdnCtrlReqgrpChks : 327|8@0+ (1.0,0.0) [0.0|255.0] "Unitless" BBM
 SG_ PrkgAccrOvrdnCtrlReqgrpCntr : 335|4@0+ (1.0,0.0) [0.0|15.0] "Unitless" BBM
 SG_ PrkgAccrOvrdnCtrlReqgrpPrkgAccrOvrdnCtrlReq : 331|1@0+ (1,0) [0|1] "" BBM
 SG_ PrkgBrkElectcCtrlReq_UB : 345|1@0+ (1,0) [0|1] "" BBM
 SG_ PrkgBrkElectcCtrlReqChks : 343|8@0+ (1.0,0.0) [0.0|255.0] "Unitless" BBM
 SG_ PrkgBrkElectcCtrlReqCntr : 351|4@0+ (1.0,0.0) [0.0|15.0] "Unitless" BBM
 SG_ PrkgBrkElectcCtrlReqReq : 347|2@0+ (1,0) [0|3] "" BBM
 SG_ PrkgEmgyBrkSysSts : 239|4@0+ (1,0) [0|15] "" ASDM
 SG_ PrkgEmgyBrkSysSts_UB : 235|1@0+ (1,0) [0|1] "" ASDM
 SG_ PrkgLockReq : 234|2@0+ (1,0) [0|3] "" ZCUD
 SG_ PrkgLockReq_UB : 232|1@0+ (1,0) [0|1] "" ZCUD
 SG_ PrkgStandstillReq_UB : 344|1@0+ (1,0) [0|1] "" BBM
 SG_ PrkgStandstillReqChks : 359|8@0+ (1.0,0.0) [0.0|255.0] "Unitless" BBM
 SG_ PrkgStandstillReqCntr : 367|4@0+ (1.0,0.0) [0.0|15.0] "Unitless" BBM
 SG_ PrkgStandstillReqReqSts1 : 363|1@0+ (1,0) [0|1] "" BBM
 SG_ VehBeamLoModReq1 : 319|3@0+ (1,0) [0|7] "" ZCUD
 SG_ VehBeamLoModReq1_UB : 316|1@0+ (1,0) [0|1] "" ZCUD
 SG_ VoiceKeyPrkgSts : 329|1@0+ (1,0) [0|1] "" ZCUD
 SG_ VoiceKeyPrkgSts_UB : 328|1@0+ (1,0) [0|1] "" ZCUD

BO_ 1073 ZCUCANFD1RoutingVFCVectFr : 64 ASDM
 SG_ VFCVectorSODL_UB : 71|1@0+ (1,0) [0|1] "" IHU
 SG_ VFCVectorSODLBlockID : 1|2@0+ (1.0,0.0) [0.0|3.0] "Unitless" IHU
 SG_ VFCVectorSODLVFCid0 : 2|1@0+ (1,0) [0|1] "" IHU
 SG_ VFCVectorSODLVFCid1 : 3|1@0+ (1,0) [0|1] "" IHU
 SG_ VFCVectorSODLVFCid10 : 12|1@0+ (1,0) [0|1] "" IHU
 SG_ VFCVectorSODLVFCid11 : 13|1@0+ (1,0) [0|1] "" IHU
 SG_ VFCVectorSODLVFCid12 : 14|1@0+ (1,0) [0|1] "" IHU
 SG_ VFCVectorSODLVFCid13 : 15|1@0+ (1,0) [0|1] "" IHU
 SG_ VFCVectorSODLVFCid14 : 16|1@0+ (1,0) [0|1] "" IHU
 SG_ VFCVectorSODLVFCid15 : 17|1@0+ (1,0) [0|1] "" IHU
 SG_ VFCVectorSODLVFCid16 : 18|1@0+ (1,0) [0|1] "" IHU
 SG_ VFCVectorSODLVFCid17 : 19|1@0+ (1,0) [0|1] "" IHU
 SG_ VFCVectorSODLVFCid18 : 20|1@0+ (1,0) [0|1] "" IHU
 SG_ VFCVectorSODLVFCid19 : 21|1@0+ (1,0) [0|1] "" IHU
 SG_ VFCVectorSODLVFCid2 : 4|1@0+ (1,0) [0|1] "" IHU
 SG_ VFCVectorSODLVFCid20 : 22|1@0+ (1,0) [0|1] "" IHU
 SG_ VFCVectorSODLVFCid21 : 23|1@0+ (1,0) [0|1] "" IHU
 SG_ VFCVectorSODLVFCid22 : 24|1@0+ (1,0) [0|1] "" IHU
 SG_ VFCVectorSODLVFCid23 : 25|1@0+ (1,0) [0|1] "" IHU
 SG_ VFCVectorSODLVFCid24 : 26|1@0+ (1,0) [0|1] "" IHU
 SG_ VFCVectorSODLVFCid25 : 27|1@0+ (1,0) [0|1] "" IHU
 SG_ VFCVectorSODLVFCid26 : 28|1@0+ (1,0) [0|1] "" IHU
 SG_ VFCVectorSODLVFCid27 : 29|1@0+ (1,0) [0|1] "" IHU
 SG_ VFCVectorSODLVFCid28 : 30|1@0+ (1,0) [0|1] "" IHU
 SG_ VFCVectorSODLVFCid29 : 31|1@0+ (1,0) [0|1] "" IHU
 SG_ VFCVectorSODLVFCid3 : 5|1@0+ (1,0) [0|1] "" IHU
 SG_ VFCVectorSODLVFCid30 : 32|1@0+ (1,0) [0|1] "" IHU
 SG_ VFCVectorSODLVFCid31 : 33|1@0+ (1,0) [0|1] "" IHU
 SG_ VFCVectorSODLVFCid32 : 34|1@0+ (1,0) [0|1] "" IHU
 SG_ VFCVectorSODLVFCid33 : 35|1@0+ (1,0) [0|1] "" IHU
 SG_ VFCVectorSODLVFCid34 : 36|1@0+ (1,0) [0|1] "" IHU
 SG_ VFCVectorSODLVFCid35 : 37|1@0+ (1,0) [0|1] "" IHU
 SG_ VFCVectorSODLVFCid36 : 38|1@0+ (1,0) [0|1] "" IHU
 SG_ VFCVectorSODLVFCid37 : 39|1@0+ (1,0) [0|1] "" IHU
 SG_ VFCVectorSODLVFCid38 : 40|1@0+ (1,0) [0|1] "" IHU
 SG_ VFCVectorSODLVFCid39 : 41|1@0+ (1,0) [0|1] "" IHU
 SG_ VFCVectorSODLVFCid4 : 6|1@0+ (1,0) [0|1] "" IHU
 SG_ VFCVectorSODLVFCid40 : 42|1@0+ (1,0) [0|1] "" IHU
 SG_ VFCVectorSODLVFCid41 : 43|1@0+ (1,0) [0|1] "" IHU
 SG_ VFCVectorSODLVFCid42 : 44|1@0+ (1,0) [0|1] "" IHU
 SG_ VFCVectorSODLVFCid43 : 45|1@0+ (1,0) [0|1] "" IHU
 SG_ VFCVectorSODLVFCid44 : 46|1@0+ (1,0) [0|1] "" IHU
 SG_ VFCVectorSODLVFCid45 : 47|1@0+ (1,0) [0|1] "" IHU
 SG_ VFCVectorSODLVFCid46 : 48|1@0+ (1,0) [0|1] "" IHU
 SG_ VFCVectorSODLVFCid47 : 49|1@0+ (1,0) [0|1] "" IHU
 SG_ VFCVectorSODLVFCid48 : 50|1@0+ (1,0) [0|1] "" IHU
 SG_ VFCVectorSODLVFCid49 : 51|1@0+ (1,0) [0|1] "" IHU
 SG_ VFCVectorSODLVFCid5 : 7|1@0+ (1,0) [0|1] "" IHU
 SG_ VFCVectorSODLVFCid50 : 52|1@0+ (1,0) [0|1] "" IHU
 SG_ VFCVectorSODLVFCid51 : 53|1@0+ (1,0) [0|1] "" IHU
 SG_ VFCVectorSODLVFCid52 : 54|1@0+ (1,0) [0|1] "" IHU
 SG_ VFCVectorSODLVFCid53 : 55|1@0+ (1,0) [0|1] "" IHU
 SG_ VFCVectorSODLVFCid54 : 56|1@0+ (1,0) [0|1] "" IHU
 SG_ VFCVectorSODLVFCid55 : 57|1@0+ (1,0) [0|1] "" IHU
 SG_ VFCVectorSODLVFCid56 : 58|1@0+ (1,0) [0|1] "" IHU
 SG_ VFCVectorSODLVFCid57 : 59|1@0+ (1,0) [0|1] "" IHU
 SG_ VFCVectorSODLVFCid58 : 60|1@0+ (1,0) [0|1] "" IHU
 SG_ VFCVectorSODLVFCid59 : 61|1@0+ (1,0) [0|1] "" IHU
 SG_ VFCVectorSODLVFCid6 : 8|1@0+ (1,0) [0|1] "" IHU
 SG_ VFCVectorSODLVFCid60 : 62|1@0+ (1,0) [0|1] "" IHU
 SG_ VFCVectorSODLVFCid61 : 63|1@0+ (1,0) [0|1] "" IHU
 SG_ VFCVectorSODLVFCid7 : 9|1@0+ (1,0) [0|1] "" IHU
 SG_ VFCVectorSODLVFCid8 : 10|1@0+ (1,0) [0|1] "" IHU
 SG_ VFCVectorSODLVFCid9 : 11|1@0+ (1,0) [0|1] "" IHU

BO_ 1633 ZcudBmsToDhuZCUCANFD1DiagResFr : 64 ZCUD

BO_ 1552 ZcudEcmToDhuZCUCANFD1DiagResFr : 64 ZCUD

BO_ 1635 ZcudGcmToDhuZCUCANFD1DiagResFr : 64 ZCUD

BO_ 1648 ZcudPscmToDhuZCUCANFD1DiagResFr : 64 ZCUD

BO_ 1555 ZcudRbcmToDhuZCUCANFD1DiagResFr : 64 ZCUD

BO_ 1650 ZcudSasToDhuZCUCANFD1DiagResFr : 64 ZCUD

BO_ 1557 ZcudSclToDhuZCUCANFD1DiagResFr : 64 ZCUD

BO_ 1556 ZcudSumToDhuZCUCANFD1DiagResFr : 64 ZCUD

CM_ SG_ 1384 VFCVectorBCMBlockID "BlockID";
CM_ SG_ 1384 VFCVectorBCMVFCid0 "SettingsComfort";
CM_ SG_ 1384 VFCVectorBCMVFCid1 "ParkingDrivingClimatization";
CM_ SG_ 1384 VFCVectorBCMVFCid10 "ExteriorLighting";
CM_ SG_ 1384 VFCVectorBCMVFCid11 "VFCid11";
CM_ SG_ 1384 VFCVectorBCMVFCid12 "Alarm";
CM_ SG_ 1384 VFCVectorBCMVFCid13 "VFCid13";
CM_ SG_ 1384 VFCVectorBCMVFCid14 "InteriorLighting";
CM_ SG_ 1384 VFCVectorBCMVFCid15 "VFCid15";
CM_ SG_ 1384 VFCVectorBCMVFCid16 "Locking";
CM_ SG_ 1384 VFCVectorBCMVFCid17 "RemoteKeyFunctionality";
CM_ SG_ 1384 VFCVectorBCMVFCid18 "PropulsionStart";
CM_ SG_ 1384 VFCVectorBCMVFCid19 "VFCid19";
CM_ SG_ 1384 VFCVectorBCMVFCid2 "PostClimatisation";
CM_ SG_ 1384 VFCVectorBCMVFCid20 "VFCid20";
CM_ SG_ 1384 VFCVectorBCMVFCid21 "PowerClosures";
CM_ SG_ 1384 VFCVectorBCMVFCid22 "VehicleDriving";
CM_ SG_ 1384 VFCVectorBCMVFCid23 "VFCid23";
CM_ SG_ 1384 VFCVectorBCMVFCid24 "SettingsProfile";
CM_ SG_ 1384 VFCVectorBCMVFCid25 "SeatComfortFunctions";
CM_ SG_ 1384 VFCVectorBCMVFCid26 "Brake";
CM_ SG_ 1384 VFCVectorBCMVFCid27 "InfotainmentPoll";
CM_ SG_ 1384 VFCVectorBCMVFCid28 "HVEnergyStorage";
CM_ SG_ 1384 VFCVectorBCMVFCid29 "VFCid29";
CM_ SG_ 1384 VFCVectorBCMVFCid3 "PowertrainParkingClimatization";
CM_ SG_ 1384 VFCVectorBCMVFCid30 "TelematicsConnectivity";
CM_ SG_ 1384 VFCVectorBCMVFCid31 "VFCid31";
CM_ SG_ 1384 VFCVectorBCMVFCid32 "VFCid32";
CM_ SG_ 1384 VFCVectorBCMVFCid33 "Diagnostics";
CM_ SG_ 1384 VFCVectorBCMVFCid34 "VehicleModeManagement";
CM_ SG_ 1384 VFCVectorBCMVFCid35 "TrailerCaravanFunctions";
CM_ SG_ 1384 VFCVectorBCMVFCid36 "Immobilizer";
CM_ SG_ 1384 VFCVectorBCMVFCid37 "Windows";
CM_ SG_ 1384 VFCVectorBCMVFCid38 "Visibility";
CM_ SG_ 1384 VFCVectorBCMVFCid39 "VFCid39";
CM_ SG_ 1384 VFCVectorBCMVFCid4 "VFCid4";
CM_ SG_ 1384 VFCVectorBCMVFCid40 "VFCid40";
CM_ SG_ 1384 VFCVectorBCMVFCid41 "InfotainmentPush";
CM_ SG_ 1384 VFCVectorBCMVFCid42 "ChargingHV";
CM_ SG_ 1384 VFCVectorBCMVFCid43 "BodyPreClimatisation";
CM_ SG_ 1384 VFCVectorBCMVFCid44 "Crash";
CM_ SG_ 1384 VFCVectorBCMVFCid45 "GlobalShortDuration";
CM_ SG_ 1384 VFCVectorBCMVFCid46 "ExteriorLightsHazard";
CM_ SG_ 1384 VFCVectorBCMVFCid47 "VFCid47";
CM_ SG_ 1384 VFCVectorBCMVFCid48 "DoorOpenWarning";
CM_ SG_ 1384 VFCVectorBCMVFCid49 "ChargingLVInit";
CM_ SG_ 1384 VFCVectorBCMVFCid5 "VFCid5";
CM_ SG_ 1384 VFCVectorBCMVFCid50 "VFCid50";
CM_ SG_ 1384 VFCVectorBCMVFCid51 "VFCid51";
CM_ SG_ 1384 VFCVectorBCMVFCid52 "HVBatteryThermalEventWarning";
CM_ SG_ 1384 VFCVectorBCMVFCid53 "VisualAssist";
CM_ SG_ 1384 VFCVectorBCMVFCid54 "PassiveSafety";
CM_ SG_ 1384 VFCVectorBCMVFCid55 "LifeDetection";
CM_ SG_ 1384 VFCVectorBCMVFCid56 "BackboneFlexray";
CM_ SG_ 1384 VFCVectorBCMVFCid57 "Functionmarket";
CM_ SG_ 1384 VFCVectorBCMVFCid58 "VFCid58";
CM_ SG_ 1384 VFCVectorBCMVFCid59 "VFCid59";
CM_ SG_ 1384 VFCVectorBCMVFCid6 "SettingsVehicle";
CM_ SG_ 1384 VFCVectorBCMVFCid60 "VFCid60";
CM_ SG_ 1384 VFCVectorBCMVFCid61 "VFCid61";
CM_ SG_ 1384 VFCVectorBCMVFCid7 "VFCid7";
CM_ SG_ 1384 VFCVectorBCMVFCid8 "VFCid8";
CM_ SG_ 1384 VFCVectorBCMVFCid9 "IPWakeup";
CM_ SG_ 1320 WakeUpReasonsforBCM "WakeUpReasons";
CM_ SG_ 87 DrvrACCrsSetSpdReqDrvrACCrsCtrlSetInSpdReq "this group port is used  to  inform the safty subsystem to the ADAS fouction target speed set information. this port is the speed with offset";
CM_ SG_ 87 DrvrACCrsSetSpdReqDrvrCrsSetSpdReq "this group port is used  to  inform the safty subsystem to the ADAS fouction target speed set information. this port is used to inform safty the user want to add 1or add 5or minus1 or minus5";
CM_ SG_ 87 DrvrACCrsSetSpdReqSetSpdForCrsCtrlFctActive "this group port is used  to  inform the safty subsystem to the ADAS fouction target speed set information. this port is the speed without offset";
CM_ SG_ 488 AsyEmgyManoeuvreAidActvSts "EMA function on/off ";
CM_ SG_ 488 AsyNoaUpgradeswitch "active NOA request";
CM_ SG_ 488 BSDSwOnOffandWarnType "BSDSwOnOffandWarnType";
CM_ SG_ 488 CamFltsStsFromDHU "camera fault status signal";
CM_ SG_ 488 CllsnAidSnvtySeldSts "sensitive select.";
CM_ SG_ 488 CllsnMtgtnActvSeldSts "AEB function on/off";
CM_ SG_ 488 CmftBrkStopSwtSts "HMI request comfortable brake stop fuction on/off ";
CM_ SG_ 488 CrsCtrlTiGapAdjReq "ACC Time Gap Adjust Requirement ";
CM_ SG_ 488 CurrentRoadLvl "Current road level";
CM_ SG_ 488 DrvOffReq "FCDA function setting";
CM_ SG_ 488 DrvrCrsCtrlFctActvReq "this port is used to indicate ACC requirest founction";
CM_ SG_ 488 DrvrDecStsFromDHU " the signal of the detection state of driver";
CM_ SG_ 488 DrvrPfmncAlrmReqFromDHU "this singal indicate the level of fatigue alarm.";
CM_ SG_ 488 DrvrPfmncSwitchStsFromDHU "DPS function switch";
CM_ SG_ 488 EmgyLaneKeepAidActvSts "the request to enable/disable ELKA function by SW switch in IHU.";
CM_ SG_ 488 EyeGazeDirVecFromDHUX "Eye gaze direction  X vector ";
CM_ SG_ 488 EyeGazeDirVecFromDHUY "Eye gaze direction Y vector ";
CM_ SG_ 488 EyeGazeDirVecFromDHUZ "Eye gaze direction Z vector ";
CM_ SG_ 488 EyeGazeFromDHUEyeGazeZone "eye  gaze zones";
CM_ SG_ 488 EyeGazeFromDHUEyeGazeZoneTime "eye gaze zone time";
CM_ SG_ 488 EyeGzaeDirOriFromDHUX "Eye gaze original X position";
CM_ SG_ 488 EyeGzaeDirOriFromDHUY "Eye gaze original Y position";
CM_ SG_ 488 EyeGzaeDirOriFromDHUZ "Eye gaze original Z position";
CM_ SG_ 488 EyeOnRoadFromDHUChks "Counter";
CM_ SG_ 488 EyeOnRoadFromDHUCntr "CRC";
CM_ SG_ 488 EyeOnRoadFromDHUEyesOnRoad "This signal indicate eyegaze in on road";
CM_ SG_ 488 EyeOpenFromDHUEyeOpenDegLe " the open angle of left eye";
CM_ SG_ 488 EyeOpenFromDHUEyeOpenDegRi "the open angle of right eye";
CM_ SG_ 488 EyeOpenFromDHUEyeOpenLe "Eye open of left";
CM_ SG_ 488 EyeOpenFromDHUEyeOpenRi "Eye open of right";
CM_ SG_ 488 EyeOpenFromDHUEyeVisibleLe "the visible state of left eye";
CM_ SG_ 488 EyeOpenFromDHUEyeVisibleRi "the visible state of right eye";
CM_ SG_ 488 EyeOpenFromDHUFaceVisible "face visible";
CM_ SG_ 488 HdPosnValidSigFromDHUX "X value of driver is head";
CM_ SG_ 488 HdPosnValidSigFromDHUY "Y value of driver is head";
CM_ SG_ 488 HdPosnValidSigFromDHUZ "Z value of driver is head";
CM_ SG_ 488 HdRotateAgFromDHUHdPitchAg "pitch angle of driver is head";
CM_ SG_ 488 HdRotateAgFromDHUHdRollAg "roll angle of driver is head";
CM_ SG_ 488 HdRotateAgFromDHUHdYawAg "yaw angle of driver is head";
CM_ SG_ 488 HeadGazeDirOriFromDHUX "Head gaze original X position";
CM_ SG_ 488 HeadGazeDirOriFromDHUY "Head gaze original Y position";
CM_ SG_ 488 HeadGazeDirOriFromDHUZ "Head gaze original Z position";
CM_ SG_ 488 HeadGazeDirVecFromDHUX "Head gaze direction X vector ";
CM_ SG_ 488 HeadGazeDirVecFromDHUY "Head gaze direction Y vector ";
CM_ SG_ 488 HeadGazeDirVecFromDHUZ "Head gaze direction Z vector ";
CM_ SG_ 488 HmiDrvrSodReqPilot "Driver voice activated G-Pilot request";
CM_ SG_ 488 HznPosnCurrentLane "0x0 Unknown 0x1 Emergency lane 0x2 Single-lane road 0x3 Left-most lane 0x4 Right-most lane 0x5 One of middle lanes on road with three or more lanes 0x6 Reserved0x7 N/A";
CM_ SG_ 488 HznPosnCyclicCounter "Cyclic counter of this message type: Reconstructor can use this value to detect missing messages";
CM_ SG_ 488 HznPosnMessageType "Type of a CAN message in the scope of the ADASISv2 protocol. ";
CM_ SG_ 488 HznPosnOffset "Offset of current position from the current path start point modulo 8191.";
CM_ SG_ 488 HznPosnPathIndex " [0x0: Unknown][0x1: Position not in Digitized Area][0x2: Position not on-road][0x3:  Vehicle Positioning sub-system not calibrated][0x4:the current vehicle position segment][0x5: the existence of a crossroad branch]...";
CM_ SG_ 488 HznPosnPositionAge "Time difference between the moment the message is sent and the moment the vehicle position is calculated by the positioning sub-system.";
CM_ SG_ 488 HznPosnPositionConfidence "Position confidence: this field contains Av2HP implementation specific values. Use 0 for highest confidence, 6 for lowest confidence. Value 7 means N/A";
CM_ SG_ 488 HznPosnPositionIndex "If Av2HP supports positioning alternatives, contains index of this Position Candidate. Candidate 0 is always most probable position candidate, candidate 1 second etc. If Av2HP does not support positioning alternatives, it will be always 0.";
CM_ SG_ 488 HznPosnPositionProbability "Position Probability is calculated by Positioning module of ADASIS v2 Horizon Provider. Different Av2HPs will use different algorithms to calculate this value. 0x0:unknown 0x1F: N/A";
CM_ SG_ 488 HznPosnRelativeHeading "[0x0:In path direction][0x1:1.417 degrees right][0x2..0x7E:Right from path direction][0x7E:178.583 degrees right][0x7F:Opposite direction][0x80:178.583 degrees left (181.417 degrees right)][0x80..0xFC:Left from path direction][0xFD:1.417 degrees left (358.583 degrees right)][0xFE:Unknown][0xFF:N/A]";
CM_ SG_ 488 HznPosnSpeed "Speed of the vehicle projected to the path ";
CM_ SG_ 488 NavForDrvrPfmncStsFromDHU "The switch signal of rest stop guidance";
CM_ SG_ 488 RemCtrlVehSts "remote control vehicle state";
CM_ SG_ 775 FogSetReReq "turn on or turn off rear fog light";
CM_ SG_ 775 GNSSSolution1Cntr "Counter";
CM_ SG_ 775 GNSSSolution1NoOfSatItForSysNo1 "Number of GPS satellites used for positioning";
CM_ SG_ 775 GNSSSolution1NoOfSatItForSysNo2 "Number of GLONASS satellites used for positioning";
CM_ SG_ 775 GNSSSolution1NoOfSatItForSysNo3 "Number of Galileo satellites used for positioning";
CM_ SG_ 775 GNSSSolution1NoOfSatItForSysNo4 "Number of SBAS satellites used for positioning";
CM_ SG_ 775 GNSSSolution1NoOfSatItForSysNo5 "Number of QZSS L1 satellites used for positioning";
CM_ SG_ 775 GNSSSolution1NoOfSatItForSysNo6 "Number of QZSS L1-SAIF satellites used for positioning";
CM_ SG_ 775 GNSSSolution1NoOfSatItForSysNo7 "Number of BeiDou satellites used for positioning";
CM_ SG_ 775 GNSSSolution1SatItSysNo1InUse "GPS used for positioning";
CM_ SG_ 775 GNSSSolution1SatItSysNo2InUse "GLONASS used for positioning";
CM_ SG_ 775 GNSSSolution1SatItSysNo3InUse "Galileo used for positioning";
CM_ SG_ 775 GNSSSolution1SatItSysNo4InUse "SBAS used for positioning";
CM_ SG_ 775 GNSSSolution1SatItSysNo5InUse "QZSS L1 used for positioning";
CM_ SG_ 775 GNSSSolution1SatItSysNo6InUse "QZSS L1-SAIF used for positioning";
CM_ SG_ 775 GNSSSolution1SatItSysNo7InUse "BeiDou used for positioning";
CM_ SG_ 775 GNSSSolution1SatltPosnStsPrm1 "Navigation solution status";
CM_ SG_ 775 GNSSSolution1SatltPosnStsPrm2 "DGPS usage in solution";
CM_ SG_ 775 GNSSSolution2Cntr "Counter ";
CM_ SG_ 775 GNSSSolution2PreHozlDil "Horizontal Dilution Of Precision";
CM_ SG_ 775 GNSSSolution2PrePosnDil "Position Dilution Of Precision";
CM_ SG_ 775 GNSSSolution2PreVertDil "Vertical Dilution Of Precision";
CM_ SG_ 775 GNSSSolutionCntr "Counter ";
CM_ SG_ 775 GNSSSolutionNoOfSatltForSysNo1 "Number of GPS satellites used for positioning";
CM_ SG_ 775 GNSSSolutionNoOfSatltForSysNo2 "Number of GLONASS satellites used for positioning";
CM_ SG_ 775 GNSSSolutionNoOfSatltForSysNo3 "Number of Galileo satellites used for positioning";
CM_ SG_ 775 GNSSSolutionNoOfSatltForSysNo4 "Number of SBAS satellites used for positioning";
CM_ SG_ 775 GNSSSolutionNoOfSatltForSysNo5 "Number of QZSS L1 satellites used for positioning";
CM_ SG_ 775 GNSSSolutionNoOfSatltForSysNo6 "Number of QZSS L1-SAIF satellites used for positioning";
CM_ SG_ 775 GNSSSolutionNoOfSatltForSysNo7 "Number of BeiDou satellites used for positioning";
CM_ SG_ 775 GNSSSolutionPreHozlDil "Horizontal Dilution Of Precision";
CM_ SG_ 775 GNSSSolutionPrePosnDil "Position Dilution Of Precision";
CM_ SG_ 775 GNSSSolutionPreVertDil "Vertical Dilution Of Precision";
CM_ SG_ 775 GNSSSolutionSatltPosnStsPrm1 "Navigation solution status";
CM_ SG_ 775 GNSSSolutionSatltPosnStsPrm2 "DGPS usage in solution";
CM_ SG_ 775 GNSSSolutionSatltSysNo1InUse "GPS used for positioning";
CM_ SG_ 775 GNSSSolutionSatltSysNo2InUse "GLONASS used for positioning";
CM_ SG_ 775 GNSSSolutionSatltSysNo3InUse "Galileo used for positioning";
CM_ SG_ 775 GNSSSolutionSatltSysNo4InUse "SBAS used for positioning";
CM_ SG_ 775 GNSSSolutionSatltSysNo5InUse "QZSS L1 used for positioning";
CM_ SG_ 775 GNSSSolutionSatltSysNo6InUse "QZSS L1-SAIF used for positioning";
CM_ SG_ 775 GNSSSolutionSatltSysNo7InUse "BeiDou used for positioning";
CM_ SG_ 775 GNSSSolutionTiForMins "minutes";
CM_ SG_ 775 GNSSSolutionTiForMsec "milliseconds";
CM_ SG_ 775 GNSSSolutionTiForSec "seconds";
CM_ SG_ 775 PosnFromSatlt1Cntr "Counter ";
CM_ SG_ 775 PosnFromSatlt1PosnLat "Latitude";
CM_ SG_ 775 PosnFromSatlt1PosnLgt "Longitude";
CM_ SG_ 775 ScenarioMod "Scenario mode setting, for example rest mdoe, refresh etc.";
CM_ SG_ 775 SpplTrfcSgnInfoFromNavMap "Current supplementary traffic sign information from navigation map";
CM_ SG_ 775 VstdModeSts "Vehicle Sentry and Theft Deterrence States";
CM_ SG_ 86 AsyAutDrvCtrlTypDIMReq "this port is used to inform Safty subsystem which type driver have choosen.
the request to choose ACC or G-pilot function by SW switch in DIM.
0x0:RESERVE:Never be send out 
0x1:ACC
0x2:G-Polit";
CM_ SG_ 86 BiasedPosnFromSatltCntr "Counter ";
CM_ SG_ 86 BiasedPosnFromSatltPosnLat "Latitude";
CM_ SG_ 86 BiasedPosnFromSatltPosnLgt "Longitude";
CM_ SG_ 86 BiasedPosnFromSatltTiForMins "minutes";
CM_ SG_ 86 BiasedPosnFromSatltTiForMsec "milliseconds ";
CM_ SG_ 86 BiasedPosnFromSatltTiForSec "seconds";
CM_ SG_ 86 DrvModReq "drive mode";
CM_ SG_ 86 EpbSoftSwtCtrlSt "Epb Soft Switch Control ";
CM_ SG_ 86 FuLvlIndcdFuLvlValFromFuTbl " Fuel level value converted from fuel table";
CM_ SG_ 86 FuLvlIndcdGenQF "Quality Flag";
CM_ SG_ 86 GpsStatus "GPS signal confidence, successful=1 or failure=0. ";
CM_ SG_ 86 IntvAndWarnModForLaneKeepAidSts "this port is used to LKA founction";
CM_ SG_ 86 SetLimReq "manual set/auto set road sign recogition.";
CM_ SG_ 86 SpdLimdSts "the shared key speed limited status";
CM_ SG_ 86 VBFsetg "VBF setting";
CM_ SG_ 373 AutoHldSoftSwtCtrlSt "Auto Hold soft switch control state";
CM_ SG_ 373 CrossInfoDirOfNavRut "Direction of the navigation route at the next cross";
CM_ SG_ 373 CrossInfoDstToCros "Distance to next cross";
CM_ SG_ 373 CrossInfoTrfcLi "Is there traffic light at the next cross";
CM_ SG_ 373 CtraSwOnOff "RCTA function on/off request.";
CM_ SG_ 373 DIMStsDistbn "DIM error status distribution.";
CM_ SG_ 373 DOWSwOnOff "DOW function on/off request.";
CM_ SG_ 373 DrvrACCFctDeactvnReqChks "this port is used to tell the status of HMI subsystem to ADAS subsystem";
CM_ SG_ 373 DrvrACCFctDeactvnReqCntr "this port is used to tell the status of HMI subsystem to ADAS subsystem";
CM_ SG_ 373 DrvrACCFctDeactvnReqSts "this port is used to tell the status of HMI subsystem to ADAS subsystem";
CM_ SG_ 373 DrvrLaneChgAutActvSts "the request to enable/disable HWA function by SW switch in IHU.";
CM_ SG_ 373 HmiDrvrSodReqChg "Driver voice activated lane change request";
CM_ SG_ 373 HmiSodLanChgSwitch "Voice activated lane change switch settings";
CM_ SG_ 373 HmiStrangerModMenuSetActvInActv "Whether stranger mode is activated or inactive for limit speed states";
CM_ SG_ 373 HmiStrangerModMenuSetPasswordSt "Represents password status,(PasswordSt No:No password set),(PasswordSt Yes: Password set)";
CM_ SG_ 373 HmiStrangerModMenuSetPrivateLockSt "Whether to associate a private lock:(SelectedSt No-Not associated),(SelectedSt Yes-Associated)";
CM_ SG_ 373 HmiStrangerModMenuSetSpdLim "Stranger mode limit speed set Km/h";
CM_ SG_ 373 MobDevRPAReq1Chks "Checksum calculation for E2E";
CM_ SG_ 373 MobDevRPAReq1Cntr "E2E counter";
CM_ SG_ 373 MobDevRPAReq1MobDevSts "mobile device status";
CM_ SG_ 373 MobDevRPAReq1RPAOutModeSubT "RPA Out Mode Direction";
CM_ SG_ 373 MobDevRPAReq1RPAReq "RPA control";
CM_ SG_ 373 MobDevRPAReq1RSPACtrl "RSPA control";
CM_ SG_ 373 PlannedPahDe "whether vehicle is driving in the planned path";
CM_ SG_ 373 SetSpdForCrsCtrlFct "set speed for cc
";
CM_ SG_ 373 SpdCamFromNavMap "Speed limited information from navigation map engine";
CM_ SG_ 373 SpdLimOfRoad "Speed limit of current road";
CM_ SG_ 373 VehCfgPrmBlkIDBytePosn1 "signal block counter.";
CM_ SG_ 373 VehCfgPrmCCPBytePosn2 " (BlockID-1)*7 + 1. ";
CM_ SG_ 373 VehCfgPrmCCPBytePosn3 " (BlockID-1)*7 + 2. ";
CM_ SG_ 373 VehCfgPrmCCPBytePosn4 " (BlockID-1)*7 + 3. ";
CM_ SG_ 373 VehCfgPrmCCPBytePosn5 " (BlockID-1)*7 + 4. ";
CM_ SG_ 373 VehCfgPrmCCPBytePosn6 " (BlockID-1)*7 + 5. ";
CM_ SG_ 373 VehCfgPrmCCPBytePosn7 " (BlockID-1)*7 + 6. ";
CM_ SG_ 373 VehCfgPrmCCPBytePosn8 " (BlockID-1)*7 + 7. ";
CM_ SG_ 373 VoiceBrstMod "Voice broadcast mode setting";
CM_ SG_ 373 WhlCircum "Wheel circumference in millimeters. Invalid value indicated by 4095.";
CM_ SG_ 832 BiasedPosnFromSatlt1Cntr "counter";
CM_ SG_ 832 BiasedPosnFromSatlt1PosnLat "Latitude";
CM_ SG_ 832 BiasedPosnFromSatlt1PosnLgt "Longitude";
CM_ SG_ 832 NetDHUActvt "It describes which state managers that are member of each resource group.";
CM_ SG_ 832 PosnFromSatlt2Cntr "counter";
CM_ SG_ 832 PosnFromSatlt2PosnSpdosn "Speed";
CM_ SG_ 832 PosnFromSatlt3Cntr "counter";
CM_ SG_ 832 PosnFromSatlt3PosnAlti "Altitide from mean sea level";
CM_ SG_ 832 PosnFromSatlt3PosnDir "Heading from true north";
CM_ SG_ 832 PosnFromSatlt3TiForMins "minute";
CM_ SG_ 832 PosnFromSatlt3TiForMsec "milliseconds";
CM_ SG_ 832 PosnFromSatlt3TiForSec "second";
CM_ SG_ 889 DrvrFatiLvlFromDHU "driver fitigue signal";
CM_ SG_ 889 EscSptModReqdByDrvr "Distributes the Drivers request to enable ESC Sport Mode.";
CM_ SG_ 889 ListOfNodAv1 "Bit coded with 0 indicating not mounted and 1 indicating mounted.  ECUs from 1 to 32.";
CM_ SG_ 889 ListOfNodAv2 "ECUs from 33 to 64.";
CM_ SG_ 889 ListOfNodAv3 "ECUs from 65 to 96.";
CM_ SG_ 889 ListOfNodAv4 "ECUs from 97 to 128.";
CM_ SG_ 889 ListOfNodAv5 "ECUs from 129 to 160.";
CM_ SG_ 889 ListOfNodAv6 "ECUs from 161 to 192.";
CM_ SG_ 889 ListOfNodAv7 "ECUs from 193 to 224.";
CM_ SG_ 889 ListOfNodAv8 "ECUs from 225 to 256.";
CM_ SG_ 751 CpmswOnOff "the request to select REM by switch in HMI";
CM_ SG_ 751 CtryCodInfo "Country code information";
CM_ SG_ 751 HillDwnCtrlSt "Hill Descent Control State";
CM_ SG_ 751 HMIAutoShowModSet "HMI Auto Show Mode Set";
CM_ SG_ 751 HznDataCountryCode "ISO 3166-1 Release 2007-03 country code of current position; 0 stands for unknown. Valid values are those specified by ISO 3166-1 numeric";
CM_ SG_ 751 HznDataCyclicCounter "Cyclic counter of this message type: Reconstructor can use this value to detect missing messages";
CM_ SG_ 751 HznDataDrivingSide "0 stands for Driving Side Left. 1 stands for Driving Side Right. Default is 1.";
CM_ SG_ 751 HznDataHardwareVersion "This field is ADAS Horizon Provider specific and expresses the hardware and/or software version of the provider depending of the company specific numbering scheme. 0 stands for unknown.";
CM_ SG_ 751 HznDataMajorProtocolVersion "Contains Major protocol version";
CM_ SG_ 751 HznDataMapProvider "Map Provider of current area (map tile, region, country ). ";
CM_ SG_ 751 HznDataMapVersionYear "Content of this field is Year of release of map of current area using the formula ((Year minus 2000) modulo 63).";
CM_ SG_ 751 HznDataMapVersionYearQuarter "Content of this field is Year quarter of release of map of current area using the formula (Quarter minus 1). ";
CM_ SG_ 751 HznDataMessageType "Type of a CAN message in the scope of the ADASISv2 protocol";
CM_ SG_ 751 HznDataMinorProtocolSubVersion "Contains Minor protocol sub-version";
CM_ SG_ 751 HznDataMinorProtocolVersion "Contains Minor protocol version";
CM_ SG_ 751 HznDataRegionCode "Based on ISO 3166-2, for a given Country Code, specifies region of a country where vehicle is currently positioned. 0 stands for unknown, value 32767 means N/A";
CM_ SG_ 751 HznDataSpeedUnits "1 stands for miles per hour (mph). 0 stands for kilometers/hour (km/h). Default is 0.";
CM_ SG_ 751 IndcnUnitClkFmt "Clock Format";
CM_ SG_ 751 IndcnUnitDateFmt "DateFormat";
CM_ SG_ 751 IndcnUnitDstLong "Long Distance Units";
CM_ SG_ 751 IndcnUnitDstSho "Short Distance Units";
CM_ SG_ 751 IndcnUnitFuCnsUnit "Fuel Consumption Units";
CM_ SG_ 751 IndcnUnitPUnit "Pressure Unit";
CM_ SG_ 751 IndcnUnitSpdUnit "Speed Units";
CM_ SG_ 751 IndcnUnitTUnit "Temperature Unit";
CM_ SG_ 751 IndcnUnitVolUnit "Volume Units";
CM_ SG_ 751 MiscTrfcSgnInfoFromNavMap "Current miscellaneous traffic sign information from navigation Map.";
CM_ SG_ 824 HznEdgeComplexIntersection "0: New path is not part of complex intersection. 1: New path is part of a complex intersection. 2: Unknown 3: N/A";
CM_ SG_ 824 HznEdgeCyclicCounter "Cyclic counter of this message type: Reconstructor can use this value to detect missing messages";
CM_ SG_ 824 HznEdgeFormOfWay "Form of Way of new path. For more details please see requiement HznEdgeMessage.";
CM_ SG_ 824 HznEdgeFunctionalRoadClass "value 0 is unknown, value 7 indicates N/A. 1: High way 2: Express way 3: National road/ Province road 4: Main road / County Road 5: Secondary Road / Township Road 6: Normal Road / County Rural Interior Road / Avenue";
CM_ SG_ 824 HznEdgeLastStubAtOffset "Value true indicates that this STUB message is last one that refers to given parent path and offset; value false says that more STUB messages for this offset on parent path will be sent";
CM_ SG_ 824 HznEdgeMessageType "Type of a CAN message in the scope of the ADASISv2 protocol.";
CM_ SG_ 824 HznEdgeNumberOfLanesInDrivingDirection "Number of lanes in driving direction of new path: Also implies driving direction.0 denotes one-direction road driven in wrong direction, 1-5 are verbatim values, and 6 indicate 6 or more lanes. Value 7 means N/A.";
CM_ SG_ 824 HznEdgeNumberOfLanesInOppositeDirection "Number of lanes in opposite direction on new path 0 denotes one-direction road, 1 for one lane only; 2 indicates two or more lanes. Value 3 means N/A.";
CM_ SG_ 824 HznEdgeOffset "Offset of the position of the crossing from the start path position modulo 8191. Offset 8191 is invalid.";
CM_ SG_ 824 HznEdgePartOfCalculatedRoute "0: New path from this point on is not part of Calculated Route 1: New path from this point on is part of Calculated Route 2: Unknown 3: N/A";
CM_ SG_ 824 HznEdgePathIndex "Index of parent path; zero indicates this STUB starts first path in the Horizon.";
CM_ SG_ 824 HznEdgeRelativeProbability "[Value 0 (= 0%) indicates that turn is not allowed.][Value 30 (= 100%) indicates that this is the only possible turn.][Value 31 means unknown or N/A.]";
CM_ SG_ 824 HznEdgeRetransmission "If true, this message has been sent at least once before. 0x0:False 0x1:True";
CM_ SG_ 824 HznEdgeRightofWay "0: Driving towards this stub has priority over all conflicting vehicle movements  1: Driving towards this stub might require yielding to conflicting vehicle movements 2: Unknown 3: N/A";
CM_ SG_ 824 HznEdgeSubPathIndex "This is Index of new path.";
CM_ SG_ 824 HznEdgeTurnAngle "Trun angle.For more details please see requiement HznEdgeMessage.";
CM_ SG_ 824 HznEdgeUpdate "Value true indicates that this message contains updated information of already transmitted STUB. 0x0:False 0x1:True";
CM_ SG_ 824 HznProfLongControlPoint "If true, values in this message specifies additional control points required for the interpolation of this profile; If false, actual profile values are specified. 0x0:false 0x1:true";
CM_ SG_ 824 HznProfLongCyclicCounter "Cyclic counter of this message type and profile type: Reconstructor can use this value to detect missing messages.";
CM_ SG_ 824 HznProfLongMessageType "Type of a CAN message in the scope of the ADASISv2 protocol.";
CM_ SG_ 824 HznProfLongOffset "Offset of position of the first profile spot from start position modulo 8191. Offset 8191 is invalid. 0X0-0X1FFE: 0-8190m 0X1FFF: Invalid";
CM_ SG_ 824 HznProfLongPathIndex "Index of the path where this profile(s) is located";
CM_ SG_ 824 HznProfLongProfileType "Standard PROFILE LONG Types  0:N/A 8:Traffic Sign 10:Extended Lane 19:Traffic event 20:Weather Info";
CM_ SG_ 824 HznProfLongRetransmission "If true, this message was sent already at least once before. 0x0:false 0x1:true";
CM_ SG_ 824 HznProfLongUpdate "Value true indicates that this message contains updated information of already transmitted PROFILE LONG. 0x0:false 0x1:true";
CM_ SG_ 824 HznProfLongValue "Profile value at Offset.";
CM_ SG_ 824 HznProfShoAccuracy "Accuracy of profile value is implementation specific.  0X0:highest accuracy 0X1 : medium accuracy 0X2 : lowest accuracy. 3 indicates that accuracy is unknown.";
CM_ SG_ 824 HznProfShoControlPoint "If true, values in this message specifies additional control points required for the interpolation of this profile.  0x0:false 0x1:true";
CM_ SG_ 824 HznProfShoCyclicCounter "Cyclic counter of this message type and profile type: Reconstructor can use this value to detect missing messages";
CM_ SG_ 824 HznProfShoDistance1 "Distance from first profile spot to the second one. 0X0: no other profile values are defined in this message 0X1-0X3FE: 1-1022m 0X3FF: Invalid";
CM_ SG_ 824 HznProfShoMessageType "Type of a CAN message in the scope of the ADASISv2 protocol. ";
CM_ SG_ 824 HznProfShoOffset "Offset of position of the first profile spot from start position modulo 8191. Offset 8191 is invalid 0X0-0X1FFE: 0-8190m 0X1FFF: Invalid";
CM_ SG_ 824 HznProfShoPathIndex "Index of the path where this profile(s) is located";
CM_ SG_ 824 HznProfShoProfileType "Standard PROFILE SHORT Types 0X0: N/A 0X1: Curvature 0X3: Slope (step) 0X6: Road condition 0X7: Variable Speed Sign Position 0X8: Heading Change 0x12:Travel speed 0x13:Traffic flow (Traffic flow Value interpretation varies depending on profile type) ";
CM_ SG_ 824 HznProfShoRetransmission "If true, this message was sent already at least once before.  0x0:false 0x1:true";
CM_ SG_ 824 HznProfShoUpdate "Value true indicates that this message contains updated information of already transmitted PROFILE SHORT 0x0: false 0x1:true";
CM_ SG_ 824 HznProfShoValue0 "Profile value at Offset; a special value (usually 1023) signals an invalid, unknown or N/A value. Traffic flow:profile type=19 (0x13) 02bit:Traffic Flow Status; 39bit:Traffic Flow Reliable Traffic flow s Value interpretation varies depending on profile type. ";
CM_ SG_ 824 HznProfShoValue1 "Profile value at Offset+Distance1; a special value (usually 1023) signals an invalid, unknown or N/A value.";
CM_ SG_ 824 HznSegBridge "0: Segment is not part of a bridge.  1: Segment is part of a bridge.  2: Unknown  3: N/A";
CM_ SG_ 824 HznSegBuiltupArea "0: Segment is not part of a built-up area.  1: Segment is part of a built-up area.  2: Unknown  3: N/A";
CM_ SG_ 824 HznSegComplexIntersection "0: Segment is not part of complex intersection.  1: Segment is part of a complex intersection.  2: Unknown 3: N/A";
CM_ SG_ 824 HznSegCyclicCounter "Cyclic counter of this message type: Reconstructor can use this value to detect missing messages";
CM_ SG_ 824 HznSegDividedRoad "0: Segment is not part of a divided road/dual carriageway.  1: Segment is part of a divided road/dual carriageway.  2: Unknown 3: N/A";
CM_ SG_ 824 HznSegEffectiveSpdLimit "Effective speed limit. For more details please see requiement HznSegMessage.";
CM_ SG_ 824 HznSegEffectiveSpeedLimitType "Describes what kind of Speed Limit is in effect.  0x1:Explicit  on traffic sign 0x5:Explicit AutoNavi:Speed camera";
CM_ SG_ 824 HznSegFormofWay "Form of way. For more details please see requiement HznSegMessage.";
CM_ SG_ 824 HznSegFunctionalRoadClass "Regular values are 1-6; [value 0 is unknown, value 7 indicates N/A. ][1: High way][2: Express way][3: National road / Province road][4: Main road / County Road][5: Secondary Road / Township Road][6: Normal Road / County Rural Interior Road / Avenue]";
CM_ SG_ 824 HznSegMessageType "Type of a CAN message in the scope of the ADASISv2 protocol. ";
CM_ SG_ 824 HznSegNumberoflanesindrivingdirection "Number of lanes in driving direction: also implies driving direction. 0 denotes one-direction road driven in wrong direction, 1-5 are verbatim values, and 6 indicate 6 or more lanes. Value 7 means N/A.";
CM_ SG_ 824 HznSegNumberoflanesinoppositedirection "Number of lanes in opposite direction: 0 denotes one-direction road,  1 for one lane only;  2 indicates 2 or more lanes.  Value 3 means N/A.";
CM_ SG_ 824 HznSegOffset "Offset of this segment from start position of the path modulo 8191; Value 8191 is invalid. ";
CM_ SG_ 824 HznSegPartOfCalculatedRoute "0: Segment is not part of Calculated Route  1: Segment is part of Calculated Route 2: Unknown 3: N/A";
CM_ SG_ 824 HznSegPathIndex "Value is Index of path of which this segment is part. ";
CM_ SG_ 824 HznSegRelativeProbability "Relative probability of this segment in relation to the previous segment on the same path; Value 0 indicates that driving along this segment of the path is not allowed.Value 31 means unknown or N/A.For more details please see requiement HznSegMessage.";
CM_ SG_ 824 HznSegRetransmission "If true, this message was sent already at least once before. 0x0:False 0x1:True";
CM_ SG_ 824 HznSegTunnel "0: Segment is not part of a tunnel  1: Segment is part of a tunnel  2: Unknown  3: N/A.";
CM_ SG_ 824 HznSegUpdate "Value true indicates that this message contains updated information of already transmitted SEGMENT.  0x0:False 0x1:True";
CM_ SG_ 501 VehCfgPrmExtBlkIDBytePosn1 "CarConfigExtended BlockID";
CM_ SG_ 501 VehCfgPrmExtCCPBytePosn2 "CarConfigExtended BytePos2";
CM_ SG_ 501 VehCfgPrmExtCCPBytePosn3 "CarConfigExtended BytePos3";
CM_ SG_ 501 VehCfgPrmExtCCPBytePosn4 "CarConfigExtended BytePos4";
CM_ SG_ 501 VehCfgPrmExtCCPBytePosn5 "CarConfigExtended BytePos5";
CM_ SG_ 501 VehCfgPrmExtCCPBytePosn6 "CarConfigExtended BytePos6";
CM_ SG_ 501 VehCfgPrmExtCCPBytePosn7 "CarConfigExtended BytePos7";
CM_ SG_ 501 VehCfgPrmExtCCPBytePosn8 "CarConfigExtended BytePos8";
CM_ SG_ 501 VinBlockNr "VIN number block counter. ";
CM_ SG_ 501 VinVINSignalPos1 "VIN byte 1. Used for character 1, 8 and 15.";
CM_ SG_ 501 VinVINSignalPos2 "VIN byte 2. Used for character 2, 9 and 16.";
CM_ SG_ 501 VinVINSignalPos3 "VIN byte 3. Used for character 3, 10 and 17.";
CM_ SG_ 501 VinVINSignalPos4 "VIN byte 4. Used for character 4 and 11.";
CM_ SG_ 501 VinVINSignalPos5 "VIN byte 5. Used for character 5 and 12.";
CM_ SG_ 501 VinVINSignalPos6 "VIN byte 6. Used for character 6 and 13.";
CM_ SG_ 501 VinVINSignalPos7 "VIN byte 7. Used for character 7 and 14.";
CM_ SG_ 504 ProfPenSts1 "Signal communicates which profile that is active in the car
(Personal settings).";
CM_ SG_ 504 PtDrvrSetg "PtDrvrSetg";
CM_ SG_ 504 SftySigGroupFromHmiSafe1SftyHmiDend "this port is used to tell the status of HMI subsystem to ADAS subsystem";
CM_ SG_ 504 SftySigGroupFromHmiSafe1SftyHmiEna "this port is used to tell the status of HMI subsystem to ADAS subsystem";
CM_ SG_ 504 SftySigGroupFromHmiSafe1SftySigFaildDetdByHmi "this port is used to tell the status of HMI subsystem to ADAS subsystem";
CM_ SG_ 504 SftySigGroupFromHmiSafe1SftySigGroupFromHmiSafeChks "this port is used to tell the status of HMI subsystem to ADAS subsystem";
CM_ SG_ 504 SftySigGroupFromHmiSafe1SftySigGroupFromHmiSafeCntr "this port is used to tell the status of HMI subsystem to ADAS subsystem";
CM_ SG_ 504 SnsrDrvrPfmncStsFromDHU " DMM sensor status signal";
CM_ SG_ 504 VehDecelCtrlSetg "VehDecelCtrlSetg";
CM_ SG_ 352 AccFusnTrfcReq "integrate ACC and TSR function or not.";
CM_ SG_ 352 BkpOfDstTrvld "total traveled distance.";
CM_ SG_ 352 BSDaudioOnOff "the request to choose LCA audio function by SW switch in IHU.";
CM_ SG_ 352 BSDSwOnOff "LCA function on/off switch.";
CM_ SG_ 352 EpbApplyAutSetg "Determine the setting for Automatic activation of Electronic Parking Brake";
CM_ SG_ 352 HznSplyElectcSts "HznSplyElectcSts";
CM_ SG_ 352 LaneKeepAidActvSts "the request to enable/disable LKA function by SW switch in IHU.";
CM_ SG_ 352 NavInfoSts "Navigation information status";
CM_ SG_ 352 OffsForSpdWarnSetgReq "this port is used to control TSI";
CM_ SG_ 352 OffsForSpdWarnSetgReqSts "OffsForSpdWarnSetgReqSts";
CM_ SG_ 352 PosnFromSatltCntr "Counter ";
CM_ SG_ 352 PosnFromSatltPosnAlti "Altitide from mean sea level";
CM_ SG_ 352 PosnFromSatltPosnDir "Heading from true north";
CM_ SG_ 352 PosnFromSatltPosnLat "Latitude";
CM_ SG_ 352 PosnFromSatltPosnLgt "Longitude";
CM_ SG_ 352 PosnFromSatltPosnSpd "Speed";
CM_ SG_ 352 PosnFromSatltPosnVHozl "Horizontal velocity";
CM_ SG_ 352 PosnFromSatltPosnVVert "Vertical velocity";
CM_ SG_ 352 PosnFromSatltTiForMins "in vehicle global time minutes";
CM_ SG_ 352 PosnFromSatltTiForMsec "milliseconds";
CM_ SG_ 352 PosnFromSatltTiForSec "in vehicle global time seconds";
CM_ SG_ 352 PosnFromSatltUTCForDay "UTC day";
CM_ SG_ 352 PosnFromSatltUTCForHr "UTC hour";
CM_ SG_ 352 PosnFromSatltUTCForMins "UTC minute";
CM_ SG_ 352 PosnFromSatltUTCForMth "UTC month";
CM_ SG_ 352 PosnFromSatltUTCForSec "UTC second";
CM_ SG_ 352 PosnFromSatltUTCForYr "UTC year";
CM_ SG_ 352 RampInfoDstToRamp "Distance to front ramp";
CM_ SG_ 352 RampInfoEnterRamp "Whether enter the ramp";
CM_ SG_ 352 RCWSwOnOff "the request to enable/disable RCW function by SW switch in IHU.";
CM_ SG_ 352 RoadMiscSgnInfoForRoadSgnInfoSts "the request to enable/disable TSR misc warning by SW switch in IHU.";
CM_ SG_ 352 RoadSgnInfoActvSts "the request to enable/disable TSR function by SW switch in IHU";
CM_ SG_ 352 SmtSteerAssidSwtReq "Smart steering assisted soft switch.";
CM_ SG_ 352 SpdAlrmActvForRoadSgnInfoSts "the request to enable/disable TSR speed warning function( notification ) by SW switch in IHU.";
CM_ SG_ 352 TrlrModSwtReq "trailer mode soft switch";
CM_ SG_ 352 VehSpdIndcdQly "Indicated vehicle speed QF info.";
CM_ SG_ 352 VehSpdIndcdVehSpdIndcd "Vehicle speed";
CM_ SG_ 352 VehSpdIndcdVeSpdIndcdUnit "Unit for vehicle speed";
CM_ SG_ 352 WarnTypForLaneKeepAidSts "the request to choose LKA warning type by SW switch in IHU:";
CM_ SG_ 1289 WakeUpReasonsforDHU "WakeUpReasons";
CM_ SG_ 337 TripResetSyncMsgAuthenticator "Compute the MAC for the freshness value";
CM_ SG_ 337 TripResetSyncMsgResetcounter "The master FV is kept in line with the slave FV tirp counter";
CM_ SG_ 337 TripResetSyncMsgTripcounter "The master FV is kept in line with the slave FV Reset counter";
CM_ SG_ 821 MirrOpenClsReq "Send request to DCU to fold/unfold outside mirror.";
CM_ SG_ 528 PrkgStsToEDRAPATo "APATo";
CM_ SG_ 528 PrkgStsToEDRHPATo "HPATo";
CM_ SG_ 528 PrkgStsToEDRLSDAandTBATo "LSDA&&TBATo";
CM_ SG_ 528 PrkgStsToEDRreserved1 "reserved1";
CM_ SG_ 528 PrkgStsToEDRreserved2 "reserved2";
CM_ SG_ 528 PrkgStsToEDRreserved3 "reserved3";
CM_ SG_ 528 PrkgStsToEDRRPATo "RPATo";
CM_ SG_ 528 VehPrkgLockTheftReq "Request lock/arm(unlock/disarm) the vehicle.";
CM_ SG_ 528 VehWinSunRoofClsReq "Request close the vehicle windows and sunroof.";
CM_ SG_ 96 GearPrkgAssiReqGroupChks "checksum";
CM_ SG_ 96 GearPrkgAssiReqGroupCntr "counter";
CM_ SG_ 96 GearPrkgAssiReqGroupGearPrkgAssiReq1 "The target gear request";
CM_ SG_ 96 PrkgAsscSysEcuTyp "PAS ECU TYPE";
CM_ SG_ 96 PrkgAssiElectcStabyProgCtrlModReqGroupChks "CRC,to check the signal,For E2E Protection";
CM_ SG_ 96 PrkgAssiElectcStabyProgCtrlModReqGroupCntr "counter,For E2E Protection";
CM_ SG_ 96 PrkgAssiElectcStabyProgCtrlModReqGroupPASElectcStabyProgCtrlModReq "Parking control mode request";
CM_ SG_ 96 PrkgAssiSysRemPrkgSts "RPA work status";
CM_ SG_ 96 PrkgEmgyBrkEmgyBrkReq "This is the PEB function emergency brake request to VDDM";
CM_ SG_ 96 PrkgEmgyBrkEpbApplyReq "EPB apply request by PEB";
CM_ SG_ 96 PrkgEmgyBrkStandStillReq "Keep the vehicle standstill";
CM_ SG_ 96 PrkgSpdCtrlSafeGroupChks "checksum";
CM_ SG_ 96 PrkgSpdCtrlSafeGroupCntr "counter";
CM_ SG_ 96 PrkgSpdCtrlSafeGroupDrvrAsscSysBrkFctMod "emergency and comfortable brake";
CM_ SG_ 96 PrkgSpdCtrlSafeGroupPrkgAssiALowrLim "The lower limit of the target acceleration/deceleration";
CM_ SG_ 96 PrkgSpdCtrlSafeGroupPrkgAssiALowrSlop "Target acceleration/deceleration lower slope limit";
CM_ SG_ 96 PrkgSpdCtrlSafeGroupPrkgAssiAReq1 "Target acceleration/deceleration request";
CM_ SG_ 96 PrkgSpdCtrlSafeGroupPrkgAssiAUpprLim "The upper limit of the target acceleration/deceleration";
CM_ SG_ 96 PrkgSpdCtrlSafeGroupPrkgAssiAUpprSlop "Target acceleration/deceleration upper slope limit";
CM_ SG_ 96 PrkgUsgDrvModTranReq "Request VMM change usage mode.";
CM_ SG_ 96 VehBeamLoModReq "Request open/close low beam mode.";
CM_ SG_ 96 VehPrkgToHorn "Request to active horn warning.";
CM_ SG_ 587 PrkgImgDispReq "Vehicle parking system request CSD display/not display the parking video stream";
CM_ SG_ 784 PrkgFctVMMModReq "PAS request VMM to remain in drive mode";
CM_ SG_ 274 DrvrAsscSysIndcrReq "direction indicator Request";
CM_ SG_ 274 DrvrAsscSysIndcrReq1 "direction indicator Request";
CM_ SG_ 274 DrvrAsscSysSts "APA status";
CM_ SG_ 274 PrkgAccrOvrdnCtrlReqgrpChks "Parking inhibit the accelerator pedal response signal check status";
CM_ SG_ 274 PrkgAccrOvrdnCtrlReqgrpCntr "Parking inhibit the accelerator pedal response signal counter";
CM_ SG_ 274 PrkgAccrOvrdnCtrlReqgrpPrkgAccrOvrdnCtrlReq "Parking inhibit the accelerator pedal response signal require";
CM_ SG_ 274 PrkgBrkElectcCtrlReqChks "CRC,to check the signal,For E2E Protection";
CM_ SG_ 274 PrkgBrkElectcCtrlReqCntr "counter,For E2E Protection";
CM_ SG_ 274 PrkgBrkElectcCtrlReqReq "EPB control request status";
CM_ SG_ 274 PrkgEmgyBrkSysSts "This is the PEB function operation status";
CM_ SG_ 274 PrkgLockReq "lock/unlock request for RPA function";
CM_ SG_ 274 PrkgStandstillReqChks "CRC,to check the signal,For E2E Protection";
CM_ SG_ 274 PrkgStandstillReqCntr "counter,For E2E Protection";
CM_ SG_ 274 PrkgStandstillReqReqSts1 "stop the vehcile or maintain standstill request by brake pressure control";
CM_ SG_ 274 VehBeamLoModReq1 "Request open/close low beam mode.";
CM_ SG_ 274 VoiceKeyPrkgSts "Voice key parking status feedback";
CM_ SG_ 1073 VFCVectorSODLBlockID "BlockID";
CM_ SG_ 1073 VFCVectorSODLVFCid0 "SettingsComfort";
CM_ SG_ 1073 VFCVectorSODLVFCid1 "ParkingDrivingClimatization";
CM_ SG_ 1073 VFCVectorSODLVFCid10 "ExteriorLighting";
CM_ SG_ 1073 VFCVectorSODLVFCid11 "VFC11";
CM_ SG_ 1073 VFCVectorSODLVFCid12 "Alarm";
CM_ SG_ 1073 VFCVectorSODLVFCid13 "VFC13";
CM_ SG_ 1073 VFCVectorSODLVFCid14 "InteriorLighting";
CM_ SG_ 1073 VFCVectorSODLVFCid15 "VFC15";
CM_ SG_ 1073 VFCVectorSODLVFCid16 "Locking";
CM_ SG_ 1073 VFCVectorSODLVFCid17 "RemoteKeyFunctionality";
CM_ SG_ 1073 VFCVectorSODLVFCid18 "PropulsionStart";
CM_ SG_ 1073 VFCVectorSODLVFCid19 "VFC19";
CM_ SG_ 1073 VFCVectorSODLVFCid2 "PostClimatisation";
CM_ SG_ 1073 VFCVectorSODLVFCid20 "VFC20";
CM_ SG_ 1073 VFCVectorSODLVFCid21 "PowerClosures";
CM_ SG_ 1073 VFCVectorSODLVFCid22 "VehicleDriving";
CM_ SG_ 1073 VFCVectorSODLVFCid23 "VFC23";
CM_ SG_ 1073 VFCVectorSODLVFCid24 "SettingsProfile";
CM_ SG_ 1073 VFCVectorSODLVFCid25 "SeatComfortFunctions";
CM_ SG_ 1073 VFCVectorSODLVFCid26 "Brake";
CM_ SG_ 1073 VFCVectorSODLVFCid27 "InfotainmentPoll";
CM_ SG_ 1073 VFCVectorSODLVFCid28 "HVEnergyStorage";
CM_ SG_ 1073 VFCVectorSODLVFCid29 "VFC29";
CM_ SG_ 1073 VFCVectorSODLVFCid3 "PowertrainParkingClimatization";
CM_ SG_ 1073 VFCVectorSODLVFCid30 "TelematicsConnectivity";
CM_ SG_ 1073 VFCVectorSODLVFCid31 "VFC31";
CM_ SG_ 1073 VFCVectorSODLVFCid32 "VFC32";
CM_ SG_ 1073 VFCVectorSODLVFCid33 "Diagnostics";
CM_ SG_ 1073 VFCVectorSODLVFCid34 "VehicleModeManagement";
CM_ SG_ 1073 VFCVectorSODLVFCid35 "TrailerCaravanFunctions";
CM_ SG_ 1073 VFCVectorSODLVFCid36 "Immobilizer";
CM_ SG_ 1073 VFCVectorSODLVFCid37 "Windows";
CM_ SG_ 1073 VFCVectorSODLVFCid38 "Visibility";
CM_ SG_ 1073 VFCVectorSODLVFCid39 "VFC39";
CM_ SG_ 1073 VFCVectorSODLVFCid4 "VFC4";
CM_ SG_ 1073 VFCVectorSODLVFCid40 "VFC40";
CM_ SG_ 1073 VFCVectorSODLVFCid41 "InfotainmentPush";
CM_ SG_ 1073 VFCVectorSODLVFCid42 "ChargingHV";
CM_ SG_ 1073 VFCVectorSODLVFCid43 "BodyPreClimatisation";
CM_ SG_ 1073 VFCVectorSODLVFCid44 "Crash";
CM_ SG_ 1073 VFCVectorSODLVFCid45 "GlobalShortDuration";
CM_ SG_ 1073 VFCVectorSODLVFCid46 "ExteriorLightsHazard";
CM_ SG_ 1073 VFCVectorSODLVFCid47 "VFC47";
CM_ SG_ 1073 VFCVectorSODLVFCid48 "DoorOpenWarning";
CM_ SG_ 1073 VFCVectorSODLVFCid49 "ChargingLVInit";
CM_ SG_ 1073 VFCVectorSODLVFCid5 "VFC5";
CM_ SG_ 1073 VFCVectorSODLVFCid50 "VFC50";
CM_ SG_ 1073 VFCVectorSODLVFCid51 "VFC51";
CM_ SG_ 1073 VFCVectorSODLVFCid52 "HVBatteryThermalEventWarning";
CM_ SG_ 1073 VFCVectorSODLVFCid53 "VisualAssist";
CM_ SG_ 1073 VFCVectorSODLVFCid54 "PassiveSafety";
CM_ SG_ 1073 VFCVectorSODLVFCid55 "LifeDetection";
CM_ SG_ 1073 VFCVectorSODLVFCid56 "BackboneFlexray";
CM_ SG_ 1073 VFCVectorSODLVFCid57 "Functionmarket";
CM_ SG_ 1073 VFCVectorSODLVFCid58 "VFC58";
CM_ SG_ 1073 VFCVectorSODLVFCid59 "VFC59";
CM_ SG_ 1073 VFCVectorSODLVFCid6 "SettingsVehicle";
CM_ SG_ 1073 VFCVectorSODLVFCid60 "VFC60";
CM_ SG_ 1073 VFCVectorSODLVFCid61 "VFC61";
CM_ SG_ 1073 VFCVectorSODLVFCid7 "VFC7";
CM_ SG_ 1073 VFCVectorSODLVFCid8 "VFC8";
CM_ SG_ 1073 VFCVectorSODLVFCid9 "IPWakeup";
BA_DEF_ BO_ "CANFD_BRS" ENUM "0","1";
BA_DEF_ BO_ "GenMsgCycleTime" INT 0 65536;
BA_DEF_ BO_ "GenMsgDelayTime" INT 0 65536;
BA_DEF_ BO_ "GenMsgSendType" ENUM "cyclic", "spontaneous", "not-used", "not-used", "not-used", "cyclicAndSpontaneous", "not-used", "cyclicIfActive", "NoMsgSendType";
BA_DEF_ BO_ "GenMsgStartDelayTime" INT 0 65536;
BA_DEF_ BO_ "VFrameFormat" ENUM "StandardCAN","ExtendedCAN","reserved","J1939PG","reserved","reserved","reserved","reserved","reserved","reserved","reserved","reserved","reserved","reserved","StandardCAN_FD","ExtendedCAN_FD";
BA_DEF_ SG_ "GenSigSendType" ENUM "Cyclic","OnWrite","OnWriteWithRepetition","OnChange","OnChangeWithRepetition","IfActive","IfActiveWithRepetition","NoSigSendType";
BA_DEF_ SG_ "GenSigStartValue" HEX 0 80000000;
BA_DEF_ BO_ "GenMsgILSupport" ENUM "No","Yes";
BA_DEF_ BO_ "NmAsrMessage" ENUM "No","Yes";
BA_DEF_ SG_ "GenSigFuncType" ENUM "NoFunction","n/a","n/a","n/a","n/a","n/a","n/a","n/a","n/a","n/a","n/a","n/a","n/a","n/a","n/a","CHK","CNTR","n/a","n/a","n/a","CNTR_AR_01","CRC_AR_01_BOTH","CRC_AR_01_ALT","CRC_AR_01_LOW","CRC_AR_01_NIBBLE","CNTR_AR_04","CRC_AR_04A","CNTR_AR_05","CRC_AR_05";
BA_DEF_ SG_ "GenSigDataID" STRING;
BA_DEF_ SG_ "SigGroup" STRING;
BA_DEF_DEF_ "CANFD_BRS" "1";
BA_DEF_DEF_ "GenSigStartValue" 0;
BA_DEF_DEF_ "VFrameFormat" "J1939PG";
BA_DEF_DEF_ "GenSigSendType" "NoSigSendType";
BA_DEF_DEF_ "GenMsgCycleTime" 0;
BA_DEF_DEF_ "GenMsgDelayTime" 0;
BA_DEF_DEF_ "GenMsgStartDelayTime" 0;
BA_DEF_DEF_ "GenMsgSendType" "NoMsgSendType";
BA_DEF_DEF_ "GenMsgILSupport" "Yes";
BA_DEF_DEF_ "NmAsrMessage" "No";
BA_DEF_DEF_ "GenSigFuncType" "NoFunction";
BA_DEF_DEF_ "GenSigDataID" "";
BA_DEF_DEF_ "SigGroup" "";

BA_ "GenMsgCycleTime" BO_ 1384 500.000;
BA_ "GenMsgSendType" BO_ 1384 0;
BA_ "VFrameFormat" BO_ 1384 0;

BA_ "GenMsgDelayTime" BO_ 1320 20.000;
BA_ "GenMsgSendType" BO_ 1320 1;
BA_ "VFrameFormat" BO_ 1320 0;

BA_ "GenMsgDelayTime" BO_ 337 50.000;
BA_ "GenMsgSendType" BO_ 337 1;
BA_ "VFrameFormat" BO_ 337 14;

BA_ "GenMsgCycleTime" BO_ 87 10.000;
BA_ "GenMsgSendType" BO_ 87 0;
BA_ "VFrameFormat" BO_ 87 14;

BA_ "GenMsgDelayTime" BO_ 2015 5.000;
BA_ "GenMsgSendType" BO_ 2015 1;
BA_ "VFrameFormat" BO_ 2015 0;

BA_ "GenMsgDelayTime" BO_ 2047 5.000;
BA_ "GenMsgSendType" BO_ 2047 1;
BA_ "VFrameFormat" BO_ 2047 14;

BA_ "GenMsgDelayTime" BO_ 1860 5.000;
BA_ "GenMsgSendType" BO_ 1860 1;
BA_ "VFrameFormat" BO_ 1860 14;

BA_ "GenMsgDelayTime" BO_ 1841 5.000;
BA_ "GenMsgSendType" BO_ 1841 1;
BA_ "VFrameFormat" BO_ 1841 14;

BA_ "GenMsgDelayTime" BO_ 1840 5.000;
BA_ "GenMsgSendType" BO_ 1840 1;
BA_ "VFrameFormat" BO_ 1840 14;

BA_ "GenMsgDelayTime" BO_ 1872 5.000;
BA_ "GenMsgSendType" BO_ 1872 1;
BA_ "VFrameFormat" BO_ 1872 14;

BA_ "GenMsgDelayTime" BO_ 1873 5.000;
BA_ "GenMsgSendType" BO_ 1873 1;
BA_ "VFrameFormat" BO_ 1873 14;

BA_ "GenMsgDelayTime" BO_ 1793 5.000;
BA_ "GenMsgSendType" BO_ 1793 1;
BA_ "VFrameFormat" BO_ 1793 14;

BA_ "GenMsgDelayTime" BO_ 2023 5.000;
BA_ "GenMsgSendType" BO_ 2023 1;
BA_ "VFrameFormat" BO_ 2023 0;

BA_ "GenMsgDelayTime" BO_ 1921 5.000;
BA_ "GenMsgSendType" BO_ 1921 1;
BA_ "VFrameFormat" BO_ 1921 14;

BA_ "GenMsgDelayTime" BO_ 1925 5.000;
BA_ "GenMsgSendType" BO_ 1925 1;
BA_ "VFrameFormat" BO_ 1925 14;

BA_ "GenMsgDelayTime" BO_ 1889 5.000;
BA_ "GenMsgSendType" BO_ 1889 1;
BA_ "VFrameFormat" BO_ 1889 14;

BA_ "GenMsgDelayTime" BO_ 1808 5.000;
BA_ "GenMsgSendType" BO_ 1808 1;
BA_ "VFrameFormat" BO_ 1808 14;

BA_ "GenMsgDelayTime" BO_ 1891 5.000;
BA_ "GenMsgSendType" BO_ 1891 1;
BA_ "VFrameFormat" BO_ 1891 14;

BA_ "GenMsgDelayTime" BO_ 1904 5.000;
BA_ "GenMsgSendType" BO_ 1904 1;
BA_ "VFrameFormat" BO_ 1904 14;

BA_ "GenMsgDelayTime" BO_ 1811 5.000;
BA_ "GenMsgSendType" BO_ 1811 1;
BA_ "VFrameFormat" BO_ 1811 14;

BA_ "GenMsgDelayTime" BO_ 1906 5.000;
BA_ "GenMsgSendType" BO_ 1906 1;
BA_ "VFrameFormat" BO_ 1906 14;

BA_ "GenMsgDelayTime" BO_ 1813 5.000;
BA_ "GenMsgSendType" BO_ 1813 1;
BA_ "VFrameFormat" BO_ 1813 14;

BA_ "GenMsgDelayTime" BO_ 1812 5.000;
BA_ "GenMsgSendType" BO_ 1812 1;
BA_ "VFrameFormat" BO_ 1812 14;

BA_ "GenMsgDelayTime" BO_ 1826 5.000;
BA_ "GenMsgSendType" BO_ 1826 1;
BA_ "VFrameFormat" BO_ 1826 14;

BA_ "GenMsgDelayTime" BO_ 1810 5.000;
BA_ "GenMsgSendType" BO_ 1810 1;
BA_ "VFrameFormat" BO_ 1810 14;

BA_ "GenMsgCycleTime" BO_ 488 50.000;
BA_ "GenMsgSendType" BO_ 488 0;
BA_ "VFrameFormat" BO_ 488 14;

BA_ "GenMsgCycleTime" BO_ 775 100.000;
BA_ "GenMsgSendType" BO_ 775 0;
BA_ "VFrameFormat" BO_ 775 14;

BA_ "GenMsgCycleTime" BO_ 86 10.000;
BA_ "GenMsgSendType" BO_ 86 0;
BA_ "VFrameFormat" BO_ 86 14;

BA_ "GenMsgCycleTime" BO_ 373 20.000;
BA_ "GenMsgSendType" BO_ 373 0;
BA_ "VFrameFormat" BO_ 373 14;

BA_ "GenMsgCycleTime" BO_ 832 120.000;
BA_ "GenMsgSendType" BO_ 832 0;
BA_ "VFrameFormat" BO_ 832 14;

BA_ "GenMsgCycleTime" BO_ 889 200.000;
BA_ "GenMsgSendType" BO_ 889 0;
BA_ "VFrameFormat" BO_ 889 14;

BA_ "GenMsgCycleTime" BO_ 751 80.000;
BA_ "GenMsgSendType" BO_ 751 0;
BA_ "VFrameFormat" BO_ 751 14;

BA_ "GenMsgDelayTime" BO_ 824 40.000;
BA_ "GenMsgSendType" BO_ 824 1;
BA_ "VFrameFormat" BO_ 824 14;

BA_ "GenMsgDelayTime" BO_ 501 100.000;
BA_ "GenMsgSendType" BO_ 501 1;
BA_ "VFrameFormat" BO_ 501 14;

BA_ "GenMsgCycleTime" BO_ 504 50.000;
BA_ "GenMsgSendType" BO_ 504 0;
BA_ "VFrameFormat" BO_ 504 14;

BA_ "GenMsgCycleTime" BO_ 352 30.000;
BA_ "GenMsgSendType" BO_ 352 0;
BA_ "VFrameFormat" BO_ 352 14;

BA_ "GenMsgDelayTime" BO_ 1289 20.000;
BA_ "GenMsgSendType" BO_ 1289 1;
BA_ "VFrameFormat" BO_ 1289 0;

BA_ "GenMsgDelayTime" BO_ 821 25.000;
BA_ "GenMsgSendType" BO_ 821 1;
BA_ "VFrameFormat" BO_ 821 14;

BA_ "GenMsgCycleTime" BO_ 528 100.000;
BA_ "GenMsgSendType" BO_ 528 0;
BA_ "VFrameFormat" BO_ 528 14;

BA_ "GenMsgCycleTime" BO_ 96 10.000;
BA_ "GenMsgSendType" BO_ 96 0;
BA_ "VFrameFormat" BO_ 96 14;

BA_ "GenMsgCycleTime" BO_ 587 80.000;
BA_ "GenMsgSendType" BO_ 587 0;
BA_ "VFrameFormat" BO_ 587 14;

BA_ "GenMsgCycleTime" BO_ 784 200.000;
BA_ "GenMsgSendType" BO_ 784 0;
BA_ "VFrameFormat" BO_ 784 14;

BA_ "GenMsgCycleTime" BO_ 274 40.000;
BA_ "GenMsgSendType" BO_ 274 0;
BA_ "VFrameFormat" BO_ 274 14;

BA_ "GenMsgCycleTime" BO_ 1073 500.000;
BA_ "GenMsgSendType" BO_ 1073 0;
BA_ "VFrameFormat" BO_ 1073 14;

BA_ "GenMsgDelayTime" BO_ 1633 5.000;
BA_ "GenMsgSendType" BO_ 1633 1;
BA_ "VFrameFormat" BO_ 1633 14;

BA_ "GenMsgDelayTime" BO_ 1552 5.000;
BA_ "GenMsgSendType" BO_ 1552 1;
BA_ "VFrameFormat" BO_ 1552 14;

BA_ "GenMsgDelayTime" BO_ 1635 5.000;
BA_ "GenMsgSendType" BO_ 1635 1;
BA_ "VFrameFormat" BO_ 1635 14;

BA_ "GenMsgDelayTime" BO_ 1648 5.000;
BA_ "GenMsgSendType" BO_ 1648 1;
BA_ "VFrameFormat" BO_ 1648 14;

BA_ "GenMsgDelayTime" BO_ 1555 5.000;
BA_ "GenMsgSendType" BO_ 1555 1;
BA_ "VFrameFormat" BO_ 1555 14;

BA_ "GenMsgDelayTime" BO_ 1650 5.000;
BA_ "GenMsgSendType" BO_ 1650 1;
BA_ "VFrameFormat" BO_ 1650 14;

BA_ "GenMsgDelayTime" BO_ 1557 5.000;
BA_ "GenMsgSendType" BO_ 1557 1;
BA_ "VFrameFormat" BO_ 1557 14;

BA_ "GenMsgDelayTime" BO_ 1556 5.000;
BA_ "GenMsgSendType" BO_ 1556 1;
BA_ "VFrameFormat" BO_ 1556 14;
BA_ "GenMsgILSupport" BO_ 1320 0;
BA_ "GenMsgILSupport" BO_ 1289 0;
BA_ "NmAsrMessage" BO_ 1320 1;
BA_ "NmAsrMessage" BO_ 1289 1;
BA_ "GenSigSendType" SG_ 352 AccFusnTrfcReq 0;
BA_ "GenSigSendType" SG_ 86 AsyAutDrvCtrlTypDIMReq 0;
BA_ "GenSigSendType" SG_ 488 AsyEmgyManoeuvreAidActvSts 0;
BA_ "GenSigSendType" SG_ 488 AsyNoaUpgradeswitch 0;
BA_ "GenSigSendType" SG_ 373 AutoHldSoftSwtCtrlSt 0;
BA_ "GenSigSendType" SG_ 352 BSDSwOnOff 0;
BA_ "GenSigSendType" SG_ 488 BSDSwOnOffandWarnType 0;
BA_ "GenSigStartValue" SG_ 488 BSDSwOnOffandWarnType 1;
BA_ "GenSigSendType" SG_ 352 BSDaudioOnOff 0;
BA_ "GenSigSendType" SG_ 832 BiasedPosnFromSatlt1Cntr 0;
BA_ "GenSigSendType" SG_ 832 BiasedPosnFromSatlt1PosnLat 0;
BA_ "GenSigStartValue" SG_ 832 BiasedPosnFromSatlt1PosnLat 323999740.8002074;
BA_ "GenSigSendType" SG_ 832 BiasedPosnFromSatlt1PosnLgt 0;
BA_ "GenSigStartValue" SG_ 832 BiasedPosnFromSatlt1PosnLgt 647999481.6004148;
BA_ "GenSigSendType" SG_ 86 BiasedPosnFromSatltCntr 0;
BA_ "GenSigSendType" SG_ 86 BiasedPosnFromSatltPosnLat 0;
BA_ "GenSigStartValue" SG_ 86 BiasedPosnFromSatltPosnLat 323999740.8002074;
BA_ "GenSigSendType" SG_ 86 BiasedPosnFromSatltPosnLgt 0;
BA_ "GenSigStartValue" SG_ 86 BiasedPosnFromSatltPosnLgt 647999481.6004148;
BA_ "GenSigSendType" SG_ 86 BiasedPosnFromSatltTiForMins 0;
BA_ "GenSigSendType" SG_ 86 BiasedPosnFromSatltTiForMsec 0;
BA_ "GenSigSendType" SG_ 86 BiasedPosnFromSatltTiForSec 0;
BA_ "GenSigSendType" SG_ 352 BkpOfDstTrvld 0;
BA_ "GenSigSendType" SG_ 488 CamFltsStsFromDHU 0;
BA_ "GenSigSendType" SG_ 488 CllsnAidSnvtySeldSts 0;
BA_ "GenSigSendType" SG_ 488 CllsnMtgtnActvSeldSts 0;
BA_ "GenSigSendType" SG_ 488 CmftBrkStopSwtSts 0;
BA_ "GenSigStartValue" SG_ 488 CmftBrkStopSwtSts 1;
BA_ "GenSigSendType" SG_ 751 CpmswOnOff 0;
BA_ "GenSigSendType" SG_ 373 CrossInfoDirOfNavRut 0;
BA_ "GenSigSendType" SG_ 373 CrossInfoDstToCros 0;
BA_ "GenSigStartValue" SG_ 373 CrossInfoDstToCros 511;
BA_ "GenSigSendType" SG_ 373 CrossInfoTrfcLi 0;
BA_ "GenSigSendType" SG_ 488 CrsCtrlTiGapAdjReq 0;
BA_ "GenSigSendType" SG_ 373 CtraSwOnOff 0;
BA_ "GenSigSendType" SG_ 751 CtryCodInfo 0;
BA_ "GenSigSendType" SG_ 488 CurrentRoadLvl 0;
BA_ "GenSigSendType" SG_ 373 DIMStsDistbn 0;
BA_ "GenSigSendType" SG_ 373 DOWSwOnOff 0;
BA_ "GenSigSendType" SG_ 86 DrvModReq 0;
BA_ "GenSigSendType" SG_ 488 DrvOffReq 0;
BA_ "GenSigDataID" SG_ 373 DrvrACCFctDeactvnReqChks "0x2142";
BA_ "GenSigFuncType" SG_ 373 DrvrACCFctDeactvnReqChks 15;
BA_ "GenSigSendType" SG_ 373 DrvrACCFctDeactvnReqChks 0;
BA_ "GenSigFuncType" SG_ 373 DrvrACCFctDeactvnReqCntr 16;
BA_ "GenSigSendType" SG_ 373 DrvrACCFctDeactvnReqCntr 0;
BA_ "GenSigSendType" SG_ 373 DrvrACCFctDeactvnReqSts 0;
BA_ "GenSigSendType" SG_ 87 DrvrACCrsSetSpdReqDrvrACCrsCtrlSetInSpdReq 0;
BA_ "GenSigSendType" SG_ 87 DrvrACCrsSetSpdReqDrvrCrsSetSpdReq 0;
BA_ "GenSigSendType" SG_ 87 DrvrACCrsSetSpdReqSetSpdForCrsCtrlFctActive 0;
BA_ "GenSigSendType" SG_ 274 DrvrAsscSysIndcrReq 0;
BA_ "GenSigSendType" SG_ 274 DrvrAsscSysIndcrReq1 0;
BA_ "GenSigSendType" SG_ 274 DrvrAsscSysSts 0;
BA_ "GenSigSendType" SG_ 488 DrvrCrsCtrlFctActvReq 0;
BA_ "GenSigSendType" SG_ 488 DrvrDecStsFromDHU 0;
BA_ "GenSigSendType" SG_ 889 DrvrFatiLvlFromDHU 0;
BA_ "GenSigSendType" SG_ 373 DrvrLaneChgAutActvSts 0;
BA_ "GenSigSendType" SG_ 488 DrvrPfmncAlrmReqFromDHU 0;
BA_ "GenSigSendType" SG_ 488 DrvrPfmncSwitchStsFromDHU 0;
BA_ "GenSigStartValue" SG_ 488 DrvrPfmncSwitchStsFromDHU 1;
BA_ "GenSigSendType" SG_ 488 EmgyLaneKeepAidActvSts 0;
BA_ "GenSigSendType" SG_ 352 EpbApplyAutSetg 0;
BA_ "GenSigSendType" SG_ 86 EpbSoftSwtCtrlSt 0;
BA_ "GenSigSendType" SG_ 889 EscSptModReqdByDrvr 0;
BA_ "GenSigSendType" SG_ 488 EyeGazeDirVecFromDHUX 0;
BA_ "GenSigStartValue" SG_ 488 EyeGazeDirVecFromDHUX 32767;
BA_ "GenSigSendType" SG_ 488 EyeGazeDirVecFromDHUY 0;
BA_ "GenSigStartValue" SG_ 488 EyeGazeDirVecFromDHUY 32767;
BA_ "GenSigSendType" SG_ 488 EyeGazeDirVecFromDHUZ 0;
BA_ "GenSigStartValue" SG_ 488 EyeGazeDirVecFromDHUZ 32767;
BA_ "GenSigSendType" SG_ 488 EyeGazeFromDHUEyeGazeZone 0;
BA_ "GenSigSendType" SG_ 488 EyeGazeFromDHUEyeGazeZoneTime 0;
BA_ "GenSigSendType" SG_ 488 EyeGzaeDirOriFromDHUX 0;
BA_ "GenSigStartValue" SG_ 488 EyeGzaeDirOriFromDHUX 32767;
BA_ "GenSigSendType" SG_ 488 EyeGzaeDirOriFromDHUY 0;
BA_ "GenSigStartValue" SG_ 488 EyeGzaeDirOriFromDHUY 32767;
BA_ "GenSigSendType" SG_ 488 EyeGzaeDirOriFromDHUZ 0;
BA_ "GenSigStartValue" SG_ 488 EyeGzaeDirOriFromDHUZ 32767;
BA_ "GenSigSendType" SG_ 488 EyeOnRoadFromDHUChks 0;
BA_ "GenSigSendType" SG_ 488 EyeOnRoadFromDHUCntr 0;
BA_ "GenSigSendType" SG_ 488 EyeOnRoadFromDHUEyesOnRoad 0;
BA_ "GenSigSendType" SG_ 488 EyeOpenFromDHUEyeOpenDegLe 0;
BA_ "GenSigSendType" SG_ 488 EyeOpenFromDHUEyeOpenDegRi 0;
BA_ "GenSigSendType" SG_ 488 EyeOpenFromDHUEyeOpenLe 0;
BA_ "GenSigSendType" SG_ 488 EyeOpenFromDHUEyeOpenRi 0;
BA_ "GenSigSendType" SG_ 488 EyeOpenFromDHUEyeVisibleLe 0;
BA_ "GenSigSendType" SG_ 488 EyeOpenFromDHUEyeVisibleRi 0;
BA_ "GenSigSendType" SG_ 488 EyeOpenFromDHUFaceVisible 0;
BA_ "GenSigSendType" SG_ 775 FogSetReReq 0;
BA_ "GenSigSendType" SG_ 86 FuLvlIndcdFuLvlValFromFuTbl 0;
BA_ "GenSigSendType" SG_ 86 FuLvlIndcdGenQF 0;
BA_ "GenSigSendType" SG_ 775 GNSSSolution1Cntr 0;
BA_ "GenSigSendType" SG_ 775 GNSSSolution1NoOfSatItForSysNo1 0;
BA_ "GenSigSendType" SG_ 775 GNSSSolution1NoOfSatItForSysNo2 0;
BA_ "GenSigSendType" SG_ 775 GNSSSolution1NoOfSatItForSysNo3 0;
BA_ "GenSigSendType" SG_ 775 GNSSSolution1NoOfSatItForSysNo4 0;
BA_ "GenSigSendType" SG_ 775 GNSSSolution1NoOfSatItForSysNo5 0;
BA_ "GenSigSendType" SG_ 775 GNSSSolution1NoOfSatItForSysNo6 0;
BA_ "GenSigSendType" SG_ 775 GNSSSolution1NoOfSatItForSysNo7 0;
BA_ "GenSigSendType" SG_ 775 GNSSSolution1SatItSysNo1InUse 0;
BA_ "GenSigSendType" SG_ 775 GNSSSolution1SatItSysNo2InUse 0;
BA_ "GenSigSendType" SG_ 775 GNSSSolution1SatItSysNo3InUse 0;
BA_ "GenSigSendType" SG_ 775 GNSSSolution1SatItSysNo4InUse 0;
BA_ "GenSigSendType" SG_ 775 GNSSSolution1SatItSysNo5InUse 0;
BA_ "GenSigSendType" SG_ 775 GNSSSolution1SatItSysNo6InUse 0;
BA_ "GenSigSendType" SG_ 775 GNSSSolution1SatItSysNo7InUse 0;
BA_ "GenSigSendType" SG_ 775 GNSSSolution1SatltPosnStsPrm1 0;
BA_ "GenSigSendType" SG_ 775 GNSSSolution1SatltPosnStsPrm2 0;
BA_ "GenSigSendType" SG_ 775 GNSSSolution2Cntr 0;
BA_ "GenSigSendType" SG_ 775 GNSSSolution2PreHozlDil 0;
BA_ "GenSigSendType" SG_ 775 GNSSSolution2PrePosnDil 0;
BA_ "GenSigSendType" SG_ 775 GNSSSolution2PreVertDil 0;
BA_ "GenSigSendType" SG_ 775 GNSSSolutionCntr 0;
BA_ "GenSigSendType" SG_ 775 GNSSSolutionNoOfSatltForSysNo1 0;
BA_ "GenSigSendType" SG_ 775 GNSSSolutionNoOfSatltForSysNo2 0;
BA_ "GenSigSendType" SG_ 775 GNSSSolutionNoOfSatltForSysNo3 0;
BA_ "GenSigSendType" SG_ 775 GNSSSolutionNoOfSatltForSysNo4 0;
BA_ "GenSigSendType" SG_ 775 GNSSSolutionNoOfSatltForSysNo5 0;
BA_ "GenSigSendType" SG_ 775 GNSSSolutionNoOfSatltForSysNo6 0;
BA_ "GenSigSendType" SG_ 775 GNSSSolutionNoOfSatltForSysNo7 0;
BA_ "GenSigSendType" SG_ 775 GNSSSolutionPreHozlDil 0;
BA_ "GenSigSendType" SG_ 775 GNSSSolutionPrePosnDil 0;
BA_ "GenSigSendType" SG_ 775 GNSSSolutionPreVertDil 0;
BA_ "GenSigSendType" SG_ 775 GNSSSolutionSatltPosnStsPrm1 0;
BA_ "GenSigSendType" SG_ 775 GNSSSolutionSatltPosnStsPrm2 0;
BA_ "GenSigSendType" SG_ 775 GNSSSolutionSatltSysNo1InUse 0;
BA_ "GenSigSendType" SG_ 775 GNSSSolutionSatltSysNo2InUse 0;
BA_ "GenSigSendType" SG_ 775 GNSSSolutionSatltSysNo3InUse 0;
BA_ "GenSigSendType" SG_ 775 GNSSSolutionSatltSysNo4InUse 0;
BA_ "GenSigSendType" SG_ 775 GNSSSolutionSatltSysNo5InUse 0;
BA_ "GenSigSendType" SG_ 775 GNSSSolutionSatltSysNo6InUse 0;
BA_ "GenSigSendType" SG_ 775 GNSSSolutionSatltSysNo7InUse 0;
BA_ "GenSigSendType" SG_ 775 GNSSSolutionTiForMins 0;
BA_ "GenSigSendType" SG_ 775 GNSSSolutionTiForMsec 0;
BA_ "GenSigSendType" SG_ 775 GNSSSolutionTiForSec 0;
BA_ "GenSigDataID" SG_ 96 GearPrkgAssiReqGroupChks "0x02";
BA_ "GenSigFuncType" SG_ 96 GearPrkgAssiReqGroupChks 15;
BA_ "GenSigSendType" SG_ 96 GearPrkgAssiReqGroupChks 0;
BA_ "GenSigFuncType" SG_ 96 GearPrkgAssiReqGroupCntr 16;
BA_ "GenSigSendType" SG_ 96 GearPrkgAssiReqGroupCntr 0;
BA_ "GenSigSendType" SG_ 96 GearPrkgAssiReqGroupGearPrkgAssiReq1 0;
BA_ "GenSigSendType" SG_ 86 GpsStatus 0;
BA_ "GenSigStartValue" SG_ 86 GpsStatus 1;
BA_ "GenSigSendType" SG_ 751 HMIAutoShowModSet 0;
BA_ "GenSigSendType" SG_ 488 HdPosnValidSigFromDHUX 0;
BA_ "GenSigStartValue" SG_ 488 HdPosnValidSigFromDHUX 32767;
BA_ "GenSigSendType" SG_ 488 HdPosnValidSigFromDHUY 0;
BA_ "GenSigStartValue" SG_ 488 HdPosnValidSigFromDHUY 32767;
BA_ "GenSigSendType" SG_ 488 HdPosnValidSigFromDHUZ 0;
BA_ "GenSigStartValue" SG_ 488 HdPosnValidSigFromDHUZ 32767;
BA_ "GenSigSendType" SG_ 488 HdRotateAgFromDHUHdPitchAg 0;
BA_ "GenSigStartValue" SG_ 488 HdRotateAgFromDHUHdPitchAg 900;
BA_ "GenSigSendType" SG_ 488 HdRotateAgFromDHUHdRollAg 0;
BA_ "GenSigStartValue" SG_ 488 HdRotateAgFromDHUHdRollAg 900;
BA_ "GenSigSendType" SG_ 488 HdRotateAgFromDHUHdYawAg 0;
BA_ "GenSigStartValue" SG_ 488 HdRotateAgFromDHUHdYawAg 900;
BA_ "GenSigSendType" SG_ 488 HeadGazeDirOriFromDHUX 0;
BA_ "GenSigStartValue" SG_ 488 HeadGazeDirOriFromDHUX 32767;
BA_ "GenSigSendType" SG_ 488 HeadGazeDirOriFromDHUY 0;
BA_ "GenSigStartValue" SG_ 488 HeadGazeDirOriFromDHUY 32767;
BA_ "GenSigSendType" SG_ 488 HeadGazeDirOriFromDHUZ 0;
BA_ "GenSigStartValue" SG_ 488 HeadGazeDirOriFromDHUZ 32767;
BA_ "GenSigSendType" SG_ 488 HeadGazeDirVecFromDHUX 0;
BA_ "GenSigStartValue" SG_ 488 HeadGazeDirVecFromDHUX 32767;
BA_ "GenSigSendType" SG_ 488 HeadGazeDirVecFromDHUY 0;
BA_ "GenSigStartValue" SG_ 488 HeadGazeDirVecFromDHUY 32767;
BA_ "GenSigSendType" SG_ 488 HeadGazeDirVecFromDHUZ 0;
BA_ "GenSigStartValue" SG_ 488 HeadGazeDirVecFromDHUZ 32767;
BA_ "GenSigSendType" SG_ 751 HillDwnCtrlSt 0;
BA_ "GenSigSendType" SG_ 373 HmiDrvrSodReqChg 0;
BA_ "GenSigSendType" SG_ 488 HmiDrvrSodReqPilot 0;
BA_ "GenSigSendType" SG_ 373 HmiSodLanChgSwitch 0;
BA_ "GenSigSendType" SG_ 373 HmiStrangerModMenuSetActvInActv 0;
BA_ "GenSigSendType" SG_ 373 HmiStrangerModMenuSetPasswordSt 0;
BA_ "GenSigSendType" SG_ 373 HmiStrangerModMenuSetPrivateLockSt 0;
BA_ "GenSigSendType" SG_ 373 HmiStrangerModMenuSetSpdLim 0;
BA_ "GenSigSendType" SG_ 751 HznDataCountryCode 0;
BA_ "GenSigStartValue" SG_ 751 HznDataCountryCode 156;
BA_ "GenSigSendType" SG_ 751 HznDataCyclicCounter 0;
BA_ "GenSigSendType" SG_ 751 HznDataDrivingSide 0;
BA_ "GenSigStartValue" SG_ 751 HznDataDrivingSide 1;
BA_ "GenSigSendType" SG_ 751 HznDataHardwareVersion 0;
BA_ "GenSigSendType" SG_ 751 HznDataMajorProtocolVersion 0;
BA_ "GenSigSendType" SG_ 751 HznDataMapProvider 0;
BA_ "GenSigSendType" SG_ 751 HznDataMapVersionYear 0;
BA_ "GenSigSendType" SG_ 751 HznDataMapVersionYearQuarter 0;
BA_ "GenSigSendType" SG_ 751 HznDataMessageType 0;
BA_ "GenSigStartValue" SG_ 751 HznDataMessageType 6;
BA_ "GenSigSendType" SG_ 751 HznDataMinorProtocolSubVersion 0;
BA_ "GenSigSendType" SG_ 751 HznDataMinorProtocolVersion 0;
BA_ "GenSigSendType" SG_ 751 HznDataRegionCode 0;
BA_ "GenSigSendType" SG_ 751 HznDataSpeedUnits 0;
BA_ "GenSigSendType" SG_ 824 HznEdgeComplexIntersection 1;
BA_ "GenSigSendType" SG_ 824 HznEdgeCyclicCounter 1;
BA_ "GenSigSendType" SG_ 824 HznEdgeFormOfWay 1;
BA_ "GenSigSendType" SG_ 824 HznEdgeFunctionalRoadClass 1;
BA_ "GenSigSendType" SG_ 824 HznEdgeLastStubAtOffset 1;
BA_ "GenSigSendType" SG_ 824 HznEdgeMessageType 1;
BA_ "GenSigStartValue" SG_ 824 HznEdgeMessageType 3;
BA_ "GenSigSendType" SG_ 824 HznEdgeNumberOfLanesInDrivingDirection 1;
BA_ "GenSigSendType" SG_ 824 HznEdgeNumberOfLanesInOppositeDirection 1;
BA_ "GenSigSendType" SG_ 824 HznEdgeOffset 1;
BA_ "GenSigSendType" SG_ 824 HznEdgePartOfCalculatedRoute 1;
BA_ "GenSigSendType" SG_ 824 HznEdgePathIndex 1;
BA_ "GenSigSendType" SG_ 824 HznEdgeRelativeProbability 1;
BA_ "GenSigSendType" SG_ 824 HznEdgeRetransmission 1;
BA_ "GenSigSendType" SG_ 824 HznEdgeRightofWay 1;
BA_ "GenSigStartValue" SG_ 824 HznEdgeRightofWay 2;
BA_ "GenSigSendType" SG_ 824 HznEdgeSubPathIndex 1;
BA_ "GenSigStartValue" SG_ 824 HznEdgeSubPathIndex 5;
BA_ "GenSigSendType" SG_ 824 HznEdgeTurnAngle 1;
BA_ "GenSigSendType" SG_ 824 HznEdgeUpdate 1;
BA_ "GenSigSendType" SG_ 488 HznPosnCurrentLane 0;
BA_ "GenSigSendType" SG_ 488 HznPosnCyclicCounter 0;
BA_ "GenSigSendType" SG_ 488 HznPosnMessageType 0;
BA_ "GenSigStartValue" SG_ 488 HznPosnMessageType 1;
BA_ "GenSigSendType" SG_ 488 HznPosnOffset 0;
BA_ "GenSigSendType" SG_ 488 HznPosnPathIndex 0;
BA_ "GenSigSendType" SG_ 488 HznPosnPositionAge 0;
BA_ "GenSigSendType" SG_ 488 HznPosnPositionConfidence 0;
BA_ "GenSigSendType" SG_ 488 HznPosnPositionIndex 0;
BA_ "GenSigSendType" SG_ 488 HznPosnPositionProbability 0;
BA_ "GenSigSendType" SG_ 488 HznPosnRelativeHeading 0;
BA_ "GenSigSendType" SG_ 488 HznPosnSpeed 0;
BA_ "GenSigSendType" SG_ 824 HznProfLongControlPoint 1;
BA_ "GenSigSendType" SG_ 824 HznProfLongCyclicCounter 1;
BA_ "GenSigSendType" SG_ 824 HznProfLongMessageType 1;
BA_ "GenSigStartValue" SG_ 824 HznProfLongMessageType 5;
BA_ "GenSigSendType" SG_ 824 HznProfLongOffset 1;
BA_ "GenSigSendType" SG_ 824 HznProfLongPathIndex 1;
BA_ "GenSigSendType" SG_ 824 HznProfLongProfileType 1;
BA_ "GenSigSendType" SG_ 824 HznProfLongRetransmission 1;
BA_ "GenSigSendType" SG_ 824 HznProfLongUpdate 1;
BA_ "GenSigSendType" SG_ 824 HznProfLongValue 1;
BA_ "GenSigSendType" SG_ 824 HznProfShoAccuracy 1;
BA_ "GenSigStartValue" SG_ 824 HznProfShoAccuracy 3;
BA_ "GenSigSendType" SG_ 824 HznProfShoControlPoint 1;
BA_ "GenSigSendType" SG_ 824 HznProfShoCyclicCounter 1;
BA_ "GenSigSendType" SG_ 824 HznProfShoDistance1 1;
BA_ "GenSigSendType" SG_ 824 HznProfShoMessageType 1;
BA_ "GenSigStartValue" SG_ 824 HznProfShoMessageType 4;
BA_ "GenSigSendType" SG_ 824 HznProfShoOffset 1;
BA_ "GenSigSendType" SG_ 824 HznProfShoPathIndex 1;
BA_ "GenSigSendType" SG_ 824 HznProfShoProfileType 1;
BA_ "GenSigSendType" SG_ 824 HznProfShoRetransmission 1;
BA_ "GenSigSendType" SG_ 824 HznProfShoUpdate 1;
BA_ "GenSigSendType" SG_ 824 HznProfShoValue0 1;
BA_ "GenSigSendType" SG_ 824 HznProfShoValue1 1;
BA_ "GenSigSendType" SG_ 824 HznSegBridge 1;
BA_ "GenSigSendType" SG_ 824 HznSegBuiltupArea 1;
BA_ "GenSigSendType" SG_ 824 HznSegComplexIntersection 1;
BA_ "GenSigSendType" SG_ 824 HznSegCyclicCounter 1;
BA_ "GenSigSendType" SG_ 824 HznSegDividedRoad 1;
BA_ "GenSigSendType" SG_ 824 HznSegEffectiveSpdLimit 1;
BA_ "GenSigSendType" SG_ 824 HznSegEffectiveSpeedLimitType 1;
BA_ "GenSigSendType" SG_ 824 HznSegFormofWay 1;
BA_ "GenSigSendType" SG_ 824 HznSegFunctionalRoadClass 1;
BA_ "GenSigSendType" SG_ 824 HznSegMessageType 1;
BA_ "GenSigStartValue" SG_ 824 HznSegMessageType 2;
BA_ "GenSigSendType" SG_ 824 HznSegNumberoflanesindrivingdirection 1;
BA_ "GenSigSendType" SG_ 824 HznSegNumberoflanesinoppositedirection 1;
BA_ "GenSigSendType" SG_ 824 HznSegOffset 1;
BA_ "GenSigSendType" SG_ 824 HznSegPartOfCalculatedRoute 1;
BA_ "GenSigSendType" SG_ 824 HznSegPathIndex 1;
BA_ "GenSigSendType" SG_ 824 HznSegRelativeProbability 1;
BA_ "GenSigSendType" SG_ 824 HznSegRetransmission 1;
BA_ "GenSigSendType" SG_ 824 HznSegTunnel 1;
BA_ "GenSigSendType" SG_ 824 HznSegUpdate 1;
BA_ "GenSigSendType" SG_ 352 HznSplyElectcSts 0;
BA_ "GenSigSendType" SG_ 751 IndcnUnitClkFmt 0;
BA_ "GenSigSendType" SG_ 751 IndcnUnitDateFmt 0;
BA_ "GenSigSendType" SG_ 751 IndcnUnitDstLong 0;
BA_ "GenSigSendType" SG_ 751 IndcnUnitDstSho 0;
BA_ "GenSigSendType" SG_ 751 IndcnUnitFuCnsUnit 0;
BA_ "GenSigSendType" SG_ 751 IndcnUnitPUnit 0;
BA_ "GenSigSendType" SG_ 751 IndcnUnitSpdUnit 0;
BA_ "GenSigSendType" SG_ 751 IndcnUnitTUnit 0;
BA_ "GenSigSendType" SG_ 751 IndcnUnitVolUnit 0;
BA_ "GenSigSendType" SG_ 86 IntvAndWarnModForLaneKeepAidSts 0;
BA_ "GenSigSendType" SG_ 352 LaneKeepAidActvSts 0;
BA_ "GenSigSendType" SG_ 889 ListOfNodAv1 0;
BA_ "GenSigSendType" SG_ 889 ListOfNodAv2 0;
BA_ "GenSigSendType" SG_ 889 ListOfNodAv3 0;
BA_ "GenSigSendType" SG_ 889 ListOfNodAv4 0;
BA_ "GenSigSendType" SG_ 889 ListOfNodAv5 0;
BA_ "GenSigSendType" SG_ 889 ListOfNodAv6 0;
BA_ "GenSigSendType" SG_ 889 ListOfNodAv7 0;
BA_ "GenSigSendType" SG_ 889 ListOfNodAv8 0;
BA_ "GenSigSendType" SG_ 821 MirrOpenClsReq 1;
BA_ "GenSigSendType" SG_ 751 MiscTrfcSgnInfoFromNavMap 0;
BA_ "GenSigDataID" SG_ 373 MobDevRPAReq1Chks "0x1F5C";
BA_ "GenSigFuncType" SG_ 373 MobDevRPAReq1Chks 15;
BA_ "GenSigSendType" SG_ 373 MobDevRPAReq1Chks 0;
BA_ "GenSigFuncType" SG_ 373 MobDevRPAReq1Cntr 16;
BA_ "GenSigSendType" SG_ 373 MobDevRPAReq1Cntr 0;
BA_ "GenSigSendType" SG_ 373 MobDevRPAReq1MobDevSts 0;
BA_ "GenSigSendType" SG_ 373 MobDevRPAReq1RPAOutModeSubT 0;
BA_ "GenSigSendType" SG_ 373 MobDevRPAReq1RPAReq 0;
BA_ "GenSigSendType" SG_ 373 MobDevRPAReq1RSPACtrl 0;
BA_ "GenSigSendType" SG_ 488 NavForDrvrPfmncStsFromDHU 0;
BA_ "GenSigStartValue" SG_ 488 NavForDrvrPfmncStsFromDHU 1;
BA_ "GenSigSendType" SG_ 352 NavInfoSts 0;
BA_ "GenSigSendType" SG_ 832 NetDHUActvt 0;
BA_ "GenSigSendType" SG_ 352 OffsForSpdWarnSetgReq 0;
BA_ "GenSigSendType" SG_ 352 OffsForSpdWarnSetgReqSts 0;
BA_ "GenSigSendType" SG_ 373 PlannedPahDe 0;
BA_ "GenSigSendType" SG_ 775 PosnFromSatlt1Cntr 0;
BA_ "GenSigSendType" SG_ 775 PosnFromSatlt1PosnLat 0;
BA_ "GenSigStartValue" SG_ 775 PosnFromSatlt1PosnLat 323999740.8002074;
BA_ "GenSigSendType" SG_ 775 PosnFromSatlt1PosnLgt 0;
BA_ "GenSigStartValue" SG_ 775 PosnFromSatlt1PosnLgt 647999481.6004148;
BA_ "GenSigSendType" SG_ 832 PosnFromSatlt2Cntr 0;
BA_ "GenSigSendType" SG_ 832 PosnFromSatlt2PosnSpdosn 0;
BA_ "GenSigSendType" SG_ 832 PosnFromSatlt3Cntr 0;
BA_ "GenSigSendType" SG_ 832 PosnFromSatlt3PosnAlti 0;
BA_ "GenSigStartValue" SG_ 832 PosnFromSatlt3PosnAlti 1000;
BA_ "GenSigSendType" SG_ 832 PosnFromSatlt3PosnDir 0;
BA_ "GenSigStartValue" SG_ 832 PosnFromSatlt3PosnDir 100;
BA_ "GenSigSendType" SG_ 832 PosnFromSatlt3TiForMins 0;
BA_ "GenSigSendType" SG_ 832 PosnFromSatlt3TiForMsec 0;
BA_ "GenSigSendType" SG_ 832 PosnFromSatlt3TiForSec 0;
BA_ "GenSigSendType" SG_ 352 PosnFromSatltCntr 0;
BA_ "GenSigSendType" SG_ 352 PosnFromSatltPosnAlti 0;
BA_ "GenSigStartValue" SG_ 352 PosnFromSatltPosnAlti 1000;
BA_ "GenSigSendType" SG_ 352 PosnFromSatltPosnDir 0;
BA_ "GenSigSendType" SG_ 352 PosnFromSatltPosnLat 0;
BA_ "GenSigStartValue" SG_ 352 PosnFromSatltPosnLat 323999740.8002074;
BA_ "GenSigSendType" SG_ 352 PosnFromSatltPosnLgt 0;
BA_ "GenSigStartValue" SG_ 352 PosnFromSatltPosnLgt 647999481.6004148;
BA_ "GenSigSendType" SG_ 352 PosnFromSatltPosnSpd 0;
BA_ "GenSigSendType" SG_ 352 PosnFromSatltPosnVHozl 0;
BA_ "GenSigSendType" SG_ 352 PosnFromSatltPosnVVert 0;
BA_ "GenSigSendType" SG_ 352 PosnFromSatltTiForMins 0;
BA_ "GenSigSendType" SG_ 352 PosnFromSatltTiForMsec 0;
BA_ "GenSigSendType" SG_ 352 PosnFromSatltTiForSec 0;
BA_ "GenSigSendType" SG_ 352 PosnFromSatltUTCForDay 0;
BA_ "GenSigStartValue" SG_ 352 PosnFromSatltUTCForDay 1;
BA_ "GenSigSendType" SG_ 352 PosnFromSatltUTCForHr 0;
BA_ "GenSigSendType" SG_ 352 PosnFromSatltUTCForMins 0;
BA_ "GenSigSendType" SG_ 352 PosnFromSatltUTCForMth 0;
BA_ "GenSigStartValue" SG_ 352 PosnFromSatltUTCForMth 1;
BA_ "GenSigSendType" SG_ 352 PosnFromSatltUTCForSec 0;
BA_ "GenSigSendType" SG_ 352 PosnFromSatltUTCForYr 0;
BA_ "GenSigSendType" SG_ 274 PrkgAccrOvrdnCtrlReqgrpChks 0;
BA_ "GenSigSendType" SG_ 274 PrkgAccrOvrdnCtrlReqgrpCntr 0;
BA_ "GenSigSendType" SG_ 274 PrkgAccrOvrdnCtrlReqgrpPrkgAccrOvrdnCtrlReq 0;
BA_ "GenSigSendType" SG_ 96 PrkgAsscSysEcuTyp 0;
BA_ "GenSigDataID" SG_ 96 PrkgAssiElectcStabyProgCtrlModReqGroupChks "0x1C7";
BA_ "GenSigFuncType" SG_ 96 PrkgAssiElectcStabyProgCtrlModReqGroupChks 15;
BA_ "GenSigSendType" SG_ 96 PrkgAssiElectcStabyProgCtrlModReqGroupChks 0;
BA_ "SigGroup" SG_ 96 PrkgAssiElectcStabyProgCtrlModReqGroupChks "PrkgAssiElectcStabyProgCtrlModReqGroup";
BA_ "GenSigFuncType" SG_ 96 PrkgAssiElectcStabyProgCtrlModReqGroupCntr 16;
BA_ "GenSigSendType" SG_ 96 PrkgAssiElectcStabyProgCtrlModReqGroupCntr 0;
BA_ "SigGroup" SG_ 96 PrkgAssiElectcStabyProgCtrlModReqGroupCntr "PrkgAssiElectcStabyProgCtrlModReqGroup";
BA_ "GenSigSendType" SG_ 96 PrkgAssiElectcStabyProgCtrlModReqGroupPASElectcStabyProgCtrlModReq 0;
BA_ "SigGroup" SG_ 96 PrkgAssiElectcStabyProgCtrlModReqGroupPASElectcStabyProgCtrlModReq "PrkgAssiElectcStabyProgCtrlModReqGroup";
BA_ "GenSigSendType" SG_ 96 PrkgAssiSysRemPrkgSts 0;
BA_ "GenSigDataID" SG_ 274 PrkgBrkElectcCtrlReqChks "0x22B";
BA_ "GenSigFuncType" SG_ 274 PrkgBrkElectcCtrlReqChks 15;
BA_ "GenSigSendType" SG_ 274 PrkgBrkElectcCtrlReqChks 0;
BA_ "GenSigFuncType" SG_ 274 PrkgBrkElectcCtrlReqCntr 16;
BA_ "GenSigSendType" SG_ 274 PrkgBrkElectcCtrlReqCntr 0;
BA_ "GenSigSendType" SG_ 274 PrkgBrkElectcCtrlReqReq 0;
BA_ "GenSigSendType" SG_ 96 PrkgEmgyBrkEmgyBrkReq 0;
BA_ "GenSigSendType" SG_ 96 PrkgEmgyBrkEpbApplyReq 0;
BA_ "GenSigSendType" SG_ 96 PrkgEmgyBrkStandStillReq 0;
BA_ "GenSigSendType" SG_ 274 PrkgEmgyBrkSysSts 0;
BA_ "GenSigSendType" SG_ 784 PrkgFctVMMModReq 0;
BA_ "GenSigSendType" SG_ 587 PrkgImgDispReq 0;
BA_ "GenSigSendType" SG_ 274 PrkgLockReq 0;
BA_ "GenSigDataID" SG_ 96 PrkgSpdCtrlSafeGroupChks "0x3C";
BA_ "GenSigFuncType" SG_ 96 PrkgSpdCtrlSafeGroupChks 15;
BA_ "GenSigSendType" SG_ 96 PrkgSpdCtrlSafeGroupChks 0;
BA_ "GenSigFuncType" SG_ 96 PrkgSpdCtrlSafeGroupCntr 16;
BA_ "GenSigSendType" SG_ 96 PrkgSpdCtrlSafeGroupCntr 0;
BA_ "GenSigSendType" SG_ 96 PrkgSpdCtrlSafeGroupDrvrAsscSysBrkFctMod 0;
BA_ "GenSigSendType" SG_ 96 PrkgSpdCtrlSafeGroupPrkgAssiALowrLim 0;
BA_ "GenSigStartValue" SG_ 96 PrkgSpdCtrlSafeGroupPrkgAssiALowrLim 128;
BA_ "GenSigSendType" SG_ 96 PrkgSpdCtrlSafeGroupPrkgAssiALowrSlop 0;
BA_ "GenSigStartValue" SG_ 96 PrkgSpdCtrlSafeGroupPrkgAssiALowrSlop 124;
BA_ "GenSigSendType" SG_ 96 PrkgSpdCtrlSafeGroupPrkgAssiAReq1 0;
BA_ "GenSigStartValue" SG_ 96 PrkgSpdCtrlSafeGroupPrkgAssiAReq1 128;
BA_ "GenSigSendType" SG_ 96 PrkgSpdCtrlSafeGroupPrkgAssiAUpprLim 0;
BA_ "GenSigStartValue" SG_ 96 PrkgSpdCtrlSafeGroupPrkgAssiAUpprLim 128;
BA_ "GenSigSendType" SG_ 96 PrkgSpdCtrlSafeGroupPrkgAssiAUpprSlop 0;
BA_ "GenSigStartValue" SG_ 96 PrkgSpdCtrlSafeGroupPrkgAssiAUpprSlop 3;
BA_ "GenSigDataID" SG_ 274 PrkgStandstillReqChks "0x1C3";
BA_ "GenSigFuncType" SG_ 274 PrkgStandstillReqChks 15;
BA_ "GenSigSendType" SG_ 274 PrkgStandstillReqChks 0;
BA_ "GenSigFuncType" SG_ 274 PrkgStandstillReqCntr 16;
BA_ "GenSigSendType" SG_ 274 PrkgStandstillReqCntr 0;
BA_ "GenSigSendType" SG_ 274 PrkgStandstillReqReqSts1 0;
BA_ "GenSigSendType" SG_ 528 PrkgStsToEDRAPATo 0;
BA_ "GenSigSendType" SG_ 528 PrkgStsToEDRHPATo 0;
BA_ "GenSigSendType" SG_ 528 PrkgStsToEDRLSDAandTBATo 0;
BA_ "GenSigSendType" SG_ 528 PrkgStsToEDRRPATo 0;
BA_ "GenSigSendType" SG_ 528 PrkgStsToEDRreserved1 0;
BA_ "GenSigSendType" SG_ 528 PrkgStsToEDRreserved2 0;
BA_ "GenSigSendType" SG_ 528 PrkgStsToEDRreserved3 0;
BA_ "GenSigSendType" SG_ 96 PrkgUsgDrvModTranReq 0;
BA_ "GenSigSendType" SG_ 504 ProfPenSts1 0;
BA_ "GenSigSendType" SG_ 504 PtDrvrSetg 0;
BA_ "GenSigSendType" SG_ 352 RCWSwOnOff 0;
BA_ "GenSigSendType" SG_ 352 RampInfoDstToRamp 0;
BA_ "GenSigSendType" SG_ 352 RampInfoEnterRamp 0;
BA_ "GenSigSendType" SG_ 488 RemCtrlVehSts 0;
BA_ "GenSigSendType" SG_ 352 RoadMiscSgnInfoForRoadSgnInfoSts 0;
BA_ "GenSigSendType" SG_ 352 RoadSgnInfoActvSts 0;
BA_ "GenSigSendType" SG_ 775 ScenarioMod 0;
BA_ "GenSigSendType" SG_ 86 SetLimReq 0;
BA_ "GenSigStartValue" SG_ 86 SetLimReq 1;
BA_ "GenSigSendType" SG_ 373 SetSpdForCrsCtrlFct 0;
BA_ "GenSigSendType" SG_ 504 SftySigGroupFromHmiSafe1SftyHmiDend 0;
BA_ "GenSigSendType" SG_ 504 SftySigGroupFromHmiSafe1SftyHmiEna 0;
BA_ "GenSigSendType" SG_ 504 SftySigGroupFromHmiSafe1SftySigFaildDetdByHmi 0;
BA_ "GenSigDataID" SG_ 504 SftySigGroupFromHmiSafe1SftySigGroupFromHmiSafeChks "0x1C";
BA_ "GenSigFuncType" SG_ 504 SftySigGroupFromHmiSafe1SftySigGroupFromHmiSafeChks 15;
BA_ "GenSigSendType" SG_ 504 SftySigGroupFromHmiSafe1SftySigGroupFromHmiSafeChks 0;
BA_ "GenSigFuncType" SG_ 504 SftySigGroupFromHmiSafe1SftySigGroupFromHmiSafeCntr 16;
BA_ "GenSigSendType" SG_ 504 SftySigGroupFromHmiSafe1SftySigGroupFromHmiSafeCntr 0;
BA_ "GenSigSendType" SG_ 352 SmtSteerAssidSwtReq 0;
BA_ "GenSigSendType" SG_ 504 SnsrDrvrPfmncStsFromDHU 0;
BA_ "GenSigStartValue" SG_ 504 SnsrDrvrPfmncStsFromDHU 1;
BA_ "GenSigSendType" SG_ 352 SpdAlrmActvForRoadSgnInfoSts 0;
BA_ "GenSigSendType" SG_ 373 SpdCamFromNavMap 0;
BA_ "GenSigSendType" SG_ 373 SpdLimOfRoad 0;
BA_ "GenSigSendType" SG_ 86 SpdLimdSts 0;
BA_ "GenSigSendType" SG_ 775 SpplTrfcSgnInfoFromNavMap 0;
BA_ "GenSigSendType" SG_ 337 TripResetSyncMsgAuthenticator 1;
BA_ "GenSigSendType" SG_ 337 TripResetSyncMsgResetcounter 1;
BA_ "GenSigStartValue" SG_ 337 TripResetSyncMsgResetcounter 1;
BA_ "GenSigSendType" SG_ 337 TripResetSyncMsgTripcounter 1;
BA_ "GenSigStartValue" SG_ 337 TripResetSyncMsgTripcounter 1;
BA_ "GenSigSendType" SG_ 352 TrlrModSwtReq 0;
BA_ "GenSigSendType" SG_ 86 VBFsetg 0;
BA_ "GenSigStartValue" SG_ 86 VBFsetg 1;
BA_ "GenSigSendType" SG_ 1384 VFCVectorBCMBlockID 0;
BA_ "GenSigSendType" SG_ 1384 VFCVectorBCMVFCid0 0;
BA_ "GenSigSendType" SG_ 1384 VFCVectorBCMVFCid1 0;
BA_ "GenSigSendType" SG_ 1384 VFCVectorBCMVFCid10 0;
BA_ "GenSigSendType" SG_ 1384 VFCVectorBCMVFCid11 0;
BA_ "GenSigSendType" SG_ 1384 VFCVectorBCMVFCid12 0;
BA_ "GenSigSendType" SG_ 1384 VFCVectorBCMVFCid13 0;
BA_ "GenSigSendType" SG_ 1384 VFCVectorBCMVFCid14 0;
BA_ "GenSigSendType" SG_ 1384 VFCVectorBCMVFCid15 0;
BA_ "GenSigSendType" SG_ 1384 VFCVectorBCMVFCid16 0;
BA_ "GenSigSendType" SG_ 1384 VFCVectorBCMVFCid17 0;
BA_ "GenSigSendType" SG_ 1384 VFCVectorBCMVFCid18 0;
BA_ "GenSigSendType" SG_ 1384 VFCVectorBCMVFCid19 0;
BA_ "GenSigSendType" SG_ 1384 VFCVectorBCMVFCid2 0;
BA_ "GenSigSendType" SG_ 1384 VFCVectorBCMVFCid20 0;
BA_ "GenSigSendType" SG_ 1384 VFCVectorBCMVFCid21 0;
BA_ "GenSigSendType" SG_ 1384 VFCVectorBCMVFCid22 0;
BA_ "GenSigSendType" SG_ 1384 VFCVectorBCMVFCid23 0;
BA_ "GenSigSendType" SG_ 1384 VFCVectorBCMVFCid24 0;
BA_ "GenSigSendType" SG_ 1384 VFCVectorBCMVFCid25 0;
BA_ "GenSigSendType" SG_ 1384 VFCVectorBCMVFCid26 0;
BA_ "GenSigSendType" SG_ 1384 VFCVectorBCMVFCid27 0;
BA_ "GenSigSendType" SG_ 1384 VFCVectorBCMVFCid28 0;
BA_ "GenSigSendType" SG_ 1384 VFCVectorBCMVFCid29 0;
BA_ "GenSigSendType" SG_ 1384 VFCVectorBCMVFCid3 0;
BA_ "GenSigSendType" SG_ 1384 VFCVectorBCMVFCid30 0;
BA_ "GenSigSendType" SG_ 1384 VFCVectorBCMVFCid31 0;
BA_ "GenSigSendType" SG_ 1384 VFCVectorBCMVFCid32 0;
BA_ "GenSigSendType" SG_ 1384 VFCVectorBCMVFCid33 0;
BA_ "GenSigSendType" SG_ 1384 VFCVectorBCMVFCid34 0;
BA_ "GenSigSendType" SG_ 1384 VFCVectorBCMVFCid35 0;
BA_ "GenSigSendType" SG_ 1384 VFCVectorBCMVFCid36 0;
BA_ "GenSigSendType" SG_ 1384 VFCVectorBCMVFCid37 0;
BA_ "GenSigSendType" SG_ 1384 VFCVectorBCMVFCid38 0;
BA_ "GenSigSendType" SG_ 1384 VFCVectorBCMVFCid39 0;
BA_ "GenSigSendType" SG_ 1384 VFCVectorBCMVFCid4 0;
BA_ "GenSigSendType" SG_ 1384 VFCVectorBCMVFCid40 0;
BA_ "GenSigSendType" SG_ 1384 VFCVectorBCMVFCid41 0;
BA_ "GenSigSendType" SG_ 1384 VFCVectorBCMVFCid42 0;
BA_ "GenSigSendType" SG_ 1384 VFCVectorBCMVFCid43 0;
BA_ "GenSigSendType" SG_ 1384 VFCVectorBCMVFCid44 0;
BA_ "GenSigSendType" SG_ 1384 VFCVectorBCMVFCid45 0;
BA_ "GenSigSendType" SG_ 1384 VFCVectorBCMVFCid46 0;
BA_ "GenSigSendType" SG_ 1384 VFCVectorBCMVFCid47 0;
BA_ "GenSigSendType" SG_ 1384 VFCVectorBCMVFCid48 0;
BA_ "GenSigSendType" SG_ 1384 VFCVectorBCMVFCid49 0;
BA_ "GenSigSendType" SG_ 1384 VFCVectorBCMVFCid5 0;
BA_ "GenSigSendType" SG_ 1384 VFCVectorBCMVFCid50 0;
BA_ "GenSigSendType" SG_ 1384 VFCVectorBCMVFCid51 0;
BA_ "GenSigSendType" SG_ 1384 VFCVectorBCMVFCid52 0;
BA_ "GenSigSendType" SG_ 1384 VFCVectorBCMVFCid53 0;
BA_ "GenSigSendType" SG_ 1384 VFCVectorBCMVFCid54 0;
BA_ "GenSigSendType" SG_ 1384 VFCVectorBCMVFCid55 0;
BA_ "GenSigSendType" SG_ 1384 VFCVectorBCMVFCid56 0;
BA_ "GenSigSendType" SG_ 1384 VFCVectorBCMVFCid57 0;
BA_ "GenSigSendType" SG_ 1384 VFCVectorBCMVFCid58 0;
BA_ "GenSigSendType" SG_ 1384 VFCVectorBCMVFCid59 0;
BA_ "GenSigSendType" SG_ 1384 VFCVectorBCMVFCid6 0;
BA_ "GenSigSendType" SG_ 1384 VFCVectorBCMVFCid60 0;
BA_ "GenSigSendType" SG_ 1384 VFCVectorBCMVFCid61 0;
BA_ "GenSigSendType" SG_ 1384 VFCVectorBCMVFCid7 0;
BA_ "GenSigSendType" SG_ 1384 VFCVectorBCMVFCid8 0;
BA_ "GenSigSendType" SG_ 1384 VFCVectorBCMVFCid9 0;
BA_ "GenSigSendType" SG_ 1073 VFCVectorSODLBlockID 0;
BA_ "GenSigSendType" SG_ 1073 VFCVectorSODLVFCid0 0;
BA_ "GenSigSendType" SG_ 1073 VFCVectorSODLVFCid1 0;
BA_ "GenSigSendType" SG_ 1073 VFCVectorSODLVFCid10 0;
BA_ "GenSigSendType" SG_ 1073 VFCVectorSODLVFCid11 0;
BA_ "GenSigSendType" SG_ 1073 VFCVectorSODLVFCid12 0;
BA_ "GenSigSendType" SG_ 1073 VFCVectorSODLVFCid13 0;
BA_ "GenSigSendType" SG_ 1073 VFCVectorSODLVFCid14 0;
BA_ "GenSigSendType" SG_ 1073 VFCVectorSODLVFCid15 0;
BA_ "GenSigSendType" SG_ 1073 VFCVectorSODLVFCid16 0;
BA_ "GenSigSendType" SG_ 1073 VFCVectorSODLVFCid17 0;
BA_ "GenSigSendType" SG_ 1073 VFCVectorSODLVFCid18 0;
BA_ "GenSigSendType" SG_ 1073 VFCVectorSODLVFCid19 0;
BA_ "GenSigSendType" SG_ 1073 VFCVectorSODLVFCid2 0;
BA_ "GenSigSendType" SG_ 1073 VFCVectorSODLVFCid20 0;
BA_ "GenSigSendType" SG_ 1073 VFCVectorSODLVFCid21 0;
BA_ "GenSigSendType" SG_ 1073 VFCVectorSODLVFCid22 0;
BA_ "GenSigSendType" SG_ 1073 VFCVectorSODLVFCid23 0;
BA_ "GenSigSendType" SG_ 1073 VFCVectorSODLVFCid24 0;
BA_ "GenSigSendType" SG_ 1073 VFCVectorSODLVFCid25 0;
BA_ "GenSigSendType" SG_ 1073 VFCVectorSODLVFCid26 0;
BA_ "GenSigSendType" SG_ 1073 VFCVectorSODLVFCid27 0;
BA_ "GenSigSendType" SG_ 1073 VFCVectorSODLVFCid28 0;
BA_ "GenSigSendType" SG_ 1073 VFCVectorSODLVFCid29 0;
BA_ "GenSigSendType" SG_ 1073 VFCVectorSODLVFCid3 0;
BA_ "GenSigSendType" SG_ 1073 VFCVectorSODLVFCid30 0;
BA_ "GenSigSendType" SG_ 1073 VFCVectorSODLVFCid31 0;
BA_ "GenSigSendType" SG_ 1073 VFCVectorSODLVFCid32 0;
BA_ "GenSigSendType" SG_ 1073 VFCVectorSODLVFCid33 0;
BA_ "GenSigSendType" SG_ 1073 VFCVectorSODLVFCid34 0;
BA_ "GenSigSendType" SG_ 1073 VFCVectorSODLVFCid35 0;
BA_ "GenSigSendType" SG_ 1073 VFCVectorSODLVFCid36 0;
BA_ "GenSigSendType" SG_ 1073 VFCVectorSODLVFCid37 0;
BA_ "GenSigSendType" SG_ 1073 VFCVectorSODLVFCid38 0;
BA_ "GenSigSendType" SG_ 1073 VFCVectorSODLVFCid39 0;
BA_ "GenSigSendType" SG_ 1073 VFCVectorSODLVFCid4 0;
BA_ "GenSigSendType" SG_ 1073 VFCVectorSODLVFCid40 0;
BA_ "GenSigSendType" SG_ 1073 VFCVectorSODLVFCid41 0;
BA_ "GenSigSendType" SG_ 1073 VFCVectorSODLVFCid42 0;
BA_ "GenSigSendType" SG_ 1073 VFCVectorSODLVFCid43 0;
BA_ "GenSigSendType" SG_ 1073 VFCVectorSODLVFCid44 0;
BA_ "GenSigSendType" SG_ 1073 VFCVectorSODLVFCid45 0;
BA_ "GenSigSendType" SG_ 1073 VFCVectorSODLVFCid46 0;
BA_ "GenSigSendType" SG_ 1073 VFCVectorSODLVFCid47 0;
BA_ "GenSigSendType" SG_ 1073 VFCVectorSODLVFCid48 0;
BA_ "GenSigSendType" SG_ 1073 VFCVectorSODLVFCid49 0;
BA_ "GenSigSendType" SG_ 1073 VFCVectorSODLVFCid5 0;
BA_ "GenSigSendType" SG_ 1073 VFCVectorSODLVFCid50 0;
BA_ "GenSigSendType" SG_ 1073 VFCVectorSODLVFCid51 0;
BA_ "GenSigSendType" SG_ 1073 VFCVectorSODLVFCid52 0;
BA_ "GenSigSendType" SG_ 1073 VFCVectorSODLVFCid53 0;
BA_ "GenSigSendType" SG_ 1073 VFCVectorSODLVFCid54 0;
BA_ "GenSigSendType" SG_ 1073 VFCVectorSODLVFCid55 0;
BA_ "GenSigSendType" SG_ 1073 VFCVectorSODLVFCid56 0;
BA_ "GenSigSendType" SG_ 1073 VFCVectorSODLVFCid57 0;
BA_ "GenSigSendType" SG_ 1073 VFCVectorSODLVFCid58 0;
BA_ "GenSigSendType" SG_ 1073 VFCVectorSODLVFCid59 0;
BA_ "GenSigSendType" SG_ 1073 VFCVectorSODLVFCid6 0;
BA_ "GenSigSendType" SG_ 1073 VFCVectorSODLVFCid60 0;
BA_ "GenSigSendType" SG_ 1073 VFCVectorSODLVFCid61 0;
BA_ "GenSigSendType" SG_ 1073 VFCVectorSODLVFCid7 0;
BA_ "GenSigSendType" SG_ 1073 VFCVectorSODLVFCid8 0;
BA_ "GenSigSendType" SG_ 1073 VFCVectorSODLVFCid9 0;
BA_ "GenSigSendType" SG_ 96 VehBeamLoModReq 0;
BA_ "GenSigSendType" SG_ 274 VehBeamLoModReq1 0;
BA_ "GenSigSendType" SG_ 373 VehCfgPrmBlkIDBytePosn1 1;
BA_ "GenSigSendType" SG_ 373 VehCfgPrmCCPBytePosn2 1;
BA_ "GenSigSendType" SG_ 373 VehCfgPrmCCPBytePosn3 1;
BA_ "GenSigSendType" SG_ 373 VehCfgPrmCCPBytePosn4 1;
BA_ "GenSigSendType" SG_ 373 VehCfgPrmCCPBytePosn5 1;
BA_ "GenSigSendType" SG_ 373 VehCfgPrmCCPBytePosn6 1;
BA_ "GenSigSendType" SG_ 373 VehCfgPrmCCPBytePosn7 1;
BA_ "GenSigSendType" SG_ 373 VehCfgPrmCCPBytePosn8 1;
BA_ "GenSigSendType" SG_ 501 VehCfgPrmExtBlkIDBytePosn1 1;
BA_ "GenSigSendType" SG_ 501 VehCfgPrmExtCCPBytePosn2 1;
BA_ "GenSigSendType" SG_ 501 VehCfgPrmExtCCPBytePosn3 1;
BA_ "GenSigSendType" SG_ 501 VehCfgPrmExtCCPBytePosn4 1;
BA_ "GenSigSendType" SG_ 501 VehCfgPrmExtCCPBytePosn5 1;
BA_ "GenSigSendType" SG_ 501 VehCfgPrmExtCCPBytePosn6 1;
BA_ "GenSigSendType" SG_ 501 VehCfgPrmExtCCPBytePosn7 1;
BA_ "GenSigSendType" SG_ 501 VehCfgPrmExtCCPBytePosn8 1;
BA_ "GenSigSendType" SG_ 504 VehDecelCtrlSetg 0;
BA_ "GenSigSendType" SG_ 528 VehPrkgLockTheftReq 0;
BA_ "GenSigSendType" SG_ 96 VehPrkgToHorn 0;
BA_ "GenSigSendType" SG_ 352 VehSpdIndcdQly 0;
BA_ "GenSigSendType" SG_ 352 VehSpdIndcdVeSpdIndcdUnit 0;
BA_ "GenSigSendType" SG_ 352 VehSpdIndcdVehSpdIndcd 0;
BA_ "GenSigSendType" SG_ 528 VehWinSunRoofClsReq 0;
BA_ "GenSigSendType" SG_ 501 VinBlockNr 1;
BA_ "GenSigSendType" SG_ 501 VinVINSignalPos1 1;
BA_ "GenSigSendType" SG_ 501 VinVINSignalPos2 1;
BA_ "GenSigSendType" SG_ 501 VinVINSignalPos3 1;
BA_ "GenSigSendType" SG_ 501 VinVINSignalPos4 1;
BA_ "GenSigSendType" SG_ 501 VinVINSignalPos5 1;
BA_ "GenSigSendType" SG_ 501 VinVINSignalPos6 1;
BA_ "GenSigSendType" SG_ 501 VinVINSignalPos7 1;
BA_ "GenSigSendType" SG_ 373 VoiceBrstMod 0;
BA_ "GenSigSendType" SG_ 274 VoiceKeyPrkgSts 0;
BA_ "GenSigSendType" SG_ 775 VstdModeSts 0;
BA_ "GenSigSendType" SG_ 1320 WakeUpReasonsforBCM 0;
BA_ "GenSigSendType" SG_ 1289 WakeUpReasonsforDHU 0;
BA_ "GenSigSendType" SG_ 352 WarnTypForLaneKeepAidSts 0;
BA_ "GenSigSendType" SG_ 373 WhlCircum 0;
VAL_ 1384 VFCVectorBCMVFCid0 0 "VFCOnOff_Off" 1 "VFCOnOff_On";
VAL_ 1384 VFCVectorBCMVFCid1 0 "VFCOnOff_Off" 1 "VFCOnOff_On";
VAL_ 1384 VFCVectorBCMVFCid10 0 "VFCOnOff_Off" 1 "VFCOnOff_On";
VAL_ 1384 VFCVectorBCMVFCid11 0 "VFCOnOff_Off" 1 "VFCOnOff_On";
VAL_ 1384 VFCVectorBCMVFCid12 0 "VFCOnOff_Off" 1 "VFCOnOff_On";
VAL_ 1384 VFCVectorBCMVFCid13 0 "VFCOnOff_Off" 1 "VFCOnOff_On";
VAL_ 1384 VFCVectorBCMVFCid14 0 "VFCOnOff_Off" 1 "VFCOnOff_On";
VAL_ 1384 VFCVectorBCMVFCid15 0 "VFCOnOff_Off" 1 "VFCOnOff_On";
VAL_ 1384 VFCVectorBCMVFCid16 0 "VFCOnOff_Off" 1 "VFCOnOff_On";
VAL_ 1384 VFCVectorBCMVFCid17 0 "VFCOnOff_Off" 1 "VFCOnOff_On";
VAL_ 1384 VFCVectorBCMVFCid18 0 "VFCOnOff_Off" 1 "VFCOnOff_On";
VAL_ 1384 VFCVectorBCMVFCid19 0 "VFCOnOff_Off" 1 "VFCOnOff_On";
VAL_ 1384 VFCVectorBCMVFCid2 0 "VFCOnOff_Off" 1 "VFCOnOff_On";
VAL_ 1384 VFCVectorBCMVFCid20 0 "VFCOnOff_Off" 1 "VFCOnOff_On";
VAL_ 1384 VFCVectorBCMVFCid21 0 "VFCOnOff_Off" 1 "VFCOnOff_On";
VAL_ 1384 VFCVectorBCMVFCid22 0 "VFCOnOff_Off" 1 "VFCOnOff_On";
VAL_ 1384 VFCVectorBCMVFCid23 0 "VFCOnOff_Off" 1 "VFCOnOff_On";
VAL_ 1384 VFCVectorBCMVFCid24 0 "VFCOnOff_Off" 1 "VFCOnOff_On";
VAL_ 1384 VFCVectorBCMVFCid25 0 "VFCOnOff_Off" 1 "VFCOnOff_On";
VAL_ 1384 VFCVectorBCMVFCid26 0 "VFCOnOff_Off" 1 "VFCOnOff_On";
VAL_ 1384 VFCVectorBCMVFCid27 0 "VFCOnOff_Off" 1 "VFCOnOff_On";
VAL_ 1384 VFCVectorBCMVFCid28 0 "VFCOnOff_Off" 1 "VFCOnOff_On";
VAL_ 1384 VFCVectorBCMVFCid29 0 "VFCOnOff_Off" 1 "VFCOnOff_On";
VAL_ 1384 VFCVectorBCMVFCid3 0 "VFCOnOff_Off" 1 "VFCOnOff_On";
VAL_ 1384 VFCVectorBCMVFCid30 0 "VFCOnOff_Off" 1 "VFCOnOff_On";
VAL_ 1384 VFCVectorBCMVFCid31 0 "VFCOnOff_Off" 1 "VFCOnOff_On";
VAL_ 1384 VFCVectorBCMVFCid32 0 "VFCOnOff_Off" 1 "VFCOnOff_On";
VAL_ 1384 VFCVectorBCMVFCid33 0 "VFCOnOff_Off" 1 "VFCOnOff_On";
VAL_ 1384 VFCVectorBCMVFCid34 0 "VFCOnOff_Off" 1 "VFCOnOff_On";
VAL_ 1384 VFCVectorBCMVFCid35 0 "VFCOnOff_Off" 1 "VFCOnOff_On";
VAL_ 1384 VFCVectorBCMVFCid36 0 "VFCOnOff_Off" 1 "VFCOnOff_On";
VAL_ 1384 VFCVectorBCMVFCid37 0 "VFCOnOff_Off" 1 "VFCOnOff_On";
VAL_ 1384 VFCVectorBCMVFCid38 0 "VFCOnOff_Off" 1 "VFCOnOff_On";
VAL_ 1384 VFCVectorBCMVFCid39 0 "VFCOnOff_Off" 1 "VFCOnOff_On";
VAL_ 1384 VFCVectorBCMVFCid4 0 "VFCOnOff_Off" 1 "VFCOnOff_On";
VAL_ 1384 VFCVectorBCMVFCid40 0 "VFCOnOff_Off" 1 "VFCOnOff_On";
VAL_ 1384 VFCVectorBCMVFCid41 0 "VFCOnOff_Off" 1 "VFCOnOff_On";
VAL_ 1384 VFCVectorBCMVFCid42 0 "VFCOnOff_Off" 1 "VFCOnOff_On";
VAL_ 1384 VFCVectorBCMVFCid43 0 "VFCOnOff_Off" 1 "VFCOnOff_On";
VAL_ 1384 VFCVectorBCMVFCid44 0 "VFCOnOff_Off" 1 "VFCOnOff_On";
VAL_ 1384 VFCVectorBCMVFCid45 0 "VFCOnOff_Off" 1 "VFCOnOff_On";
VAL_ 1384 VFCVectorBCMVFCid46 0 "VFCOnOff_Off" 1 "VFCOnOff_On";
VAL_ 1384 VFCVectorBCMVFCid47 0 "VFCOnOff_Off" 1 "VFCOnOff_On";
VAL_ 1384 VFCVectorBCMVFCid48 0 "VFCOnOff_Off" 1 "VFCOnOff_On";
VAL_ 1384 VFCVectorBCMVFCid49 0 "VFCOnOff_Off" 1 "VFCOnOff_On";
VAL_ 1384 VFCVectorBCMVFCid5 0 "VFCOnOff_Off" 1 "VFCOnOff_On";
VAL_ 1384 VFCVectorBCMVFCid50 0 "VFCOnOff_Off" 1 "VFCOnOff_On";
VAL_ 1384 VFCVectorBCMVFCid51 0 "VFCOnOff_Off" 1 "VFCOnOff_On";
VAL_ 1384 VFCVectorBCMVFCid52 0 "VFCOnOff_Off" 1 "VFCOnOff_On";
VAL_ 1384 VFCVectorBCMVFCid53 0 "VFCOnOff_Off" 1 "VFCOnOff_On";
VAL_ 1384 VFCVectorBCMVFCid54 0 "VFCOnOff_Off" 1 "VFCOnOff_On";
VAL_ 1384 VFCVectorBCMVFCid55 0 "VFCOnOff_Off" 1 "VFCOnOff_On";
VAL_ 1384 VFCVectorBCMVFCid56 0 "VFCOnOff_Off" 1 "VFCOnOff_On";
VAL_ 1384 VFCVectorBCMVFCid57 0 "VFCOnOff_Off" 1 "VFCOnOff_On";
VAL_ 1384 VFCVectorBCMVFCid58 0 "VFCOnOff_Off" 1 "VFCOnOff_On";
VAL_ 1384 VFCVectorBCMVFCid59 0 "VFCOnOff_Off" 1 "VFCOnOff_On";
VAL_ 1384 VFCVectorBCMVFCid6 0 "VFCOnOff_Off" 1 "VFCOnOff_On";
VAL_ 1384 VFCVectorBCMVFCid60 0 "VFCOnOff_Off" 1 "VFCOnOff_On";
VAL_ 1384 VFCVectorBCMVFCid61 0 "VFCOnOff_Off" 1 "VFCOnOff_On";
VAL_ 1384 VFCVectorBCMVFCid7 0 "VFCOnOff_Off" 1 "VFCOnOff_On";
VAL_ 1384 VFCVectorBCMVFCid8 0 "VFCOnOff_Off" 1 "VFCOnOff_On";
VAL_ 1384 VFCVectorBCMVFCid9 0 "VFCOnOff_Off" 1 "VFCOnOff_On";
VAL_ 1320 WakeUpReasonsforBCM 0 "WakeupReasons_667949" 1 "WakeupReasons_667950" 2 "WakeupReasons_169654" 3 "WakeupReasons_667951" 4 "WakeupReasons_168965" 5 "WakeupReasons_197643" 6 "WakeupReasons_264933" 7 "WakeupReasons_45654" 8 "WakeupReasons_22058" 9 "WakeupReasons_49446" 10 "WakeupReasons_22060" 11 "WakeupReasons_269740" 12 "WakeupReasons_269735" 13 "WakeupReasons_269739" 14 "WakeupReasons_658500" 15 "WakeupReasons_21901" 16 "WakeupReasons_45793" 17 "WakeupReasons_45794" 18 "WakeupReasons_22005" 19 "WakeupReasons_22013" 20 "WakeupReasons_22100" 21 "WakeupReasons_45659" 22 "WakeupReasons_45657" 23 "WakeupReasons_140084" 24 "WakeupReasons_21973" 25 "WakeupReasons_91253" 26 "WakeupReasons_88123" 27 "WakeupReasons_88125" 28 "WakeupReasons_321583" 29 "WakeupReasons_74188" 30 "WakeupReasons_667945" 31 "WakeupReasons_169655" 32 "WakeupReasons_667948" 33 "WakeupReasons_168966" 34 "WakeupReasons_170865" 35 "WakeupReasons_197642" 36 "WakeupReasons_264876" 37 "WakeupReasons_191050" 38 "WakeupReasons_182033" 39 "WakeupReasons_200937" 40 "WakeupReasons_170807" 41 "WakeupReasons_319139" 42 "WakeupReasons_100298" 43 "WakeupReasons_100275" 44 "WakeupReasons_100300" 45 "WakeupReasons_100278" 46 "WakeupReasons_100281" 47 "WakeupReasons_265333" 48 "WakeupReasons_108776" 49 "WakeupReasons_176921" 50 "WakeupReasons_197826" 51 "WakeupReasons_185670" 52 "WakeupReasons_161066" 53 "WakeupReasons_200156" 54 "WakeupReasons_225696" 55 "WakeupReasons_21997" 56 "WakeupReasons_45656" 57 "WakeupReasons_266860" 58 "WakeupReasons_169894" 59 "WakeupReasons_320282" 60 "WakeupReasons_319422" 61 "WakeupReasons_320277" 62 "WakeupReasons_355601" 63 "WakeupReasons_360904" 64 "WakeupReasons_361505" 65 "WakeupReasons_361509" 66 "WakeupReasons_645094" 67 "WakeupReasons_68676" 68 "WakeupReasons_360008" 69 "WakeupReasons_109382" 70 "WakeupReasons_119273" 71 "WakeupReasons_224065" 72 "WakeupReasons_68644" 73 "WakeupReasons_109364" 74 "WakeupReasons_68481" 75 "WakeupReasons_224061" 76 "WakeupReasons_360006" 77 "WakeupReasons_138997" 78 "WakeupReasons_634696" 79 "WakeupReasons_645810" 80 "WakeupReasons_297868" 81 "WakeupReasons_315364" 82 "WakeupReasons_109367" 83 "WakeupReasons_320126" 84 "WakeupReasons_109387" 85 "WakeupReasons_634710" 86 "WakeupReasons_338820" 87 "WakeupReasons_67182" 88 "WakeupReasons_152237" 89 "WakeupReasons_145707" 90 "WakeupReasons_199172" 91 "WakeupReasons_144897" 92 "WakeupReasons_186489" 93 "WakeupReasons_144970" 94 "WakeupReasons_152786" 95 "WakeupReasons_264932" 96 "WakeupReasons_264934" 97 "WakeupReasons_356190" 98 "WakeupReasons_145688" 99 "WakeupReasons_95444" 100 "WakeupReasons_169945" 101 "WakeupReasons_140678" 102 "WakeupReasons_222553" 103 "WakeupReasons_224831" 104 "WakeupReasons_201815" 105 "WakeupReasons_45864" 106 "WakeupReasons_659549" 107 "WakeupReasons_45866" 108 "WakeupReasons_45867" 109 "WakeupReasons_169884" 110 "WakeupReasons_264962" 111 "WakeupReasons_201348" 112 "WakeupReasons_320287" 113 "WakeupReasons_156412" 114 "WakeupReasons_133749" 115 "WakeupReasons_355409" 116 "WakeupReasons_636692" 117 "WakeupReasons_533044" 118 "WakeupReasons_106774" 119 "WakeupReasons_145311" 120 "WakeupReasons_145319" 121 "WakeupReasons_152774" 122 "WakeupReasons_145330" 123 "WakeupReasons_145388" 124 "WakeupReasons_145399" 125 "WakeupReasons_145362" 126 "WakeupReasons_145385" 127 "WakeupReasons_145373" 128 "WakeupReasons_145288" 129 "WakeupReasons_145419" 130 "WakeupReasons_145454" 131 "WakeupReasons_145462" 132 "WakeupReasons_269156" 133 "WakeupReasons_300427" 134 "WakeupReasons_220322" 135 "WakeupReasons_224617" 136 "WakeupReasons_224634" 137 "WakeupReasons_300682" 138 "WakeupReasons_264958" 139 "WakeupReasons_160597" 140 "WakeupReasons_160602" 141 "WakeupReasons_108841" 142 "WakeupReasons_265569" 143 "WakeupReasons_526429" 144 "WakeupReasons_514545" 145 "WakeupReasons_265232" 146 "WakeupReasons_644550" 147 "WakeupReasons_317616" 148 "WakeupReasons_354791" 149 "WakeupReasons_320631" 150 "WakeupReasons_337565" 151 "WakeupReasons_532007" 152 "WakeupReasons_514503" 153 "WakeupReasons_299117" 154 "WakeupReasons_340667" 155 "WakeupReasons_321845" 156 "WakeupReasons_179103" 157 "WakeupReasons_108810" 158 "WakeupReasons_322857" 159 "WakeupReasons_658603" 160 "WakeupReasons_197648" 161 "WakeupReasons_160596" 162 "WakeupReasons_361272" 163 "WakeupReasons_361279" 164 "WakeupReasons_265305" 165 "WakeupReasons_265328" 166 "WakeupReasons_265330" 167 "WakeupReasons_298808" 168 "WakeupReasons_515804" 169 "WakeupReasons_514502" 170 "WakeupReasons_645753" 171 "WakeupReasons_646109" 172 "WakeupReasons_299547" 173 "WakeupReasons_318342" 174 "WakeupReasons_360543" 175 "WakeupReasons_356549" 176 "WakeupReasons_198484" 177 "WakeupReasons_300681" 178 "WakeupReasons_359211" 179 "WakeupReasons_534077" 180 "WakeupReasons_525705" 181 "WakeupReasons_360299" 182 "WakeupReasons_526445" 183 "WakeupReasons_534145" 184 "WakeupReasons_192030" 185 "WakeupReasons_652361" 186 "WakeupReasons_355214" 187 "WakeupReasons_321317" 188 "WakeupReasons_359187" 189 "WakeupReasons_321057" 190 "WakeupReasons_321319" 191 "WakeupReasons_321323" 192 "WakeupReasons_321077" 193 "WakeupReasons_320895" 194 "WakeupReasons_655340" 195 "WakeupReasons_636556" 196 "WakeupReasons_108834" 197 "WakeupReasons_265937" 198 "WakeupReasons_533050" 199 "WakeupReasons_526426" 200 "WakeupReasons_264712" 201 "WakeupReasons_319401" 202 "WakeupReasons_643973" 203 "WakeupReasons_223715" 204 "WakeupReasons_199159" 205 "WakeupReasons_318382" 206 "WakeupReasons_226967" 207 "WakeupReasons_531743" 208 "WakeupReasons_360542" 209 "WakeupReasons_264726" 210 "WakeupReasons_535214" 211 "WakeupReasons_335068" 212 "WakeupReasons_316796" 213 "WakeupReasons_526438" 214 "WakeupReasons_198433" 215 "WakeupReasons_225961" 216 "WakeupReasons_197665" 217 "WakeupReasons_224550" 218 "WakeupReasons_667962" 219 "WakeupReasons_667953" 220 "WakeupReasons_110885" 221 "WakeupReasons_224552" 222 "WakeupReasons_224553" 223 "WakeupReasons_652546" 224 "WakeupReasons_331194" 225 "WakeupReasons_667820" 226 "WakeupReasons_659350" 227 "WakeupReasons_101706" 228 "WakeupReasons_101725" 229 "WakeupReasons_101728" 230 "WakeupReasons_101727" 231 "WakeupReasons_166267" 232 "WakeupReasons_156440" 233 "WakeupReasons_95949" 234 "WakeupReasons_112799" 235 "WakeupReasons_146470" 236 "WakeupReasons_176748" 237 "WakeupReasons_223920" 238 "WakeupReasons_668531" 239 "WakeupReasons_670087" 240 "WakeupReasons_668529" 241 "WakeupReasons_45858" 242 "WakeupReasons_315981" 243 "WakeupReasons_533370" 244 "WakeupReasons_533371" 245 "WakeupReasons_533372" 246 "WakeupReasons_241902" 247 "WakeupReasons_359559" 248 "WakeupReasons_516327" 249 "WakeupReasons_533872" 250 "WakeupReasons_45856" 251 "WakeupReasons_45853" 252 "WakeupReasons_45854" 253 "WakeupReasons_45852" 254 "WakeupReasons_45851" 255 "WakeupReasons_45850" 256 "WakeupReasons_45849" 257 "WakeupReasons_636801" 258 "WakeupReasons_109466" 259 "WakeupReasons_109467" 260 "WakeupReasons_670345" 261 "WakeupReasons_NMPDUReceived" 262 "WakeupReasons_358832" 263 "WakeupReasons_200683" 264 "WakeupReasons_198452" 265 "WakeupReasons_185457" 266 "WakeupReasons_185490" 267 "WakeupReasons_4471" 268 "WakeupReasons_269034" 269 "WakeupReasons_215560" 270 "WakeupReasons_312881" 271 "WakeupReasons_269140" 272 "WakeupReasons_197653" 273 "WakeupReasons_337991" 274 "WakeupReasons_658188" 275 "WakeupReasons_674953" 276 "WakeupReasons_675064" 277 "WakeupReasons_674958" 278 "WakeupReasons_675494" 279 "WakeupReasons_675837" 280 "WakeupReasons_667879" 281 "WakeupReasons_667947" 282 "WakeupReasons_676265" 283 "WakeupReasons_669465" 284 "WakeupReasons_670928" 285 "WakeupReasons_669447" 286 "WakeupReasons_667922" 287 "WakeupReasons_670753" 288 "WakeupReasons_668395" 289 "WakeupReasons_668393" 290 "WakeupReasons_667850" 291 "WakeupReasons_667848" 292 "WakeupReasons_311279" 293 "WakeupReasons_182918" 294 "WakeupReasons_667988" 295 "WakeupReasons_532555" 296 "WakeupReasons_532556" 297 "WakeupReasons_113348" 298 "WakeupReasons_193474" 299 "WakeupReasons_667871" 300 "WakeupReasons_670966" 301 "WakeupReasons_667985" 302 "WakeupReasons_670354" 303 "WakeupReasons_46017" 304 "WakeupReasons_675742" 305 "WakeupReasons_106669" 306 "WakeupReasons_80609" 307 "WakeupReasons_199714" 308 "WakeupReasons_200090" 309 "WakeupReasons_139075" 310 "WakeupReasons_268983" 311 "WakeupReasons_265131" 312 "WakeupReasons_263473" 313 "WakeupReasons_45887" 314 "WakeupReasons_69678" 315 "WakeupReasons_69679" 316 "WakeupReasons_45897" 317 "WakeupReasons_45898" 318 "WakeupReasons_80608" 319 "WakeupReasons_45869" 320 "WakeupReasons_45870" 321 "WakeupReasons_45872" 322 "WakeupReasons_45875" 323 "WakeupReasons_45871" 324 "WakeupReasons_45876" 325 "WakeupReasons_667980" 326 "WakeupReasons_45877" 327 "WakeupReasons_667973" 328 "WakeupReasons_670962" 329 "WakeupReasons_45888" 330 "WakeupReasons_45890" 331 "WakeupReasons_667869" 332 "WakeupReasons_45846" 333 "WakeupReasons_45847" 334 "WakeupReasons_45848" 335 "WakeupReasons_262872" 336 "WakeupReasons_127924" 337 "WakeupReasons_127926" 338 "WakeupReasons_674223" 339 "WakeupReasons_667982" 340 "WakeupReasons_657121" 341 "WakeupReasons_265745" 342 "WakeupReasons_657120" 343 "WakeupReasons_675564" 344 "WakeupReasons_197644" 345 "WakeupReasons_264943" 346 "WakeupReasons_264697" 347 "WakeupReasons_69216" 348 "WakeupReasons_128671" 349 "WakeupReasons_356598" 350 "WakeupReasons_675745" 351 "WakeupReasons_667983" 352 "WakeupReasons_667987" 353 "WakeupReasons_75103" 354 "WakeupReasons_305818" 355 "WakeupReasons_670942" 356 "WakeupReasons_532932" 357 "WakeupReasons_532933" 358 "WakeupReasons_83199" 359 "WakeupReasons_45900" 360 "WakeupReasons_88458" 361 "WakeupReasons_329457" 362 "WakeupReasons_45902" 363 "WakeupReasons_224211" 364 "WakeupReasons_667981" 365 "WakeupReasons_667874" 366 "WakeupReasons_46020" 367 "WakeupReasons_667842" 368 "WakeupReasons_145161" 369 "WakeupReasons_233755" 370 "WakeupReasons_297056" 371 "WakeupReasons_264691" 372 "WakeupReasons_262871" 373 "WakeupReasons_264964" 374 "WakeupReasons_667872" 375 "WakeupReasons_45655" 376 "WakeupReasons_177214" 377 "WakeupReasons_671005" 378 "WakeupReasons_680712" 379 "WakeupReasons_669822" 380 "WakeupReasons_668523" 381 "WakeupReasons_680974" 382 "WakeupReasons_680975" 383 "WakeupReasons_681028" 384 "WakeupReasons_670462" 385 "WakeupReasons_681134" 386 "WakeupReasons_681031" 387 "WakeupReasons_681711" 388 "WakeupReasons_682034" 389 "WakeupReasons_674839" 390 "WakeupReasons_681915" 391 "WakeupReasons_682032" 392 "WakeupReasons_682037" 393 "WakeupReasons_682688" 394 "WakeupReasons_681789" 395 "WakeupReasons_682023" 396 "WakeupReasons_681023" 397 "WakeupReasons_676285" 398 "WakeupReasons_682077" 399 "WakeupReasons_682076" 400 "WakeupReasons_682078" 401 "WakeupReasons_682153" 402 "WakeupReasons_682155" 403 "WakeupReasons_682152" 404 "WakeupReasons_682154" 405 "WakeupReasons_682074";
VAL_ 87 DrvrACCrsSetSpdReqDrvrCrsSetSpdReq 0 "DrvrCrsAModReq_Neutral" 1 "DrvrCrsAModReq_APosReqMod1" 2 "DrvrCrsAModReq_APosReqMod2" 3 "DrvrCrsAModReq_ANegReqMod1" 4 "DrvrCrsAModReq_ANegReqMod2";
VAL_ 488 AsyEmgyManoeuvreAidActvSts 0 "OnOff1_Off" 1 "OnOff1_On";
VAL_ 488 AsyNoaUpgradeswitch 0 "OnOff1_Off" 1 "OnOff1_On";
VAL_ 488 BSDSwOnOffandWarnType 0 "WarmType_Off" 1 "WarmType_Light" 2 "WarmType_LightAndAudio";
VAL_ 488 CamFltsStsFromDHU 0 "EyesOnZone1_Unavailable" 1 "EyesOnZone1_Yes" 2 "EyesOnZone1_No" 3 "EyesOnZone1_Reserved";
VAL_ 488 CllsnAidSnvtySeldSts 0 "CllsnAidSnvtySeldSts_inactive" 1 "CllsnAidSnvtySeldSts_off" 2 "CllsnAidSnvtySeldSts_on" 3 "CllsnAidSnvtySeldSts_medium" 4 "CllsnAidSnvtySeldSts_high" 5 "CllsnAidSnvtySeldSts_Reserved1" 6 "CllsnAidSnvtySeldSts_Reserved2" 7 "CllsnAidSnvtySeldSts_Reserved3";
VAL_ 488 CllsnMtgtnActvSeldSts 0 "OnOff1_Off" 1 "OnOff1_On";
VAL_ 488 CmftBrkStopSwtSts 0 "OnOff1_Off" 1 "OnOff1_On";
VAL_ 488 CrsCtrlTiGapAdjReq 0 "TiGapSetForLgtCtrl_None" 1 "TiGapSetForLgtCtrl_TimeGap_1" 2 "TiGapSetForLgtCtrl_TimeGap_2" 3 "TiGapSetForLgtCtrl_TimeGap_3";
VAL_ 488 CurrentRoadLvl 0 "CurrentRoadLvl_Unknown" 1 "CurrentRoadLvl_CityFastWay" 2 "CurrentRoadLvl_Countryway" 3 "CurrentRoadLvl_Ferryway" 4 "CurrentRoadLvl_HighWay" 5 "CurrentRoadLvl_Level9Way" 6 "CurrentRoadLvl_NationWay" 7 "CurrentRoadLvl_ProvinceWay" 8 "CurrentRoadLvl_TownWay" 9 "CurrentRoadLvl_WalkWay" 10 "CurrentRoadLvl_OtherWay";
VAL_ 488 DrvOffReq 0 "OnOff1_Off" 1 "OnOff1_On";
VAL_ 488 DrvrCrsCtrlFctActvReq 0 "DrvrCrsCtrlFctActvReq_Inactive" 1 "DrvrCrsCtrlFctActvReq_Activatedbyonoffbutton" 2 "DrvrCrsCtrlFctActvReq_Activatedbyresumebutton" 3 "DrvrCrsCtrlFctActvReq_Reserved";
VAL_ 488 DrvrDecStsFromDHU 0 "DrvrDecSts_Unavailable" 1 "DrvrDecSts_NotDetected" 2 "DrvrDecSts_EyeDetected" 3 "DrvrDecSts_HeadDetected" 4 "DrvrDecSts_Reserved";
VAL_ 488 DrvrPfmncAlrmReqFromDHU 0 "DrvrPfmncWarnReq_Unavailable" 1 "DrvrPfmncWarnReq_Unknown" 2 "DrvrPfmncWarnReq_NoWarning" 3 "DrvrPfmncWarnReq_Distractive" 4 "DrvrPfmncWarnReq_Warninglevel1" 5 "DrvrPfmncWarnReq_Warninglevel2_Navigation" 6 "DrvrPfmncWarnReq_Warninglevel2";
VAL_ 488 DrvrPfmncSwitchStsFromDHU 0 "DrvrPfmncSwtichSts_Unavailable" 1 "DrvrPfmncSwtichSts_On" 2 "DrvrPfmncSwtichSts_Off" 3 "DrvrPfmncSwtichSts_ServiceNeed" 4 "DrvrPfmncSwtichSts_Reserved1" 5 "DrvrPfmncSwtichSts_Reserved2" 6 "DrvrPfmncSwtichSts_Reserved3" 7 "DrvrPfmncSwtichSts_Reserved4";
VAL_ 488 EmgyLaneKeepAidActvSts 0 "OnOff1_Off" 1 "OnOff1_On";
VAL_ 488 EyeGazeFromDHUEyeGazeZone 0 "EyeGazeZone1_Unavilable" 1 "EyeGazeZone1_windshielddriver" 2 "EyeGazeZone1_rearmirrorinner" 3 "EyeGazeZone1_windshieldpassager" 4 "EyeGazeZone1_HUD" 5 "EyeGazeZone1_DIM" 6 "EyeGazeZone1_IHU" 7 "EyeGazeZone1_windowdriver" 8 "EyeGazeZone1_rearmirrordriver" 9 "EyeGazeZone1_doordriver" 10 "EyeGazeZone1_windowpassagner" 11 "EyeGazeZone1_rearmirrorpassanger" 12 "EyeGazeZone1_doorpassanger" 13 "EyeGazeZone1_floordriver" 14 "EyeGazeZone1_floorpassanger" 15 "EyeGazeZone1_other" 16 "EyeGazeZone1_greenzone_1_3_4" 17 "EyeGazeZone1_yellowzone_2_5_6_7_8_10_11" 18 "EyeGazeZone1_redzone_9_12_13_14" 19 "EyeGazeZone1_SteerWheelLe" 20 "EyeGazeZone1_SteerWheelRi" 21 "EyeGazeZone1_Reserved3" 22 "EyeGazeZone1_Reserved4" 23 "EyeGazeZone1_Reserved5" 24 "EyeGazeZone1_Reserved6";
VAL_ 488 EyeOnRoadFromDHUEyesOnRoad 0 "EyesOnZone1_Unavailable" 1 "EyesOnZone1_Yes" 2 "EyesOnZone1_No" 3 "EyesOnZone1_Reserved";
VAL_ 488 EyeOpenFromDHUEyeOpenLe 0 "Close" 1 "Open";
VAL_ 488 EyeOpenFromDHUEyeOpenRi 0 "Close" 1 "Open";
VAL_ 488 EyeOpenFromDHUEyeVisibleLe 0 "Invisible" 1 "Visible";
VAL_ 488 EyeOpenFromDHUEyeVisibleRi 0 "Invisible" 1 "Visible";
VAL_ 488 EyeOpenFromDHUFaceVisible 0 "Invisible" 1 "Visible";
VAL_ 488 HmiDrvrSodReqPilot 0 "OnOff1_Off" 1 "OnOff1_On";
VAL_ 488 HznPosnMessageType 0 "MessageType_SystemSpecific" 1 "MessageType_POSITION" 2 "MessageType_SEGMENT" 3 "MessageType_STUB" 4 "MessageType_PROFILESHORT" 5 "MessageType_PROFILELONG" 6 "MessageType_METADATA" 7 "MessageType_Reserved";
VAL_ 488 NavForDrvrPfmncStsFromDHU 0 "DrvrPfmncSwtichSts_Unavailable" 1 "DrvrPfmncSwtichSts_On" 2 "DrvrPfmncSwtichSts_Off" 3 "DrvrPfmncSwtichSts_ServiceNeed" 4 "DrvrPfmncSwtichSts_Reserved1" 5 "DrvrPfmncSwtichSts_Reserved2" 6 "DrvrPfmncSwtichSts_Reserved3" 7 "DrvrPfmncSwtichSts_Reserved4";
VAL_ 488 RemCtrlVehSts 0 "RemCtrlVehSts_OFF" 1 "RemCtrlVehSts_RemParkInStandby" 2 "RemCtrlVehSts_RemParkOutStandby" 3 "RemCtrlVehSts_Searching" 4 "RemCtrlVehSts_RemParkInpreactive" 5 "RemCtrlVehSts_RemParkactive" 6 "RemCtrlVehSts_ParkProcessActive" 7 "RemCtrlVehSts_Suspend" 8 "RemCtrlVehSts_Abort" 9 "RemCtrlVehSts_RemParkInProCompleted" 10 "RemCtrlVehSts_RemParkOutProCompleted" 11 "RemCtrlVehSts_RemParkCompleted" 12 "RemCtrlVehSts_Quit" 13 "RemCtrlVehSts_Failure" 14 "RemCtrlVehSts_Cancel";
VAL_ 775 FogSetReReq 0 "OnOffNoReq_NoReq" 1 "OnOffNoReq_On" 2 "OnOffNoReq_Off";
VAL_ 775 GNSSSolution1SatItSysNo1InUse 0 "NoYes1_No" 1 "NoYes1_Yes";
VAL_ 775 GNSSSolution1SatItSysNo2InUse 0 "NoYes1_No" 1 "NoYes1_Yes";
VAL_ 775 GNSSSolution1SatItSysNo3InUse 0 "NoYes1_No" 1 "NoYes1_Yes";
VAL_ 775 GNSSSolution1SatItSysNo4InUse 0 "NoYes1_No" 1 "NoYes1_Yes";
VAL_ 775 GNSSSolution1SatItSysNo5InUse 0 "NoYes1_No" 1 "NoYes1_Yes";
VAL_ 775 GNSSSolution1SatItSysNo6InUse 0 "NoYes1_No" 1 "NoYes1_Yes";
VAL_ 775 GNSSSolution1SatItSysNo7InUse 0 "NoYes1_No" 1 "NoYes1_Yes";
VAL_ 775 GNSSSolution1SatltPosnStsPrm1 0 "SatltPosnSts_PosnStsOfLvl1" 1 "SatltPosnSts_PosnStsOfLvl2" 2 "SatltPosnSts_PosnStsOfLvl3" 3 "SatltPosnSts_PosnStsOfLvl4";
VAL_ 775 GNSSSolution1SatltPosnStsPrm2 0 "Boolean_FALSE" 1 "Boolean_TRUE";
VAL_ 775 GNSSSolutionSatltPosnStsPrm1 0 "SatltPosnSts_PosnStsOfLvl1" 1 "SatltPosnSts_PosnStsOfLvl2" 2 "SatltPosnSts_PosnStsOfLvl3" 3 "SatltPosnSts_PosnStsOfLvl4";
VAL_ 775 GNSSSolutionSatltPosnStsPrm2 0 "Boolean_FALSE" 1 "Boolean_TRUE";
VAL_ 775 GNSSSolutionSatltSysNo1InUse 0 "NoYes1_No" 1 "NoYes1_Yes";
VAL_ 775 GNSSSolutionSatltSysNo2InUse 0 "NoYes1_No" 1 "NoYes1_Yes";
VAL_ 775 GNSSSolutionSatltSysNo3InUse 0 "NoYes1_No" 1 "NoYes1_Yes";
VAL_ 775 GNSSSolutionSatltSysNo4InUse 0 "NoYes1_No" 1 "NoYes1_Yes";
VAL_ 775 GNSSSolutionSatltSysNo5InUse 0 "NoYes1_No" 1 "NoYes1_Yes";
VAL_ 775 GNSSSolutionSatltSysNo6InUse 0 "NoYes1_No" 1 "NoYes1_Yes";
VAL_ 775 GNSSSolutionSatltSysNo7InUse 0 "NoYes1_No" 1 "NoYes1_Yes";
VAL_ 775 ScenarioMod 0 "SceneMod_Idle" 1 "SceneMod_ChildrenMod" 2 "SceneMod_RefreshMod" 3 "SceneMod_TheaterMod" 4 "SceneMod_RestMod" 5 "SceneMod_ConcertHallMod" 6 "SceneMod_CarWashMod" 7 "SceneMod_SmokingMod" 8 "SceneMod_RomanticMod" 9 "SceneMod_MeditationMod" 10 "SceneMod_SingMod" 11 "SceneMod_PetMod" 12 "SceneMod_Reserved1" 13 "SceneMod_Reserved2" 14 "SceneMod_Reserved3" 15 "SceneMod_Reserved4";
VAL_ 775 SpplTrfcSgnInfoFromNavMap 0 "SpplTrfcSgnInfo_Off" 1 "SpplTrfcSgnInfo_Left" 2 "SpplTrfcSgnInfo_Right" 3 "SpplTrfcSgnInfo_Rain" 4 "SpplTrfcSgnInfo_Snow" 5 "SpplTrfcSgnInfo_Snowandrain" 6 "SpplTrfcSgnInfo_Wet" 7 "SpplTrfcSgnInfo_Ice" 8 "SpplTrfcSgnInfo_Trailer" 9 "SpplTrfcSgnInfo_Zone" 10 "SpplTrfcSgnInfo_Timelimit" 11 "SpplTrfcSgnInfo_Distanceto" 12 "SpplTrfcSgnInfo_Distanceduring" 13 "SpplTrfcSgnInfo_Schoolarea" 14 "SpplTrfcSgnInfo_Fog" 15 "SpplTrfcSgnInfo_Night" 16 "SpplTrfcSgnInfo_Ramp" 17 "SpplTrfcSgnInfo_Generalsupplementarysign" 18 "SpplTrfcSgnInfo_End";
VAL_ 775 VstdModeSts 0 "Mode5_Off" 1 "Mode5_StandBy" 2 "Mode5_On" 3 "Mode5_Alert" 4 "Mode5_Alarm";
VAL_ 86 AsyAutDrvCtrlTypDIMReq 0 "AsyAutDrvCtrlTyp_Inactive" 1 "AsyAutDrvCtrlTyp_ACC" 2 "AsyAutDrvCtrlTyp_GPilot";
VAL_ 86 DrvModReq 0 "DrvModReqType1_Undefd" 1 "DrvModReqType1_ECO" 2 "DrvModReqType1_Comfort_Normal" 3 "DrvModReqType1_Dynamic_Sport" 4 "DrvModReqType1_Individual" 5 "DrvModReqType1_Offroad_CrossTerrain" 6 "DrvModReqType1_Adaptive" 7 "DrvModReqType1_Race" 8 "DrvModReqType1_Pure_EV" 9 "DrvModReqType1_Hybrid" 10 "DrvModReqType1_Power" 11 "DrvModReqType1_Snow" 12 "DrvModReqType1_Sand" 13 "DrvModReqType1_Mud" 14 "DrvModReqType1_Rock" 15 "DrvModReqType1_Err";
VAL_ 86 EpbSoftSwtCtrlSt 0 "EpbSoftSwtCtrlSt_NoRequest" 1 "EpbSoftSwtCtrlSt_ApplyRequest" 2 "EpbSoftSwtCtrlSt_ReleaseRequest" 3 "EpbSoftSwtCtrlSt_Forbidden" 4 "EpbSoftSwtCtrlSt_Unknown";
VAL_ 86 FuLvlIndcdGenQF 0 "GenQf1_UndefindDataAccur" 1 "GenQf1_TmpUndefdData" 2 "GenQf1_DataAccurNotWithinSpcn" 3 "GenQf1_AccurData";
VAL_ 86 GpsStatus 0 "NoYes1_No" 1 "NoYes1_Yes";
VAL_ 86 IntvAndWarnModForLaneKeepAidSts 0 "IntvAndWarnModForLaneKeepAidSts_Inactive" 1 "IntvAndWarnModForLaneKeepAidSts_InterventionAndWarning" 2 "IntvAndWarnModForLaneKeepAidSts_InterventionOnly" 3 "IntvAndWarnModForLaneKeepAidSts_WarningOnly";
VAL_ 86 SetLimReq 0 "SetSpdSts_Unknown" 1 "SetSpdSts_ManuallySet" 2 "SetSpdSts_AutomaticallySet" 3 "SetSpdSts_Reserved";
VAL_ 86 SpdLimdSts 0 "Boolean_FALSE" 1 "Boolean_TRUE";
VAL_ 86 VBFsetg 0 "Level2_Lvl0" 1 "Level2_Lvl1" 2 "Level2_Lvl2" 3 "Level2_Lvl3";
VAL_ 373 AutoHldSoftSwtCtrlSt 0 "OnOff1_Off" 1 "OnOff1_On";
VAL_ 373 CrossInfoDirOfNavRut 0 "DirOfNavRout_Idle" 1 "DirOfNavRout_TurnLe" 2 "DirOfNavRout_TurnRi" 3 "DirOfNavRout_LeAhd" 4 "DirOfNavRout_RiAhd" 5 "DirOfNavRout_SharpLe" 6 "DirOfNavRout_SharpRi" 7 "DirOfNavRout_LeUTurn" 8 "DirOfNavRout_RiUTurn" 9 "DirOfNavRout_Straight";
VAL_ 373 CrossInfoTrfcLi 0 "Boolean_FALSE" 1 "Boolean_TRUE";
VAL_ 373 CtraSwOnOff 0 "OnOff1_Off" 1 "OnOff1_On";
VAL_ 373 DIMStsDistbn 0 "DIMStsDistbn_DIM_status_ok" 1 "DIMStsDistbn_DIM_fault_cause_by_uvOrov" 2 "DIMStsDistbn_DIM_fault_memory_error" 3 "DIMStsDistbn_DIM_LCD_error" 4 "DIMStsDistbn_Reserved1" 5 "DIMStsDistbn_Reserved2" 6 "DIMStsDistbn_Reserved3" 7 "DIMStsDistbn_Reserved4";
VAL_ 373 DOWSwOnOff 0 "OnOff1_Off" 1 "OnOff1_On";
VAL_ 373 DrvrACCFctDeactvnReqSts 0 "OnOff1_Off" 1 "OnOff1_On";
VAL_ 373 DrvrLaneChgAutActvSts 0 "OnOff1_Off" 1 "OnOff1_On";
VAL_ 373 HmiDrvrSodReqChg 0 "ReqChg1_No" 1 "ReqChg1_LeftLaneChg" 2 "ReqChg1_RightLaneChg";
VAL_ 373 HmiSodLanChgSwitch 0 "OnOff1_Off" 1 "OnOff1_On";
VAL_ 373 HmiStrangerModMenuSetActvInActv 0 "Inact_Inactive" 1 "Inact_Active";
VAL_ 373 HmiStrangerModMenuSetPasswordSt 0 "NoYes1_No" 1 "NoYes1_Yes";
VAL_ 373 HmiStrangerModMenuSetPrivateLockSt 0 "NoYes1_No" 1 "NoYes1_Yes";
VAL_ 373 MobDevRPAReq1RPAOutModeSubT 0 "RPAOutModeSubT_Idle" 1 "RPAOutModeSubT_PrlRiOut" 2 "RPAOutModeSubT_RrlLeOut" 3 "RPAOutModeSubT_HeadPrpndRiOut" 4 "RPAOutModeSubT_HeadPrpndLeOut" 5 "RPAOutModeSubT_TailPrpndRiOut" 6 "RPAOutModeSubT_TailPrpndLeOut" 7 "RPAOutModeSubT_Resd1" 8 "RPAOutModeSubT_Resd2";
VAL_ 373 MobDevRPAReq1RPAReq 0 "RPAReq_Idle" 1 "RPAReq_Start" 2 "RPAReq_Stop" 3 "RPAReq_OutMode" 4 "RPAReq_Undo" 5 "RPAReq_Start_Searching" 6 "RPAReq_Start_Parking_In" 7 "RPAReq_Start_Parking_Out" 8 "RPAReq_Pause" 9 "RPAReq_Continue" 10 "RPAReq_Reserved" 11 "RPAReq_RPA_Park_Out_Req" 12 "RPAReq_Return_To_Previous_Menu" 13 "RPAReq_Clickremoteparkinginbutton" 14 "RPAReq_RemParkOutCrsSwtON" 15 "RPAReq_RemParkOutCrsSwtOFF";
VAL_ 373 MobDevRPAReq1RSPACtrl 0 "RSPACtrl_Idle" 1 "RSPACtrl_Function_On" 2 "RSPACtrl_Backward" 3 "RSPACtrl_Forward" 4 "RSPACtrl_Release_Button" 5 "RSPACtrl_Exit_Function" 6 "RSPACtrl_RSPA_Complete";
VAL_ 373 PlannedPahDe 0 "NoYesCrit1_NotVld1" 1 "NoYesCrit1_No" 2 "NoYesCrit1_Yes" 3 "NoYesCrit1_NotVld2";
VAL_ 373 VoiceBrstMod 0 "VoiceBrstMod_NoReq" 1 "VoiceBrstMod_Detail_Mod" 2 "VoiceBrstMod_Streamline_Mod" 3 "VoiceBrstMod_Silent_Mod";
VAL_ 889 DrvrFatiLvlFromDHU 0 "DrvrFatiLvl_Unavailable" 1 "DrvrFatiLvl_Unknown" 2 "DrvrFatiLvl_Attentive" 3 "DrvrFatiLvl_CautionaryState" 4 "DrvrFatiLvl_SevereState" 5 "DrvrFatiLvl_Microsleep" 6 "DrvrFatiLvl_Reserved";
VAL_ 889 EscSptModReqdByDrvr 0 "NoYes1_No" 1 "NoYes1_Yes";
VAL_ 751 CpmswOnOff 0 "OnOff1_Off" 1 "OnOff1_On";
VAL_ 751 HillDwnCtrlSt 0 "OnOff1_Off" 1 "OnOff1_On";
VAL_ 751 HMIAutoShowModSet 0 "OnOff1_Off" 1 "OnOff1_On";
VAL_ 751 HznDataDrivingSide 0 "Boolean_FALSE" 1 "Boolean_TRUE";
VAL_ 751 HznDataMapProvider 0 "MapProvider_Unknown" 1 "MapProvider_NokiaHERENAVTEQ" 2 "MapProvider_TomTomTeleAtlas" 3 "MapProvider_Zenrin" 4 "MapProvider_IPC" 5 "MapProvider_NavInfo" 6 "MapProvider_AutoNavi" 7 "MapProvider_NotAvailable";
VAL_ 751 HznDataMessageType 0 "MessageType_SystemSpecific" 1 "MessageType_POSITION" 2 "MessageType_SEGMENT" 3 "MessageType_STUB" 4 "MessageType_PROFILESHORT" 5 "MessageType_PROFILELONG" 6 "MessageType_METADATA" 7 "MessageType_Reserved";
VAL_ 751 HznDataSpeedUnits 0 "Boolean_FALSE" 1 "Boolean_TRUE";
VAL_ 751 IndcnUnitClkFmt 0 "ClkFmt_Hr24" 1 "ClkFmt_Hr12" 2 "ClkFmt_UkwnClkFmt";
VAL_ 751 IndcnUnitDateFmt 0 "DateFmt_DateFmt1" 1 "DateFmt_DateFmt2" 2 "DateFmt_DateFmt3" 3 "DateFmt_UkwnFmt";
VAL_ 751 IndcnUnitDstLong 0 "DstLong_km" 1 "DstLong_miles" 2 "DstLong_UkwnUnit";
VAL_ 751 IndcnUnitDstSho 0 "DstSho_Mtr" 1 "DstSho_Ft" 2 "DstSho_Yards" 3 "DstSho_UkwnUnit";
VAL_ 751 IndcnUnitFuCnsUnit 0 "FuCnsIndcdUnit_LperHectoKiloM" 1 "FuCnsIndcdUnit_KiloMPerL" 2 "FuCnsIndcdUnit_MilePerGallonEngland" 3 "FuCnsIndcdUnit_MilePerGallonUsa" 4 "FuCnsIndcdUnit_UkwnUnit";
VAL_ 751 IndcnUnitPUnit 0 "PUnit_Pa" 1 "PUnit_Psi" 2 "PUnit_Bar" 3 "PUnit_Atm" 4 "PUnit_UkwnUnit";
VAL_ 751 IndcnUnitSpdUnit 0 "VehSpdIndcdUnit_Kmph" 1 "VehSpdIndcdUnit_Mph" 2 "VehSpdIndcdUnit_UkwnUnit";
VAL_ 751 IndcnUnitTUnit 0 "AmbTIndcdUnit_Celsius" 1 "AmbTIndcdUnit_Fahrenheit" 2 "AmbTIndcdUnit_UkwnUnit";
VAL_ 751 IndcnUnitVolUnit 0 "VolUnit_litre" 1 "VolUnit_gallon1" 2 "VolUnit_gallon2" 3 "VolUnit_UkwnUnit";
VAL_ 751 MiscTrfcSgnInfoFromNavMap 0 "TrfcInfoMiscFirst_Off" 1 "TrfcInfoMiscFirst_NoEntrance" 2 "TrfcInfoMiscFirst_VehiclePassingNotAllowed" 3 "TrfcInfoMiscFirst_EndOfVehiclePassingNotAllowed" 4 "TrfcInfoMiscFirst_Stop" 5 "TrfcInfoMiscFirst_SpeedLimitControl" 6 "TrfcInfoMiscFirst_USNightSpeedLimit" 7 "TrfcInfoMiscFirst_Schoolandchildrenwarning" 8 "TrfcInfoMiscFirst_Roadwork" 9 "TrfcInfoMiscFirst_leftcurve" 10 "TrfcInfoMiscFirst_rightcurve" 11 "TrfcInfoMiscFirst_seriescurves" 12 "TrfcInfoMiscFirst_Reserved";
VAL_ 824 HznEdgeComplexIntersection 0 "ComplexIntersection_ItIsNotPartOfComplexIntersection" 1 "ComplexIntersection_ItIsPartOfAComplexIntersection" 2 "ComplexIntersection_Unknown" 3 "ComplexIntersection_NotApplied";
VAL_ 824 HznEdgeLastStubAtOffset 0 "Boolean_FALSE" 1 "Boolean_TRUE";
VAL_ 824 HznEdgeMessageType 0 "MessageType_SystemSpecific" 1 "MessageType_POSITION" 2 "MessageType_SEGMENT" 3 "MessageType_STUB" 4 "MessageType_PROFILESHORT" 5 "MessageType_PROFILELONG" 6 "MessageType_METADATA" 7 "MessageType_Reserved";
VAL_ 824 HznEdgePartOfCalculatedRoute 0 "PartOfCalculatedRoute_ItIsNotPartOfCalculatedRoute" 1 "PartOfCalculatedRoute_ItIsPartOfCalculatedRoute" 2 "PartOfCalculatedRoute_Unknown" 3 "PartOfCalculatedRoute_NotApplied";
VAL_ 824 HznEdgeRetransmission 0 "Boolean_FALSE" 1 "Boolean_TRUE";
VAL_ 824 HznEdgeRightofWay 0 "RightofWay_DrivingTowardsThisStubHasPriorityOverAllConflictingVehicleMovements" 1 "RightofWay_DrivingTowardsThisStubMightRequireYieldingToConflictingVehicleMovements" 2 "RightofWay_Unknown" 3 "RightofWay_NotApplied";
VAL_ 824 HznEdgeUpdate 0 "Boolean_FALSE" 1 "Boolean_TRUE";
VAL_ 824 HznProfLongControlPoint 0 "Boolean_FALSE" 1 "Boolean_TRUE";
VAL_ 824 HznProfLongMessageType 0 "MessageType_SystemSpecific" 1 "MessageType_POSITION" 2 "MessageType_SEGMENT" 3 "MessageType_STUB" 4 "MessageType_PROFILESHORT" 5 "MessageType_PROFILELONG" 6 "MessageType_METADATA" 7 "MessageType_Reserved";
VAL_ 824 HznProfLongRetransmission 0 "Boolean_FALSE" 1 "Boolean_TRUE";
VAL_ 824 HznProfLongUpdate 0 "Boolean_FALSE" 1 "Boolean_TRUE";
VAL_ 824 HznProfShoAccuracy 0 "Accuracy_highestAccuracy" 1 "Accuracy_mediumAccuracy" 2 "Accuracy_lowestAccuracy" 3 "Accuracy_Unknown";
VAL_ 824 HznProfShoControlPoint 0 "Boolean_FALSE" 1 "Boolean_TRUE";
VAL_ 824 HznProfShoMessageType 0 "MessageType_SystemSpecific" 1 "MessageType_POSITION" 2 "MessageType_SEGMENT" 3 "MessageType_STUB" 4 "MessageType_PROFILESHORT" 5 "MessageType_PROFILELONG" 6 "MessageType_METADATA" 7 "MessageType_Reserved";
VAL_ 824 HznProfShoRetransmission 0 "Boolean_FALSE" 1 "Boolean_TRUE";
VAL_ 824 HznProfShoUpdate 0 "Boolean_FALSE" 1 "Boolean_TRUE";
VAL_ 824 HznSegBridge 0 "Bridge_SegmentIsNotPartOfABridge" 1 "Bridge_SegmentIsPartOfABridge" 2 "Bridge_Unknown" 3 "Bridge_NotApplicable";
VAL_ 824 HznSegBuiltupArea 0 "BuiltupArea_SegmentIsNotPartOfABuiltUpArea" 1 "BuiltupArea_SegmentIsPartOfABuiltUpArea" 2 "BuiltupArea_Unknown" 3 "BuiltupArea_NotApplied";
VAL_ 824 HznSegComplexIntersection 0 "ComplexIntersection_ItIsNotPartOfComplexIntersection" 1 "ComplexIntersection_ItIsPartOfAComplexIntersection" 2 "ComplexIntersection_Unknown" 3 "ComplexIntersection_NotApplied";
VAL_ 824 HznSegDividedRoad 0 "DividedRoad_SegmentIsNotPartOfaDividedRoadOrDualCarriageWay" 1 "DividedRoad_SegmentIsPartOfaDividedRoadOrDualCarriageWay" 2 "DividedRoad_Unknown" 3 "DividedRoad_NotApplicable";
VAL_ 824 HznSegMessageType 0 "MessageType_SystemSpecific" 1 "MessageType_POSITION" 2 "MessageType_SEGMENT" 3 "MessageType_STUB" 4 "MessageType_PROFILESHORT" 5 "MessageType_PROFILELONG" 6 "MessageType_METADATA" 7 "MessageType_Reserved";
VAL_ 824 HznSegPartOfCalculatedRoute 0 "PartOfCalculatedRoute_ItIsNotPartOfCalculatedRoute" 1 "PartOfCalculatedRoute_ItIsPartOfCalculatedRoute" 2 "PartOfCalculatedRoute_Unknown" 3 "PartOfCalculatedRoute_NotApplied";
VAL_ 824 HznSegRetransmission 0 "Boolean_FALSE" 1 "Boolean_TRUE";
VAL_ 824 HznSegTunnel 0 "Tunnel_SegmentIsNotPartOfATunnel" 1 "Tunnel_SegmentIsPartOfATunnel" 2 "Tunnel_Unknown" 3 "Tunnel_NotApplied";
VAL_ 824 HznSegUpdate 0 "Boolean_FALSE" 1 "Boolean_TRUE";
VAL_ 504 ProfPenSts1 0 "IdPen_ProfUkwn" 1 "IdPen_Prof1" 2 "IdPen_Prof2" 3 "IdPen_Prof3" 4 "IdPen_Prof4" 5 "IdPen_Prof5" 6 "IdPen_Prof6" 7 "IdPen_Prof7" 8 "IdPen_Prof8" 9 "IdPen_Prof9" 10 "IdPen_Prof10" 11 "IdPen_Prof11" 12 "IdPen_Prof12" 13 "IdPen_Prof13" 14 "IdPen_Resd14" 15 "IdPen_ProfAll";
VAL_ 504 PtDrvrSetg 0 "DrvModReqType1_Undefd" 1 "DrvModReqType1_ECO" 2 "DrvModReqType1_Comfort_Normal" 3 "DrvModReqType1_Dynamic_Sport" 4 "DrvModReqType1_Individual" 5 "DrvModReqType1_Offroad_CrossTerrain" 6 "DrvModReqType1_Adaptive" 7 "DrvModReqType1_Race" 8 "DrvModReqType1_Pure_EV" 9 "DrvModReqType1_Hybrid" 10 "DrvModReqType1_Power" 11 "DrvModReqType1_Snow" 12 "DrvModReqType1_Sand" 13 "DrvModReqType1_Mud" 14 "DrvModReqType1_Rock" 15 "DrvModReqType1_Err";
VAL_ 504 SftySigGroupFromHmiSafe1SftyHmiDend 0 "NoYesCrit1_NotVld1" 1 "NoYesCrit1_No" 2 "NoYesCrit1_Yes" 3 "NoYesCrit1_NotVld2";
VAL_ 504 SftySigGroupFromHmiSafe1SftyHmiEna 0 "NoYesCrit1_NotVld1" 1 "NoYesCrit1_No" 2 "NoYesCrit1_Yes" 3 "NoYesCrit1_NotVld2";
VAL_ 504 SftySigGroupFromHmiSafe1SftySigFaildDetdByHmi 0 "NoYesCrit1_NotVld1" 1 "NoYesCrit1_No" 2 "NoYesCrit1_Yes" 3 "NoYesCrit1_NotVld2";
VAL_ 504 SnsrDrvrPfmncStsFromDHU 0 "Sensor_StrtUp" 1 "Sensor_Shutdown" 2 "Sensor_Runng" 3 "Sensor_Blkd" 4 "Sensor_Faulty" 5 "Sensor_Hot" 6 "Sensor_Vol" 7 "Sensor_Curr";
VAL_ 504 VehDecelCtrlSetg 0 "NormSptType_Norm" 1 "NormSptType_Spt";
VAL_ 352 AccFusnTrfcReq 0 "OnOff1_Off" 1 "OnOff1_On";
VAL_ 352 BSDaudioOnOff 0 "OnOff1_Off" 1 "OnOff1_On";
VAL_ 352 BSDSwOnOff 0 "OnOff1_Off" 1 "OnOff1_On";
VAL_ 352 EpbApplyAutSetg 0 "OnOff1_Off" 1 "OnOff1_On";
VAL_ 352 HznSplyElectcSts 0 "HznSplyElectcSts1_Ukwn" 1 "HznSplyElectcSts1_NoSpprt" 2 "HznSplyElectcSts1_Failr" 3 "HznSplyElectcSts1_Spprt";
VAL_ 352 LaneKeepAidActvSts 0 "OnOff1_Off" 1 "OnOff1_On";
VAL_ 352 NavInfoSts 0 "NoYes1_No" 1 "NoYes1_Yes";
VAL_ 352 OffsForSpdWarnSetgReq 0 "OffsForSpdWarnSetgReq_Inactive" 1 "OffsForSpdWarnSetgReq_Plus" 2 "OffsForSpdWarnSetgReq_Minus";
VAL_ 352 OffsForSpdWarnSetgReqSts 0 "SetgReqSts_Zero" 1 "SetgReqSts_Minus10kmh" 2 "SetgReqSts_Minus5kmh" 3 "SetgReqSts_Plus5kmh" 4 "SetgReqSts_Plus10kmh" 5 "SetgReqSts_Minus5mph" 6 "SetgReqSts_Minus3mph" 7 "SetgReqSts_Plus3mph" 8 "SetgReqSts_Plus5mph" 9 "SetgReqSts_Minus10Percentage" 10 "SetgReqSts_Minus5Percentage" 11 "SetgReqSts_Plus5Percentage" 12 "SetgReqSts_Plus10Percentage" 13 "SetgReqSts_Reserved1" 14 "SetgReqSts_Reserved2" 15 "SetgReqSts_Reserved3";
VAL_ 352 RampInfoEnterRamp 0 "Boolean_FALSE" 1 "Boolean_TRUE";
VAL_ 352 RCWSwOnOff 0 "OnOff1_Off" 1 "OnOff1_On";
VAL_ 352 RoadMiscSgnInfoForRoadSgnInfoSts 0 "OnOff1_Off" 1 "OnOff1_On";
VAL_ 352 RoadSgnInfoActvSts 0 "OnOff1_Off" 1 "OnOff1_On";
VAL_ 352 SmtSteerAssidSwtReq 0 "PsdNotPsd_NotPsd" 1 "PsdNotPsd_Psd";
VAL_ 352 SpdAlrmActvForRoadSgnInfoSts 0 "DY1_NoRequest" 1 "DY1_NoWarning" 2 "DY1_Flashing" 3 "DY1_FlashingAndAudio";
VAL_ 352 TrlrModSwtReq 0 "OnOff1_Off" 1 "OnOff1_On";
VAL_ 352 VehSpdIndcdQly 0 "GenQf1_UndefindDataAccur" 1 "GenQf1_TmpUndefdData" 2 "GenQf1_DataAccurNotWithinSpcn" 3 "GenQf1_AccurData";
VAL_ 352 VehSpdIndcdVeSpdIndcdUnit 0 "VehSpdIndcdUnit_Kmph" 1 "VehSpdIndcdUnit_Mph" 2 "VehSpdIndcdUnit_UkwnUnit";
VAL_ 352 WarnTypForLaneKeepAidSts 0 "ChgWarnMod_No" 1 "ChgWarnMod_Sound" 2 "ChgWarnMod_Haptic";
VAL_ 1289 WakeUpReasonsforDHU 0 "WakeupReasons_667949" 1 "WakeupReasons_667950" 2 "WakeupReasons_169654" 3 "WakeupReasons_667951" 4 "WakeupReasons_168965" 5 "WakeupReasons_197643" 6 "WakeupReasons_264933" 7 "WakeupReasons_45654" 8 "WakeupReasons_22058" 9 "WakeupReasons_49446" 10 "WakeupReasons_22060" 11 "WakeupReasons_269740" 12 "WakeupReasons_269735" 13 "WakeupReasons_269739" 14 "WakeupReasons_658500" 15 "WakeupReasons_21901" 16 "WakeupReasons_45793" 17 "WakeupReasons_45794" 18 "WakeupReasons_22005" 19 "WakeupReasons_22013" 20 "WakeupReasons_22100" 21 "WakeupReasons_45659" 22 "WakeupReasons_45657" 23 "WakeupReasons_140084" 24 "WakeupReasons_21973" 25 "WakeupReasons_91253" 26 "WakeupReasons_88123" 27 "WakeupReasons_88125" 28 "WakeupReasons_321583" 29 "WakeupReasons_74188" 30 "WakeupReasons_667945" 31 "WakeupReasons_169655" 32 "WakeupReasons_667948" 33 "WakeupReasons_168966" 34 "WakeupReasons_170865" 35 "WakeupReasons_197642" 36 "WakeupReasons_264876" 37 "WakeupReasons_191050" 38 "WakeupReasons_182033" 39 "WakeupReasons_200937" 40 "WakeupReasons_170807" 41 "WakeupReasons_319139" 42 "WakeupReasons_100298" 43 "WakeupReasons_100275" 44 "WakeupReasons_100300" 45 "WakeupReasons_100278" 46 "WakeupReasons_100281" 47 "WakeupReasons_265333" 48 "WakeupReasons_108776" 49 "WakeupReasons_176921" 50 "WakeupReasons_197826" 51 "WakeupReasons_185670" 52 "WakeupReasons_161066" 53 "WakeupReasons_200156" 54 "WakeupReasons_225696" 55 "WakeupReasons_21997" 56 "WakeupReasons_45656" 57 "WakeupReasons_266860" 58 "WakeupReasons_169894" 59 "WakeupReasons_320282" 60 "WakeupReasons_319422" 61 "WakeupReasons_320277" 62 "WakeupReasons_355601" 63 "WakeupReasons_360904" 64 "WakeupReasons_361505" 65 "WakeupReasons_361509" 66 "WakeupReasons_645094" 67 "WakeupReasons_68676" 68 "WakeupReasons_360008" 69 "WakeupReasons_109382" 70 "WakeupReasons_119273" 71 "WakeupReasons_224065" 72 "WakeupReasons_68644" 73 "WakeupReasons_109364" 74 "WakeupReasons_68481" 75 "WakeupReasons_224061" 76 "WakeupReasons_360006" 77 "WakeupReasons_138997" 78 "WakeupReasons_634696" 79 "WakeupReasons_645810" 80 "WakeupReasons_297868" 81 "WakeupReasons_315364" 82 "WakeupReasons_109367" 83 "WakeupReasons_320126" 84 "WakeupReasons_109387" 85 "WakeupReasons_634710" 86 "WakeupReasons_338820" 87 "WakeupReasons_67182" 88 "WakeupReasons_152237" 89 "WakeupReasons_145707" 90 "WakeupReasons_199172" 91 "WakeupReasons_144897" 92 "WakeupReasons_186489" 93 "WakeupReasons_144970" 94 "WakeupReasons_152786" 95 "WakeupReasons_264932" 96 "WakeupReasons_264934" 97 "WakeupReasons_356190" 98 "WakeupReasons_145688" 99 "WakeupReasons_95444" 100 "WakeupReasons_169945" 101 "WakeupReasons_140678" 102 "WakeupReasons_222553" 103 "WakeupReasons_224831" 104 "WakeupReasons_201815" 105 "WakeupReasons_45864" 106 "WakeupReasons_659549" 107 "WakeupReasons_45866" 108 "WakeupReasons_45867" 109 "WakeupReasons_169884" 110 "WakeupReasons_264962" 111 "WakeupReasons_201348" 112 "WakeupReasons_320287" 113 "WakeupReasons_156412" 114 "WakeupReasons_133749" 115 "WakeupReasons_355409" 116 "WakeupReasons_636692" 117 "WakeupReasons_533044" 118 "WakeupReasons_106774" 119 "WakeupReasons_145311" 120 "WakeupReasons_145319" 121 "WakeupReasons_152774" 122 "WakeupReasons_145330" 123 "WakeupReasons_145388" 124 "WakeupReasons_145399" 125 "WakeupReasons_145362" 126 "WakeupReasons_145385" 127 "WakeupReasons_145373" 128 "WakeupReasons_145288" 129 "WakeupReasons_145419" 130 "WakeupReasons_145454" 131 "WakeupReasons_145462" 132 "WakeupReasons_269156" 133 "WakeupReasons_300427" 134 "WakeupReasons_220322" 135 "WakeupReasons_224617" 136 "WakeupReasons_224634" 137 "WakeupReasons_300682" 138 "WakeupReasons_264958" 139 "WakeupReasons_160597" 140 "WakeupReasons_160602" 141 "WakeupReasons_108841" 142 "WakeupReasons_265569" 143 "WakeupReasons_526429" 144 "WakeupReasons_514545" 145 "WakeupReasons_265232" 146 "WakeupReasons_644550" 147 "WakeupReasons_317616" 148 "WakeupReasons_354791" 149 "WakeupReasons_320631" 150 "WakeupReasons_337565" 151 "WakeupReasons_532007" 152 "WakeupReasons_514503" 153 "WakeupReasons_299117" 154 "WakeupReasons_340667" 155 "WakeupReasons_321845" 156 "WakeupReasons_179103" 157 "WakeupReasons_108810" 158 "WakeupReasons_322857" 159 "WakeupReasons_658603" 160 "WakeupReasons_197648" 161 "WakeupReasons_160596" 162 "WakeupReasons_361272" 163 "WakeupReasons_361279" 164 "WakeupReasons_265305" 165 "WakeupReasons_265328" 166 "WakeupReasons_265330" 167 "WakeupReasons_298808" 168 "WakeupReasons_515804" 169 "WakeupReasons_514502" 170 "WakeupReasons_645753" 171 "WakeupReasons_646109" 172 "WakeupReasons_299547" 173 "WakeupReasons_318342" 174 "WakeupReasons_360543" 175 "WakeupReasons_356549" 176 "WakeupReasons_198484" 177 "WakeupReasons_300681" 178 "WakeupReasons_359211" 179 "WakeupReasons_534077" 180 "WakeupReasons_525705" 181 "WakeupReasons_360299" 182 "WakeupReasons_526445" 183 "WakeupReasons_534145" 184 "WakeupReasons_192030" 185 "WakeupReasons_652361" 186 "WakeupReasons_355214" 187 "WakeupReasons_321317" 188 "WakeupReasons_359187" 189 "WakeupReasons_321057" 190 "WakeupReasons_321319" 191 "WakeupReasons_321323" 192 "WakeupReasons_321077" 193 "WakeupReasons_320895" 194 "WakeupReasons_655340" 195 "WakeupReasons_636556" 196 "WakeupReasons_108834" 197 "WakeupReasons_265937" 198 "WakeupReasons_533050" 199 "WakeupReasons_526426" 200 "WakeupReasons_264712" 201 "WakeupReasons_319401" 202 "WakeupReasons_643973" 203 "WakeupReasons_223715" 204 "WakeupReasons_199159" 205 "WakeupReasons_318382" 206 "WakeupReasons_226967" 207 "WakeupReasons_531743" 208 "WakeupReasons_360542" 209 "WakeupReasons_264726" 210 "WakeupReasons_535214" 211 "WakeupReasons_335068" 212 "WakeupReasons_316796" 213 "WakeupReasons_526438" 214 "WakeupReasons_198433" 215 "WakeupReasons_225961" 216 "WakeupReasons_197665" 217 "WakeupReasons_224550" 218 "WakeupReasons_667962" 219 "WakeupReasons_667953" 220 "WakeupReasons_110885" 221 "WakeupReasons_224552" 222 "WakeupReasons_224553" 223 "WakeupReasons_652546" 224 "WakeupReasons_331194" 225 "WakeupReasons_667820" 226 "WakeupReasons_659350" 227 "WakeupReasons_101706" 228 "WakeupReasons_101725" 229 "WakeupReasons_101728" 230 "WakeupReasons_101727" 231 "WakeupReasons_166267" 232 "WakeupReasons_156440" 233 "WakeupReasons_95949" 234 "WakeupReasons_112799" 235 "WakeupReasons_146470" 236 "WakeupReasons_176748" 237 "WakeupReasons_223920" 238 "WakeupReasons_668531" 239 "WakeupReasons_670087" 240 "WakeupReasons_668529" 241 "WakeupReasons_45858" 242 "WakeupReasons_315981" 243 "WakeupReasons_533370" 244 "WakeupReasons_533371" 245 "WakeupReasons_533372" 246 "WakeupReasons_241902" 247 "WakeupReasons_359559" 248 "WakeupReasons_516327" 249 "WakeupReasons_533872" 250 "WakeupReasons_45856" 251 "WakeupReasons_45853" 252 "WakeupReasons_45854" 253 "WakeupReasons_45852" 254 "WakeupReasons_45851" 255 "WakeupReasons_45850" 256 "WakeupReasons_45849" 257 "WakeupReasons_636801" 258 "WakeupReasons_109466" 259 "WakeupReasons_109467" 260 "WakeupReasons_670345" 261 "WakeupReasons_NMPDUReceived" 262 "WakeupReasons_358832" 263 "WakeupReasons_200683" 264 "WakeupReasons_198452" 265 "WakeupReasons_185457" 266 "WakeupReasons_185490" 267 "WakeupReasons_4471" 268 "WakeupReasons_269034" 269 "WakeupReasons_215560" 270 "WakeupReasons_312881" 271 "WakeupReasons_269140" 272 "WakeupReasons_197653" 273 "WakeupReasons_337991" 274 "WakeupReasons_658188" 275 "WakeupReasons_674953" 276 "WakeupReasons_675064" 277 "WakeupReasons_674958" 278 "WakeupReasons_675494" 279 "WakeupReasons_675837" 280 "WakeupReasons_667879" 281 "WakeupReasons_667947" 282 "WakeupReasons_676265" 283 "WakeupReasons_669465" 284 "WakeupReasons_670928" 285 "WakeupReasons_669447" 286 "WakeupReasons_667922" 287 "WakeupReasons_670753" 288 "WakeupReasons_668395" 289 "WakeupReasons_668393" 290 "WakeupReasons_667850" 291 "WakeupReasons_667848" 292 "WakeupReasons_311279" 293 "WakeupReasons_182918" 294 "WakeupReasons_667988" 295 "WakeupReasons_532555" 296 "WakeupReasons_532556" 297 "WakeupReasons_113348" 298 "WakeupReasons_193474" 299 "WakeupReasons_667871" 300 "WakeupReasons_670966" 301 "WakeupReasons_667985" 302 "WakeupReasons_670354" 303 "WakeupReasons_46017" 304 "WakeupReasons_675742" 305 "WakeupReasons_106669" 306 "WakeupReasons_80609" 307 "WakeupReasons_199714" 308 "WakeupReasons_200090" 309 "WakeupReasons_139075" 310 "WakeupReasons_268983" 311 "WakeupReasons_265131" 312 "WakeupReasons_263473" 313 "WakeupReasons_45887" 314 "WakeupReasons_69678" 315 "WakeupReasons_69679" 316 "WakeupReasons_45897" 317 "WakeupReasons_45898" 318 "WakeupReasons_80608" 319 "WakeupReasons_45869" 320 "WakeupReasons_45870" 321 "WakeupReasons_45872" 322 "WakeupReasons_45875" 323 "WakeupReasons_45871" 324 "WakeupReasons_45876" 325 "WakeupReasons_667980" 326 "WakeupReasons_45877" 327 "WakeupReasons_667973" 328 "WakeupReasons_670962" 329 "WakeupReasons_45888" 330 "WakeupReasons_45890" 331 "WakeupReasons_667869" 332 "WakeupReasons_45846" 333 "WakeupReasons_45847" 334 "WakeupReasons_45848" 335 "WakeupReasons_262872" 336 "WakeupReasons_127924" 337 "WakeupReasons_127926" 338 "WakeupReasons_674223" 339 "WakeupReasons_667982" 340 "WakeupReasons_657121" 341 "WakeupReasons_265745" 342 "WakeupReasons_657120" 343 "WakeupReasons_675564" 344 "WakeupReasons_197644" 345 "WakeupReasons_264943" 346 "WakeupReasons_264697" 347 "WakeupReasons_69216" 348 "WakeupReasons_128671" 349 "WakeupReasons_356598" 350 "WakeupReasons_675745" 351 "WakeupReasons_667983" 352 "WakeupReasons_667987" 353 "WakeupReasons_75103" 354 "WakeupReasons_305818" 355 "WakeupReasons_670942" 356 "WakeupReasons_532932" 357 "WakeupReasons_532933" 358 "WakeupReasons_83199" 359 "WakeupReasons_45900" 360 "WakeupReasons_88458" 361 "WakeupReasons_329457" 362 "WakeupReasons_45902" 363 "WakeupReasons_224211" 364 "WakeupReasons_667981" 365 "WakeupReasons_667874" 366 "WakeupReasons_46020" 367 "WakeupReasons_667842" 368 "WakeupReasons_145161" 369 "WakeupReasons_233755" 370 "WakeupReasons_297056" 371 "WakeupReasons_264691" 372 "WakeupReasons_262871" 373 "WakeupReasons_264964" 374 "WakeupReasons_667872" 375 "WakeupReasons_45655" 376 "WakeupReasons_177214" 377 "WakeupReasons_671005" 378 "WakeupReasons_680712" 379 "WakeupReasons_669822" 380 "WakeupReasons_668523" 381 "WakeupReasons_680974" 382 "WakeupReasons_680975" 383 "WakeupReasons_681028" 384 "WakeupReasons_670462" 385 "WakeupReasons_681134" 386 "WakeupReasons_681031" 387 "WakeupReasons_681711" 388 "WakeupReasons_682034" 389 "WakeupReasons_674839" 390 "WakeupReasons_681915" 391 "WakeupReasons_682032" 392 "WakeupReasons_682037" 393 "WakeupReasons_682688" 394 "WakeupReasons_681789" 395 "WakeupReasons_682023" 396 "WakeupReasons_681023" 397 "WakeupReasons_676285" 398 "WakeupReasons_682077" 399 "WakeupReasons_682076" 400 "WakeupReasons_682078" 401 "WakeupReasons_682153" 402 "WakeupReasons_682155" 403 "WakeupReasons_682152" 404 "WakeupReasons_682154" 405 "WakeupReasons_682074";
VAL_ 821 MirrOpenClsReq 0 "MirrFoldCmdTyp_Idle" 1 "MirrFoldCmdTyp_FoldIn" 2 "MirrFoldCmdTyp_FoldOut";
VAL_ 528 PrkgStsToEDRAPATo 0 "APATo_Defualt" 1 "APATo_Faulted" 2 "APATo_Off" 3 "APATo_StandBy" 4 "APATo_Active" 5 "APATo_Reserved1" 6 "APATo_Reserved2" 7 "APATo_Reserved3";
VAL_ 528 PrkgStsToEDRHPATo 0 "APATo_Defualt" 1 "APATo_Faulted" 2 "APATo_Off" 3 "APATo_StandBy" 4 "APATo_Active" 5 "APATo_Reserved1" 6 "APATo_Reserved2" 7 "APATo_Reserved3";
VAL_ 528 PrkgStsToEDRLSDAandTBATo 0 "APATo_Defualt" 1 "APATo_Faulted" 2 "APATo_Off" 3 "APATo_StandBy" 4 "APATo_Active" 5 "APATo_Reserved1" 6 "APATo_Reserved2" 7 "APATo_Reserved3";
VAL_ 528 PrkgStsToEDRreserved1 0 "APATo_Defualt" 1 "APATo_Faulted" 2 "APATo_Off" 3 "APATo_StandBy" 4 "APATo_Active" 5 "APATo_Reserved1" 6 "APATo_Reserved2" 7 "APATo_Reserved3";
VAL_ 528 PrkgStsToEDRreserved2 0 "APATo_Defualt" 1 "APATo_Faulted" 2 "APATo_Off" 3 "APATo_StandBy" 4 "APATo_Active" 5 "APATo_Reserved1" 6 "APATo_Reserved2" 7 "APATo_Reserved3";
VAL_ 528 PrkgStsToEDRreserved3 0 "APATo_Defualt" 1 "APATo_Faulted" 2 "APATo_Off" 3 "APATo_StandBy" 4 "APATo_Active" 5 "APATo_Reserved1" 6 "APATo_Reserved2" 7 "APATo_Reserved3";
VAL_ 528 PrkgStsToEDRRPATo 0 "APATo_Defualt" 1 "APATo_Faulted" 2 "APATo_Off" 3 "APATo_StandBy" 4 "APATo_Active" 5 "APATo_Reserved1" 6 "APATo_Reserved2" 7 "APATo_Reserved3";
VAL_ 528 VehPrkgLockTheftReq 0 "VehPrkgLockTheftReq_NoRequest" 1 "VehPrkgLockTheftReq_InsideLockAndIncompleteArmRequest" 2 "VehPrkgLockTheftReq_OutsideLockAndCompleteArmRequest" 3 "VehPrkgLockTheftReq_UnlockAndDisarmRequest";
VAL_ 528 VehWinSunRoofClsReq 0 "OpenCls3_NoRequest" 1 "OpenCls3_Close" 2 "OpenCls3_Reserved1" 3 "OpenCls3_Reserved2";
VAL_ 96 GearPrkgAssiReqGroupGearPrkgAssiReq1 0 "GearPrkgAssiReq1_NoRequest" 1 "GearPrkgAssiReq1_TargetgearP" 2 "GearPrkgAssiReq1_TargetgearR" 3 "GearPrkgAssiReq1_TargetgearD";
VAL_ 96 PrkgAsscSysEcuTyp 0 "PrkgAsscSysEcuTyp_PAS1" 1 "PrkgAsscSysEcuTyp_PAS2" 2 "PrkgAsscSysEcuTyp_PAS3";
VAL_ 96 PrkgAssiElectcStabyProgCtrlModReqGroupPASElectcStabyProgCtrlModReq 0 "PASElectcStabyProgCtrlMod_NoRequest" 1 "PASElectcStabyProgCtrlMod_APARequest" 2 "PASElectcStabyProgCtrlMod_RPArequest" 3 "PASElectcStabyProgCtrlMod_HPArequest" 4 "PASElectcStabyProgCtrlMod_APAcontrolactive" 5 "PASElectcStabyProgCtrlMod_RPAcontrolactive" 6 "PASElectcStabyProgCtrlMod_HPAcontrolactive" 7 "PASElectcStabyProgCtrlMod_Reserved2";
VAL_ 96 PrkgAssiSysRemPrkgSts 0 "PrkgAssiSysRemPrkgSts_OFF" 1 "PrkgAssiSysRemPrkgSts_Remoteparkinstandby" 2 "PrkgAssiSysRemPrkgSts_Remoteparkoutstandby" 3 "PrkgAssiSysRemPrkgSts_Searching" 4 "PrkgAssiSysRemPrkgSts_Remoteparkinpreactive" 5 "PrkgAssiSysRemPrkgSts_Remoteparkactive" 6 "PrkgAssiSysRemPrkgSts_Parkprocessactive" 7 "PrkgAssiSysRemPrkgSts_Suspend" 8 "PrkgAssiSysRemPrkgSts_Abort" 9 "PrkgAssiSysRemPrkgSts_Remoteparkprocesscompleted" 10 "PrkgAssiSysRemPrkgSts_Remoteparkoutprocscompleted" 11 "PrkgAssiSysRemPrkgSts_Remoteparkcompleted" 12 "PrkgAssiSysRemPrkgSts_Quit" 13 "PrkgAssiSysRemPrkgSts_Failure" 14 "PrkgAssiSysRemPrkgSts_Cancel";
VAL_ 96 PrkgEmgyBrkEmgyBrkReq 0 "ReqSts1_NotReqd" 1 "ReqSts1_Reqd";
VAL_ 96 PrkgEmgyBrkEpbApplyReq 0 "ReqSts1_NotReqd" 1 "ReqSts1_Reqd";
VAL_ 96 PrkgEmgyBrkStandStillReq 0 "ReqSts1_NotReqd" 1 "ReqSts1_Reqd";
VAL_ 96 PrkgSpdCtrlSafeGroupDrvrAsscSysBrkFctMod 0 "DrvrAsscSysBrkFctMod_Default" 1 "DrvrAsscSysBrkFctMod_Comfortable" 2 "DrvrAsscSysBrkFctMod_Emergency";
VAL_ 96 PrkgUsgDrvModTranReq 0 "Inact_Inactive" 1 "Inact_Active";
VAL_ 96 VehBeamLoModReq 0 "OnOffNoReq_NoReq" 1 "OnOffNoReq_On" 2 "OnOffNoReq_Off";
VAL_ 96 VehPrkgToHorn 0 "OnOff1_Off" 1 "OnOff1_On";
VAL_ 784 PrkgFctVMMModReq 0 "NoYes1_No" 1 "NoYes1_Yes";
VAL_ 274 DrvrAsscSysIndcrReq 0 "PASTurnIndcrReq_NoRequest" 1 "PASTurnIndcrReq_LeftRequest" 2 "PASTurnIndcrReq_RightRequest" 3 "PASTurnIndcrReq_HWLReq";
VAL_ 274 DrvrAsscSysIndcrReq1 0 "DrvrAsscSysIndcrReq1_NoRequest" 1 "DrvrAsscSysIndcrReq1_LeftRequestOff" 2 "DrvrAsscSysIndcrReq1_RightRequestOff" 3 "DrvrAsscSysIndcrReq1_HWLRequestOff" 4 "DrvrAsscSysIndcrReq1_Reserved1" 5 "DrvrAsscSysIndcrReq1_Reserved2" 6 "DrvrAsscSysIndcrReq1_Reserved3" 7 "DrvrAsscSysIndcrReq1_Reserved4";
VAL_ 274 DrvrAsscSysSts 0 "DrvrAsscSysSts_Off" 1 "DrvrAsscSysSts_Standby" 2 "DrvrAsscSysSts_Failure" 3 "DrvrAsscSysSts_Searching" 4 "DrvrAsscSysSts_ParkingProcessActive" 5 "DrvrAsscSysSts_ParkingProcessCompleted" 6 "DrvrAsscSysSts_Quit" 7 "DrvrAsscSysSts_Suspend" 8 "DrvrAsscSysSts_Abort" 9 "DrvrAsscSysSts_PreParkingprocessactive";
VAL_ 274 PrkgAccrOvrdnCtrlReqgrpPrkgAccrOvrdnCtrlReq 0 "YesNo1_Yes" 1 "YesNo1_No";
VAL_ 274 PrkgBrkElectcCtrlReqReq 0 "PrkgBrkElectcCtrlReq_NoRequest" 1 "PrkgBrkElectcCtrlReq_ReleaseRequest" 2 "PrkgBrkElectcCtrlReq_ApplyRequest" 3 "PrkgBrkElectcCtrlReq_Reserved";
VAL_ 274 PrkgEmgyBrkSysSts 0 "PEBSysSts_Off" 1 "PEBSysSts_Standby" 2 "PEBSysSts_Inactivate" 3 "PEBSysSts_PEBactivate" 4 "PEBSysSts_MSPactivate" 5 "PEBSysSts_Failure" 6 "PEBSysSts_Inhibited" 7 "PEBSysSts_Initialze" 8 "PEBSysSts_Reserved1" 9 "PEBSysSts_Reserved2" 10 "PEBSysSts_Reserved3" 11 "PEBSysSts_Reserved4" 12 "PEBSysSts_Reserved5" 13 "PEBSysSts_Reserved6" 14 "PEBSysSts_Reserved7" 15 "PEBSysSts_Reserved8";
VAL_ 274 PrkgLockReq 0 "LockgCenReq2_Idle" 1 "LockgCenReq2_Unlck" 2 "LockgCenReq2_Lock";
VAL_ 274 PrkgStandstillReqReqSts1 0 "ReqSts1_NotReqd" 1 "ReqSts1_Reqd";
VAL_ 274 VehBeamLoModReq1 0 "VehBeamLoModReq1_NoRequest" 1 "VehBeamLoModReq1_RequestHiBeamOn" 2 "VehBeamLoModReq1_RequestHiBeamOff" 3 "VehBeamLoModReq1_RequestPuddleLightOn" 4 "VehBeamLoModReq1_RequestPuddleLightOff" 5 "VehBeamLoModReq1_AllRequestOff" 6 "VehBeamLoModReq1_Reserved1" 7 "VehBeamLoModReq1_Reserved2";
VAL_ 274 VoiceKeyPrkgSts 0 "OnOff1_Off" 1 "OnOff1_On";
VAL_ 1073 VFCVectorSODLVFCid0 0 "VFCOnOff_Off" 1 "VFCOnOff_On";
VAL_ 1073 VFCVectorSODLVFCid1 0 "VFCOnOff_Off" 1 "VFCOnOff_On";
VAL_ 1073 VFCVectorSODLVFCid10 0 "VFCOnOff_Off" 1 "VFCOnOff_On";
VAL_ 1073 VFCVectorSODLVFCid11 0 "VFCOnOff_Off" 1 "VFCOnOff_On";
VAL_ 1073 VFCVectorSODLVFCid12 0 "VFCOnOff_Off" 1 "VFCOnOff_On";
VAL_ 1073 VFCVectorSODLVFCid13 0 "VFCOnOff_Off" 1 "VFCOnOff_On";
VAL_ 1073 VFCVectorSODLVFCid14 0 "VFCOnOff_Off" 1 "VFCOnOff_On";
VAL_ 1073 VFCVectorSODLVFCid15 0 "VFCOnOff_Off" 1 "VFCOnOff_On";
VAL_ 1073 VFCVectorSODLVFCid16 0 "VFCOnOff_Off" 1 "VFCOnOff_On";
VAL_ 1073 VFCVectorSODLVFCid17 0 "VFCOnOff_Off" 1 "VFCOnOff_On";
VAL_ 1073 VFCVectorSODLVFCid18 0 "VFCOnOff_Off" 1 "VFCOnOff_On";
VAL_ 1073 VFCVectorSODLVFCid19 0 "VFCOnOff_Off" 1 "VFCOnOff_On";
VAL_ 1073 VFCVectorSODLVFCid2 0 "VFCOnOff_Off" 1 "VFCOnOff_On";
VAL_ 1073 VFCVectorSODLVFCid20 0 "VFCOnOff_Off" 1 "VFCOnOff_On";
VAL_ 1073 VFCVectorSODLVFCid21 0 "VFCOnOff_Off" 1 "VFCOnOff_On";
VAL_ 1073 VFCVectorSODLVFCid22 0 "VFCOnOff_Off" 1 "VFCOnOff_On";
VAL_ 1073 VFCVectorSODLVFCid23 0 "VFCOnOff_Off" 1 "VFCOnOff_On";
VAL_ 1073 VFCVectorSODLVFCid24 0 "VFCOnOff_Off" 1 "VFCOnOff_On";
VAL_ 1073 VFCVectorSODLVFCid25 0 "VFCOnOff_Off" 1 "VFCOnOff_On";
VAL_ 1073 VFCVectorSODLVFCid26 0 "VFCOnOff_Off" 1 "VFCOnOff_On";
VAL_ 1073 VFCVectorSODLVFCid27 0 "VFCOnOff_Off" 1 "VFCOnOff_On";
VAL_ 1073 VFCVectorSODLVFCid28 0 "VFCOnOff_Off" 1 "VFCOnOff_On";
VAL_ 1073 VFCVectorSODLVFCid29 0 "VFCOnOff_Off" 1 "VFCOnOff_On";
VAL_ 1073 VFCVectorSODLVFCid3 0 "VFCOnOff_Off" 1 "VFCOnOff_On";
VAL_ 1073 VFCVectorSODLVFCid30 0 "VFCOnOff_Off" 1 "VFCOnOff_On";
VAL_ 1073 VFCVectorSODLVFCid31 0 "VFCOnOff_Off" 1 "VFCOnOff_On";
VAL_ 1073 VFCVectorSODLVFCid32 0 "VFCOnOff_Off" 1 "VFCOnOff_On";
VAL_ 1073 VFCVectorSODLVFCid33 0 "VFCOnOff_Off" 1 "VFCOnOff_On";
VAL_ 1073 VFCVectorSODLVFCid34 0 "VFCOnOff_Off" 1 "VFCOnOff_On";
VAL_ 1073 VFCVectorSODLVFCid35 0 "VFCOnOff_Off" 1 "VFCOnOff_On";
VAL_ 1073 VFCVectorSODLVFCid36 0 "VFCOnOff_Off" 1 "VFCOnOff_On";
VAL_ 1073 VFCVectorSODLVFCid37 0 "VFCOnOff_Off" 1 "VFCOnOff_On";
VAL_ 1073 VFCVectorSODLVFCid38 0 "VFCOnOff_Off" 1 "VFCOnOff_On";
VAL_ 1073 VFCVectorSODLVFCid39 0 "VFCOnOff_Off" 1 "VFCOnOff_On";
VAL_ 1073 VFCVectorSODLVFCid4 0 "VFCOnOff_Off" 1 "VFCOnOff_On";
VAL_ 1073 VFCVectorSODLVFCid40 0 "VFCOnOff_Off" 1 "VFCOnOff_On";
VAL_ 1073 VFCVectorSODLVFCid41 0 "VFCOnOff_Off" 1 "VFCOnOff_On";
VAL_ 1073 VFCVectorSODLVFCid42 0 "VFCOnOff_Off" 1 "VFCOnOff_On";
VAL_ 1073 VFCVectorSODLVFCid43 0 "VFCOnOff_Off" 1 "VFCOnOff_On";
VAL_ 1073 VFCVectorSODLVFCid44 0 "VFCOnOff_Off" 1 "VFCOnOff_On";
VAL_ 1073 VFCVectorSODLVFCid45 0 "VFCOnOff_Off" 1 "VFCOnOff_On";
VAL_ 1073 VFCVectorSODLVFCid46 0 "VFCOnOff_Off" 1 "VFCOnOff_On";
VAL_ 1073 VFCVectorSODLVFCid47 0 "VFCOnOff_Off" 1 "VFCOnOff_On";
VAL_ 1073 VFCVectorSODLVFCid48 0 "VFCOnOff_Off" 1 "VFCOnOff_On";
VAL_ 1073 VFCVectorSODLVFCid49 0 "VFCOnOff_Off" 1 "VFCOnOff_On";
VAL_ 1073 VFCVectorSODLVFCid5 0 "VFCOnOff_Off" 1 "VFCOnOff_On";
VAL_ 1073 VFCVectorSODLVFCid50 0 "VFCOnOff_Off" 1 "VFCOnOff_On";
VAL_ 1073 VFCVectorSODLVFCid51 0 "VFCOnOff_Off" 1 "VFCOnOff_On";
VAL_ 1073 VFCVectorSODLVFCid52 0 "VFCOnOff_Off" 1 "VFCOnOff_On";
VAL_ 1073 VFCVectorSODLVFCid53 0 "VFCOnOff_Off" 1 "VFCOnOff_On";
VAL_ 1073 VFCVectorSODLVFCid54 0 "VFCOnOff_Off" 1 "VFCOnOff_On";
VAL_ 1073 VFCVectorSODLVFCid55 0 "VFCOnOff_Off" 1 "VFCOnOff_On";
VAL_ 1073 VFCVectorSODLVFCid56 0 "VFCOnOff_Off" 1 "VFCOnOff_On";
VAL_ 1073 VFCVectorSODLVFCid57 0 "VFCOnOff_Off" 1 "VFCOnOff_On";
VAL_ 1073 VFCVectorSODLVFCid58 0 "VFCOnOff_Off" 1 "VFCOnOff_On";
VAL_ 1073 VFCVectorSODLVFCid59 0 "VFCOnOff_Off" 1 "VFCOnOff_On";
VAL_ 1073 VFCVectorSODLVFCid6 0 "VFCOnOff_Off" 1 "VFCOnOff_On";
VAL_ 1073 VFCVectorSODLVFCid60 0 "VFCOnOff_Off" 1 "VFCOnOff_On";
VAL_ 1073 VFCVectorSODLVFCid61 0 "VFCOnOff_Off" 1 "VFCOnOff_On";
VAL_ 1073 VFCVectorSODLVFCid7 0 "VFCOnOff_Off" 1 "VFCOnOff_On";
VAL_ 1073 VFCVectorSODLVFCid8 0 "VFCOnOff_Off" 1 "VFCOnOff_On";
VAL_ 1073 VFCVectorSODLVFCid9 0 "VFCOnOff_Off" 1 "VFCOnOff_On";
SIG_GROUP_ 86 BiasedPosnFromSatlt 1 : BiasedPosnFromSatltCntr BiasedPosnFromSatltPosnLat BiasedPosnFromSatltPosnLgt BiasedPosnFromSatltTiForMins BiasedPosnFromSatltTiForMsec BiasedPosnFromSatltTiForSec;
SIG_GROUP_ 832 BiasedPosnFromSatlt1 1 : BiasedPosnFromSatlt1Cntr BiasedPosnFromSatlt1PosnLat BiasedPosnFromSatlt1PosnLgt;
SIG_GROUP_ 373 CrossInfo 1 : CrossInfoDirOfNavRut CrossInfoDstToCros CrossInfoTrfcLi;
SIG_GROUP_ 373 DrvrACCFctDeactvnReq 1 : DrvrACCFctDeactvnReqChks DrvrACCFctDeactvnReqCntr DrvrACCFctDeactvnReqSts;
SIG_GROUP_ 87 DrvrACCrsSetSpdReq 1 : DrvrACCrsSetSpdReqDrvrACCrsCtrlSetInSpdReq DrvrACCrsSetSpdReqDrvrCrsSetSpdReq DrvrACCrsSetSpdReqSetSpdForCrsCtrlFctActive;
SIG_GROUP_ 488 EyeGazeDirVecFromDHU 1 : EyeGazeDirVecFromDHUX EyeGazeDirVecFromDHUY EyeGazeDirVecFromDHUZ;
SIG_GROUP_ 488 EyeGazeFromDHU 1 : EyeGazeFromDHUEyeGazeZone EyeGazeFromDHUEyeGazeZoneTime;
SIG_GROUP_ 488 EyeGzaeDirOriFromDHU 1 : EyeGzaeDirOriFromDHUX EyeGzaeDirOriFromDHUY EyeGzaeDirOriFromDHUZ;
SIG_GROUP_ 488 EyeOnRoadFromDHU 1 : EyeOnRoadFromDHUChks EyeOnRoadFromDHUCntr EyeOnRoadFromDHUEyesOnRoad;
SIG_GROUP_ 488 EyeOpenFromDHU 1 : EyeOpenFromDHUEyeOpenDegLe EyeOpenFromDHUEyeOpenDegRi EyeOpenFromDHUEyeOpenLe EyeOpenFromDHUEyeOpenRi EyeOpenFromDHUEyeVisibleLe EyeOpenFromDHUEyeVisibleRi EyeOpenFromDHUFaceVisible;
SIG_GROUP_ 86 FuLvlIndcd 1 : FuLvlIndcdFuLvlValFromFuTbl FuLvlIndcdGenQF;
SIG_GROUP_ 96 GearPrkgAssiReqGroup 1 : GearPrkgAssiReqGroupChks GearPrkgAssiReqGroupCntr GearPrkgAssiReqGroupGearPrkgAssiReq1;
SIG_GROUP_ 775 GNSSSolution 1 : GNSSSolutionCntr GNSSSolutionNoOfSatltForSysNo1 GNSSSolutionNoOfSatltForSysNo2 GNSSSolutionNoOfSatltForSysNo3 GNSSSolutionNoOfSatltForSysNo4 GNSSSolutionNoOfSatltForSysNo5 GNSSSolutionNoOfSatltForSysNo6 GNSSSolutionNoOfSatltForSysNo7 GNSSSolutionPreHozlDil GNSSSolutionPrePosnDil GNSSSolutionPreVertDil GNSSSolutionSatltPosnStsPrm1 GNSSSolutionSatltPosnStsPrm2 GNSSSolutionSatltSysNo1InUse GNSSSolutionSatltSysNo2InUse GNSSSolutionSatltSysNo3InUse GNSSSolutionSatltSysNo4InUse GNSSSolutionSatltSysNo5InUse GNSSSolutionSatltSysNo6InUse GNSSSolutionSatltSysNo7InUse GNSSSolutionTiForMins GNSSSolutionTiForMsec GNSSSolutionTiForSec;
SIG_GROUP_ 775 GNSSSolution1 1 : GNSSSolution1Cntr GNSSSolution1NoOfSatItForSysNo1 GNSSSolution1NoOfSatItForSysNo2 GNSSSolution1NoOfSatItForSysNo3 GNSSSolution1NoOfSatItForSysNo4 GNSSSolution1NoOfSatItForSysNo5 GNSSSolution1NoOfSatItForSysNo6 GNSSSolution1NoOfSatItForSysNo7 GNSSSolution1SatItSysNo1InUse GNSSSolution1SatItSysNo2InUse GNSSSolution1SatItSysNo3InUse GNSSSolution1SatItSysNo4InUse GNSSSolution1SatItSysNo5InUse GNSSSolution1SatItSysNo6InUse GNSSSolution1SatItSysNo7InUse GNSSSolution1SatltPosnStsPrm1 GNSSSolution1SatltPosnStsPrm2;
SIG_GROUP_ 775 GNSSSolution2 1 : GNSSSolution2Cntr GNSSSolution2PreHozlDil GNSSSolution2PrePosnDil GNSSSolution2PreVertDil;
SIG_GROUP_ 488 HdPosnValidSigFromDHU 1 : HdPosnValidSigFromDHUX HdPosnValidSigFromDHUY HdPosnValidSigFromDHUZ;
SIG_GROUP_ 488 HdRotateAgFromDHU 1 : HdRotateAgFromDHUHdPitchAg HdRotateAgFromDHUHdRollAg HdRotateAgFromDHUHdYawAg;
SIG_GROUP_ 488 HeadGazeDirOriFromDHU 1 : HeadGazeDirOriFromDHUX HeadGazeDirOriFromDHUY HeadGazeDirOriFromDHUZ;
SIG_GROUP_ 488 HeadGazeDirVecFromDHU 1 : HeadGazeDirVecFromDHUX HeadGazeDirVecFromDHUY HeadGazeDirVecFromDHUZ;
SIG_GROUP_ 373 HmiStrangerModMenuSet 1 : HmiStrangerModMenuSetActvInActv HmiStrangerModMenuSetPasswordSt HmiStrangerModMenuSetPrivateLockSt HmiStrangerModMenuSetSpdLim;
SIG_GROUP_ 751 HznData 1 : HznDataCountryCode HznDataCyclicCounter HznDataDrivingSide HznDataHardwareVersion HznDataMajorProtocolVersion HznDataMapProvider HznDataMapVersionYear HznDataMapVersionYearQuarter HznDataMessageType HznDataMinorProtocolSubVersion HznDataMinorProtocolVersion HznDataRegionCode HznDataSpeedUnits;
SIG_GROUP_ 824 HznEdge 1 : HznEdgeComplexIntersection HznEdgeCyclicCounter HznEdgeFormOfWay HznEdgeFunctionalRoadClass HznEdgeLastStubAtOffset HznEdgeMessageType HznEdgeNumberOfLanesInDrivingDirection HznEdgeNumberOfLanesInOppositeDirection HznEdgeOffset HznEdgePartOfCalculatedRoute HznEdgePathIndex HznEdgeRelativeProbability HznEdgeRetransmission HznEdgeRightofWay HznEdgeSubPathIndex HznEdgeTurnAngle HznEdgeUpdate;
SIG_GROUP_ 488 HznPosn 1 : HznPosnCurrentLane HznPosnCyclicCounter HznPosnMessageType HznPosnOffset HznPosnPathIndex HznPosnPositionAge HznPosnPositionConfidence HznPosnPositionIndex HznPosnPositionProbability HznPosnRelativeHeading HznPosnSpeed;
SIG_GROUP_ 824 HznProfLong 1 : HznProfLongControlPoint HznProfLongCyclicCounter HznProfLongMessageType HznProfLongOffset HznProfLongPathIndex HznProfLongProfileType HznProfLongRetransmission HznProfLongUpdate HznProfLongValue;
SIG_GROUP_ 824 HznProfSho 1 : HznProfShoAccuracy HznProfShoControlPoint HznProfShoCyclicCounter HznProfShoDistance1 HznProfShoMessageType HznProfShoOffset HznProfShoPathIndex HznProfShoProfileType HznProfShoRetransmission HznProfShoUpdate HznProfShoValue0 HznProfShoValue1;
SIG_GROUP_ 824 HznSeg 1 : HznSegBridge HznSegBuiltupArea HznSegComplexIntersection HznSegCyclicCounter HznSegDividedRoad HznSegEffectiveSpdLimit HznSegEffectiveSpeedLimitType HznSegFormofWay HznSegFunctionalRoadClass HznSegMessageType HznSegNumberoflanesindrivingdirection HznSegNumberoflanesinoppositedirection HznSegOffset HznSegPartOfCalculatedRoute HznSegPathIndex HznSegRelativeProbability HznSegRetransmission HznSegTunnel HznSegUpdate;
SIG_GROUP_ 751 IndcnUnit 1 : IndcnUnitClkFmt IndcnUnitDateFmt IndcnUnitDstLong IndcnUnitDstSho IndcnUnitFuCnsUnit IndcnUnitPUnit IndcnUnitSpdUnit IndcnUnitTUnit IndcnUnitVolUnit;
SIG_GROUP_ 889 ListOfNodAv 1 : ListOfNodAv1 ListOfNodAv2 ListOfNodAv3 ListOfNodAv4 ListOfNodAv5 ListOfNodAv6 ListOfNodAv7 ListOfNodAv8;
SIG_GROUP_ 373 MobDevRPAReq1 1 : MobDevRPAReq1Chks MobDevRPAReq1Cntr MobDevRPAReq1MobDevSts MobDevRPAReq1RPAOutModeSubT MobDevRPAReq1RPAReq MobDevRPAReq1RSPACtrl;
SIG_GROUP_ 352 PosnFromSatlt 1 : PosnFromSatltCntr PosnFromSatltPosnAlti PosnFromSatltPosnDir PosnFromSatltPosnLat PosnFromSatltPosnLgt PosnFromSatltPosnSpd PosnFromSatltPosnVHozl PosnFromSatltPosnVVert PosnFromSatltTiForMins PosnFromSatltTiForMsec PosnFromSatltTiForSec PosnFromSatltUTCForDay PosnFromSatltUTCForHr PosnFromSatltUTCForMins PosnFromSatltUTCForMth PosnFromSatltUTCForSec PosnFromSatltUTCForYr;
SIG_GROUP_ 775 PosnFromSatlt1 1 : PosnFromSatlt1Cntr PosnFromSatlt1PosnLat PosnFromSatlt1PosnLgt;
SIG_GROUP_ 832 PosnFromSatlt2 1 : PosnFromSatlt2Cntr PosnFromSatlt2PosnSpdosn;
SIG_GROUP_ 832 PosnFromSatlt3 1 : PosnFromSatlt3Cntr PosnFromSatlt3PosnAlti PosnFromSatlt3PosnDir PosnFromSatlt3TiForMins PosnFromSatlt3TiForMsec PosnFromSatlt3TiForSec;
SIG_GROUP_ 274 PrkgAccrOvrdnCtrlReqgrp 1 : PrkgAccrOvrdnCtrlReqgrpChks PrkgAccrOvrdnCtrlReqgrpCntr PrkgAccrOvrdnCtrlReqgrpPrkgAccrOvrdnCtrlReq;
SIG_GROUP_ 96 PrkgAssiElectcStabyProgCtrlModReqGroup 1 : PrkgAssiElectcStabyProgCtrlModReqGroupChks PrkgAssiElectcStabyProgCtrlModReqGroupCntr PrkgAssiElectcStabyProgCtrlModReqGroupPASElectcStabyProgCtrlModReq;
SIG_GROUP_ 274 PrkgBrkElectcCtrlReq 1 : PrkgBrkElectcCtrlReqChks PrkgBrkElectcCtrlReqCntr PrkgBrkElectcCtrlReqReq;
SIG_GROUP_ 96 PrkgSpdCtrlSafeGroup 1 : PrkgSpdCtrlSafeGroupChks PrkgSpdCtrlSafeGroupCntr PrkgSpdCtrlSafeGroupDrvrAsscSysBrkFctMod PrkgSpdCtrlSafeGroupPrkgAssiALowrLim PrkgSpdCtrlSafeGroupPrkgAssiALowrSlop PrkgSpdCtrlSafeGroupPrkgAssiAReq1 PrkgSpdCtrlSafeGroupPrkgAssiAUpprLim PrkgSpdCtrlSafeGroupPrkgAssiAUpprSlop;
SIG_GROUP_ 274 PrkgStandstillReq 1 : PrkgStandstillReqChks PrkgStandstillReqCntr PrkgStandstillReqReqSts1;
SIG_GROUP_ 528 PrkgStsToEDR 1 : PrkgStsToEDRAPATo PrkgStsToEDRHPATo PrkgStsToEDRLSDAandTBATo PrkgStsToEDRreserved1 PrkgStsToEDRreserved2 PrkgStsToEDRreserved3 PrkgStsToEDRRPATo;
SIG_GROUP_ 352 RampInfo 1 : RampInfoDstToRamp RampInfoEnterRamp;
SIG_GROUP_ 504 SftySigGroupFromHmiSafe1 1 : SftySigGroupFromHmiSafe1SftyHmiDend SftySigGroupFromHmiSafe1SftyHmiEna SftySigGroupFromHmiSafe1SftySigFaildDetdByHmi SftySigGroupFromHmiSafe1SftySigGroupFromHmiSafeChks SftySigGroupFromHmiSafe1SftySigGroupFromHmiSafeCntr;
SIG_GROUP_ 337 TripResetSyncMsg 1 : TripResetSyncMsgAuthenticator TripResetSyncMsgResetcounter TripResetSyncMsgTripcounter;
SIG_GROUP_ 373 VehCfgPrm 1 : VehCfgPrmBlkIDBytePosn1 VehCfgPrmCCPBytePosn2 VehCfgPrmCCPBytePosn3 VehCfgPrmCCPBytePosn4 VehCfgPrmCCPBytePosn5 VehCfgPrmCCPBytePosn6 VehCfgPrmCCPBytePosn7 VehCfgPrmCCPBytePosn8;
SIG_GROUP_ 501 VehCfgPrmExt 1 : VehCfgPrmExtBlkIDBytePosn1 VehCfgPrmExtCCPBytePosn2 VehCfgPrmExtCCPBytePosn3 VehCfgPrmExtCCPBytePosn4 VehCfgPrmExtCCPBytePosn5 VehCfgPrmExtCCPBytePosn6 VehCfgPrmExtCCPBytePosn7 VehCfgPrmExtCCPBytePosn8;
SIG_GROUP_ 352 VehSpdIndcd 1 : VehSpdIndcdVehSpdIndcd VehSpdIndcdVeSpdIndcdUnit;
SIG_GROUP_ 1384 VFCVectorBCM 1 : VFCVectorBCMBlockID VFCVectorBCMVFCid0 VFCVectorBCMVFCid1 VFCVectorBCMVFCid10 VFCVectorBCMVFCid11 VFCVectorBCMVFCid12 VFCVectorBCMVFCid13 VFCVectorBCMVFCid14 VFCVectorBCMVFCid15 VFCVectorBCMVFCid16 VFCVectorBCMVFCid17 VFCVectorBCMVFCid18 VFCVectorBCMVFCid19 VFCVectorBCMVFCid2 VFCVectorBCMVFCid20 VFCVectorBCMVFCid21 VFCVectorBCMVFCid22 VFCVectorBCMVFCid23 VFCVectorBCMVFCid24 VFCVectorBCMVFCid25 VFCVectorBCMVFCid26 VFCVectorBCMVFCid27 VFCVectorBCMVFCid28 VFCVectorBCMVFCid29 VFCVectorBCMVFCid3 VFCVectorBCMVFCid30 VFCVectorBCMVFCid31 VFCVectorBCMVFCid32 VFCVectorBCMVFCid33 VFCVectorBCMVFCid34 VFCVectorBCMVFCid35 VFCVectorBCMVFCid36 VFCVectorBCMVFCid37 VFCVectorBCMVFCid38 VFCVectorBCMVFCid39 VFCVectorBCMVFCid4 VFCVectorBCMVFCid40 VFCVectorBCMVFCid41 VFCVectorBCMVFCid42 VFCVectorBCMVFCid43 VFCVectorBCMVFCid44 VFCVectorBCMVFCid45 VFCVectorBCMVFCid46 VFCVectorBCMVFCid47 VFCVectorBCMVFCid48 VFCVectorBCMVFCid49 VFCVectorBCMVFCid5 VFCVectorBCMVFCid50 VFCVectorBCMVFCid51 VFCVectorBCMVFCid52 VFCVectorBCMVFCid53 VFCVectorBCMVFCid54 VFCVectorBCMVFCid55 VFCVectorBCMVFCid56 VFCVectorBCMVFCid57 VFCVectorBCMVFCid58 VFCVectorBCMVFCid59 VFCVectorBCMVFCid6 VFCVectorBCMVFCid60 VFCVectorBCMVFCid61 VFCVectorBCMVFCid7 VFCVectorBCMVFCid8 VFCVectorBCMVFCid9;
SIG_GROUP_ 1073 VFCVectorSODL 1 : VFCVectorSODLBlockID VFCVectorSODLVFCid0 VFCVectorSODLVFCid1 VFCVectorSODLVFCid10 VFCVectorSODLVFCid11 VFCVectorSODLVFCid12 VFCVectorSODLVFCid13 VFCVectorSODLVFCid14 VFCVectorSODLVFCid15 VFCVectorSODLVFCid16 VFCVectorSODLVFCid17 VFCVectorSODLVFCid18 VFCVectorSODLVFCid19 VFCVectorSODLVFCid2 VFCVectorSODLVFCid20 VFCVectorSODLVFCid21 VFCVectorSODLVFCid22 VFCVectorSODLVFCid23 VFCVectorSODLVFCid24 VFCVectorSODLVFCid25 VFCVectorSODLVFCid26 VFCVectorSODLVFCid27 VFCVectorSODLVFCid28 VFCVectorSODLVFCid29 VFCVectorSODLVFCid3 VFCVectorSODLVFCid30 VFCVectorSODLVFCid31 VFCVectorSODLVFCid32 VFCVectorSODLVFCid33 VFCVectorSODLVFCid34 VFCVectorSODLVFCid35 VFCVectorSODLVFCid36 VFCVectorSODLVFCid37 VFCVectorSODLVFCid38 VFCVectorSODLVFCid39 VFCVectorSODLVFCid4 VFCVectorSODLVFCid40 VFCVectorSODLVFCid41 VFCVectorSODLVFCid42 VFCVectorSODLVFCid43 VFCVectorSODLVFCid44 VFCVectorSODLVFCid45 VFCVectorSODLVFCid46 VFCVectorSODLVFCid47 VFCVectorSODLVFCid48 VFCVectorSODLVFCid49 VFCVectorSODLVFCid5 VFCVectorSODLVFCid50 VFCVectorSODLVFCid51 VFCVectorSODLVFCid52 VFCVectorSODLVFCid53 VFCVectorSODLVFCid54 VFCVectorSODLVFCid55 VFCVectorSODLVFCid56 VFCVectorSODLVFCid57 VFCVectorSODLVFCid58 VFCVectorSODLVFCid59 VFCVectorSODLVFCid6 VFCVectorSODLVFCid60 VFCVectorSODLVFCid61 VFCVectorSODLVFCid7 VFCVectorSODLVFCid8 VFCVectorSODLVFCid9;
SIG_GROUP_ 501 Vin 1 : VinBlockNr VinVINSignalPos1 VinVINSignalPos2 VinVINSignalPos3 VinVINSignalPos4 VinVINSignalPos5 VinVINSignalPos6 VinVINSignalPos7;
